VERSION ""

NS_ :

BS_:

BU_: IVI

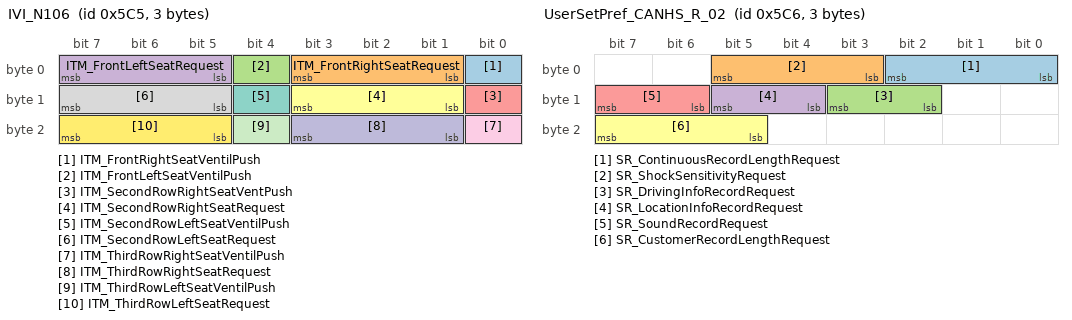
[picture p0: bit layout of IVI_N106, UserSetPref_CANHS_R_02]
BO_ 1477 IVI_N106: 3 IVI
  SG_ ITM_FrontRightSeatVentilPush : 0|1@0+ (1,0) [0|1] "-" Vector__XXX
  SG_ ITM_FrontRightSeatRequest : 3|3@0+ (1,0) [0|0] "" Vector__XXX
  SG_ ITM_FrontLeftSeatVentilPush : 4|1@0+ (1,0) [0|1] "-" Vector__XXX
  SG_ ITM_FrontLeftSeatRequest : 7|3@0+ (1,0) [0|0] "" Vector__XXX
  SG_ ITM_SecondRowRightSeatVentPush : 8|1@0+ (1,0) [0|1] "-" Vector__XXX
  SG_ ITM_SecondRowRightSeatRequest : 11|3@0+ (1,0) [0|0] "" Vector__XXX
  SG_ ITM_SecondRowLeftSeatVentilPush : 12|1@0+ (1,0) [0|1] "-" Vector__XXX
  SG_ ITM_SecondRowLeftSeatRequest : 15|3@0+ (1,0) [0|0] "" Vector__XXX
  SG_ ITM_ThirdRowRightSeatVentilPush : 16|1@0+ (1,0) [0|1] "-" Vector__XXX
  SG_ ITM_ThirdRowRightSeatRequest : 19|3@0+ (1,0) [0|0] "" Vector__XXX
  SG_ ITM_ThirdRowLeftSeatVentilPush : 20|1@0+ (1,0) [0|1] "-" Vector__XXX
  SG_ ITM_ThirdRowLeftSeatRequest : 23|3@0+ (1,0) [0|0] "" Vector__XXX

BO_ 1478 UserSetPref_CANHS_R_02: 3 IVI
  SG_ SR_ContinuousRecordLengthRequest : 2|3@0+ (1,0) [0|0] "" Vector__XXX
  SG_ SR_ShockSensitivityRequest : 5|3@0+ (1,0) [0|0] "" Vector__XXX
  SG_ SR_DrivingInfoRecordRequest : 11|2@0+ (1,0) [0|0] "" Vector__XXX
  SG_ SR_LocationInfoRecordRequest : 13|2@0+ (1,0) [0|0] "" Vector__XXX
  SG_ SR_SoundRecordRequest : 15|2@0+ (1,0) [0|0] "" Vector__XXX
  SG_ SR_CustomerRecordLengthRequest : 23|3@0+ (1,0) [0|0] "" Vector__XXX

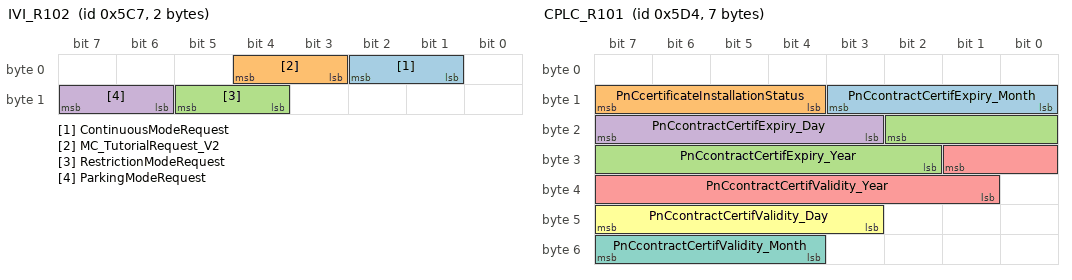
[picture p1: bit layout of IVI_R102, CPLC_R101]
BO_ 1479 IVI_R102: 2 IVI
  SG_ ContinuousModeRequest : 2|2@0+ (1,0) [0|0] "" Vector__XXX
  SG_ MC_TutorialRequest_V2 : 4|2@0+ (1,0) [0|0] "" Vector__XXX
  SG_ RestrictionModeRequest : 13|2@0+ (1,0) [0|0] "" Vector__XXX
  SG_ ParkingModeRequest : 15|2@0+ (1,0) [0|0] "" Vector__XXX

BO_ 1482 IVI_UserSetPref_A2: 8 IVI
  SG_ TSR_OSPActivationRequest2 : 1|2@0+ (1,0) [0|0] "" Vector__XXX
  SG_ TPMS_PressureFrontAxleRequest2 : 7|6@0+ (10,140) [150|760] "kPa" Vector__XXX
  SG_ TPMS_PressureRearAxleRequest2 : 15|6@0+ (10,140) [150|760] "kPa" Vector__XXX
  SG_ LDW_ActivationRequest2 : 17|2@0+ (1,0) [0|0] "" Vector__XXX
  SG_ LDW_VibrationIntensityReq2 : 20|3@0+ (1,0) [0|0] "" Vector__XXX
  SG_ SailingStopActivationRequest2 : 25|2@0+ (1,0) [0|0] "" Vector__XXX
  SG_ AEB_FCWactivationRequest2 : 28|3@0+ (1,0) [0|0] "" Vector__XXX
  SG_ LDW_SensibilityRequest2 : 31|3@0+ (1,0) [0|0] "" Vector__XXX
  SG_ FKP_ActivationRequest2 : 33|2@0+ (1,0) [0|0] "" Vector__XXX
  SG_ MOD_ActivationRequest2 : 35|2@0+ (1,0) [0|0] "" Vector__XXX
  SG_ SonarAutoDisplayRequest2 : 37|2@0+ (1,0) [0|0] "" Vector__XXX
  SG_ DW_ActivationRequest2 : 39|2@0+ (1,0) [0|0] "" Vector__XXX
  SG_ BSWrad_ActivationRequest2 : 41|2@0+ (1,0) [0|0] "" Vector__XXX
  SG_ HFP_DefaultManeuverTypeRequest2 : 44|3@0+ (1,0) [0|0] "" Vector__XXX
  SG_ HandDrivingActivationRequest2 : 47|2@0+ (1,0) [0|0] "" Vector__XXX
  SG_ LKA_ActivationRequest2 : 51|2@0+ (1,0) [0|0] "" Vector__XXX
  SG_ SailingIdleActivationReq2 : 53|2@0+ (1,0) [0|0] "" Vector__XXX
  SG_ CTA_ActivationRequest2 : 59|2@0+ (1,0) [0|0] "" Vector__XXX
  SG_ AFS_ActivationRequest2 : 61|2@0+ (1,0) [0|0] "" Vector__XXX
  SG_ LCA_ActivationRequest2 : 63|2@0+ (1,0) [0|0] "" Vector__XXX

BO_ 1488 ADAS_A110: 8 Vector__XXX
  SG_ OffsetActivation_State : 18|2@0+ (1,0) [0|0] "" IVI
  SG_ OffsetValue_State : 52|5@0+ (1,0) [0|0] "" IVI

BO_ 1490 HUD_A101: 2 Vector__XXX
  SG_ HUD_RotationPositionState : 7|5@0+ (1,0) [0|0] "" IVI
  SG_ HUD_FOTA_status : 15|5@0+ (1,0) [0|0] "" IVI

BO_ 1491 METER_UserSetPref_A1: 8 Vector__XXX
  SG_ ParkAssistVolumeRequest : 7|3@0+ (1,0) [0|0] "" IVI

BO_ 1492 CPLC_R101: 7 Vector__XXX
  SG_ PnCcontractCertifExpiry_Month : 11|4@0+ (1,0) [0|12] "month" IVI
  SG_ PnCcertificateInstallationStatus : 15|4@0+ (1,0) [0|0] "" IVI
  SG_ PnCcontractCertifExpiry_Year : 18|9@0+ (1,2000) [2000|2500] "year" IVI
  SG_ PnCcontractCertifExpiry_Day : 23|5@0+ (1,0) [0|31] "day" IVI
  SG_ PnCcontractCertifValidity_Year : 25|9@0+ (1,2000) [2000|2500] "year" IVI
  SG_ PnCcontractCertifValidity_Day : 47|5@0+ (1,0) [0|31] "day" IVI
  SG_ PnCcontractCertifValidity_Month : 55|4@0+ (1,0) [0|12] "month" IVI

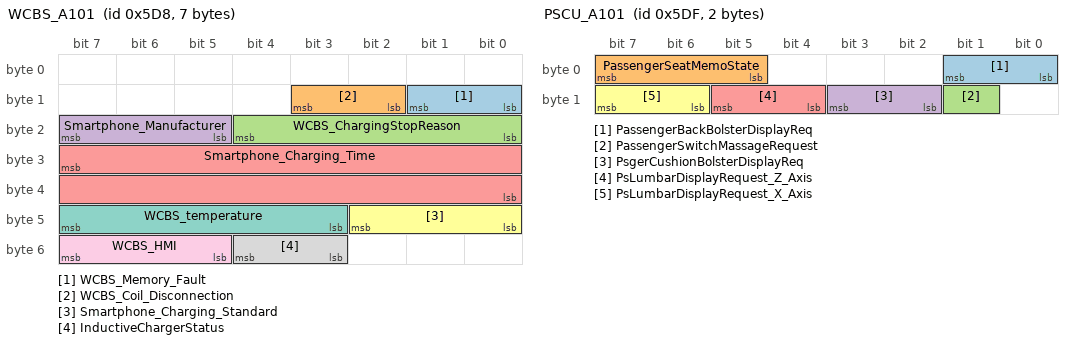
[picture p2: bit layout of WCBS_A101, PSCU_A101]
BO_ 1496 WCBS_A101: 7 Vector__XXX
  SG_ WCBS_Memory_Fault : 9|2@0+ (1,0) [0|0] "" IVI
  SG_ WCBS_Coil_Disconnection : 11|2@0+ (1,0) [0|0] "" IVI
  SG_ WCBS_ChargingStopReason : 20|5@0+ (1,0) [0|0] "" IVI
  SG_ Smartphone_Manufacturer : 23|3@0+ (1,0) [0|0] "" IVI
  SG_ Smartphone_Charging_Time : 31|16@0+ (1,1) [1|36000] "s" IVI
  SG_ Smartphone_Charging_Standard : 42|3@0+ (1,0) [0|0] "" IVI
  SG_ WCBS_temperature : 47|5@0+ (5,0) [0|100] "°C" IVI
  SG_ InductiveChargerStatus : 52|2@0+ (1,0) [0|0] "" IVI
  SG_ WCBS_HMI : 55|3@0+ (1,0) [0|0] "" IVI

BO_ 1498 ADAS_A155: 3 Vector__XXX
  SG_ AD_DistanceDuration : 7|14@0+ (0.1,-0.1) [0|1638] "km" IVI
  SG_ AD_TimeDuration : 9|10@0+ (1,1) [1|1022] "min" IVI

BO_ 1503 PSCU_A101: 2 Vector__XXX
  SG_ PassengerBackBolsterDisplayReq : 1|2@0+ (1,0) [0|0] "" IVI
  SG_ PassengerSeatMemoState : 7|3@0+ (1,0) [0|0] "" IVI
  SG_ PassengerSwitchMassageRequest : 9|1@0+ (1,0) [0|0] "" IVI
  SG_ PsgerCushionBolsterDisplayReq : 11|2@0+ (1,0) [0|0] "" IVI
  SG_ PsLumbarDisplayRequest_Z_Axis : 13|2@0+ (1,0) [0|0] "" IVI
  SG_ PsLumbarDisplayRequest_X_Axis : 15|2@0+ (1,0) [0|0] "" IVI

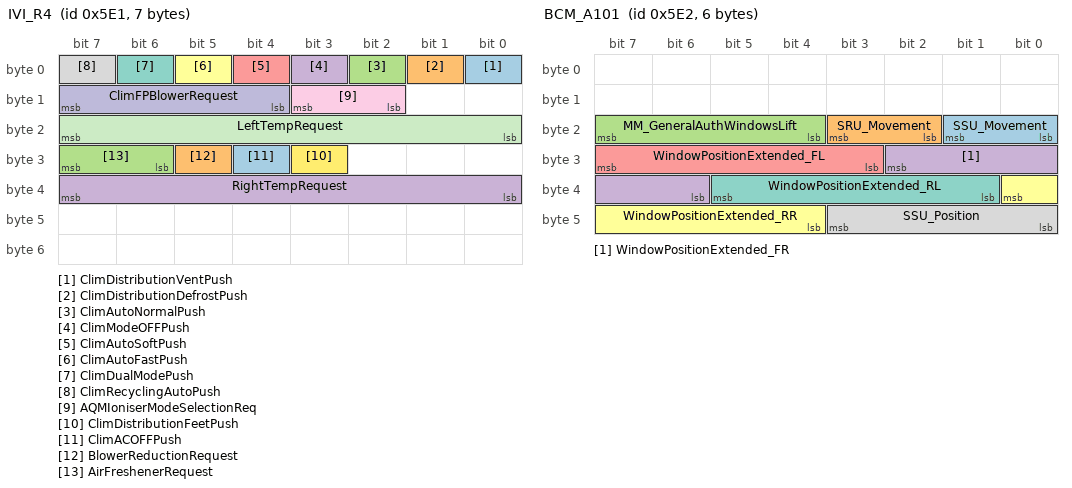
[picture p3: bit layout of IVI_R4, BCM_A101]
BO_ 1505 IVI_R4: 7 IVI
  SG_ ClimDistributionVentPush : 0|1@0+ (1,0) [0|1] "" Vector__XXX
  SG_ ClimDistributionDefrostPush : 1|1@0+ (1,0) [0|1] "" Vector__XXX
  SG_ ClimAutoNormalPush : 2|1@0+ (1,0) [0|1] "" Vector__XXX
  SG_ ClimModeOFFPush : 3|1@0+ (1,0) [0|1] "" Vector__XXX
  SG_ ClimAutoSoftPush : 4|1@0+ (1,0) [0|1] "" Vector__XXX
  SG_ ClimAutoFastPush : 5|1@0+ (1,0) [0|1] "" Vector__XXX
  SG_ ClimDualModePush : 6|1@0+ (1,0) [0|1] "" Vector__XXX
  SG_ ClimRecyclingAutoPush : 7|1@0+ (1,0) [0|1] "" Vector__XXX
  SG_ AQMIoniserModeSelectionReq : 11|2@0+ (1,0) [0|0] "" Vector__XXX
  SG_ ClimFPBlowerRequest : 15|4@0+ (1,0) [0|0] "" Vector__XXX
  SG_ LeftTempRequest : 23|8@0+ (0.5,10) [10|127.5] "°" Vector__XXX
  SG_ ClimDistributionFeetPush : 27|1@0+ (1,0) [0|1] "" Vector__XXX
  SG_ ClimACOFFPush : 28|1@0+ (1,0) [0|1] "" Vector__XXX
  SG_ BlowerReductionRequest : 29|1@0+ (1,0) [0|0] "" Vector__XXX
  SG_ AirFreshenerRequest : 31|2@0+ (1,0) [0|0] "" Vector__XXX
  SG_ RightTempRequest : 39|8@0+ (0.5,10) [10|127.5] "°" Vector__XXX

BO_ 1506 BCM_A101: 6 Vector__XXX
  SG_ SSU_Movement : 17|2@0+ (1,0) [0|0] "" IVI
  SG_ SRU_Movement : 19|2@0+ (1,0) [0|0] "" IVI
  SG_ MM_GeneralAuthWindowsLift : 23|4@0+ (1,0) [0|0] "" IVI
  SG_ WindowPositionExtended_FR : 26|5@0+ (1,0) [0|0] "" IVI
  SG_ WindowPositionExtended_FL : 31|5@0+ (1,0) [0|0] "" IVI
  SG_ WindowPositionExtended_RR : 32|5@0+ (1,0) [0|0] "" IVI
  SG_ WindowPositionExtended_RL : 37|5@0+ (1,0) [0|0] "" IVI
  SG_ SSU_Position : 43|4@0+ (1,0) [0|0] "" IVI

BO_ 1508 BCM_A115: 8 Vector__XXX
  SG_ RESPreSoak_ProgStatus : 9|2@0+ (1,0) [0|0] "" IVI
  SG_ RES_ProgrammationForbidden : 60|1@0+ (1,0) [0|0] "" IVI

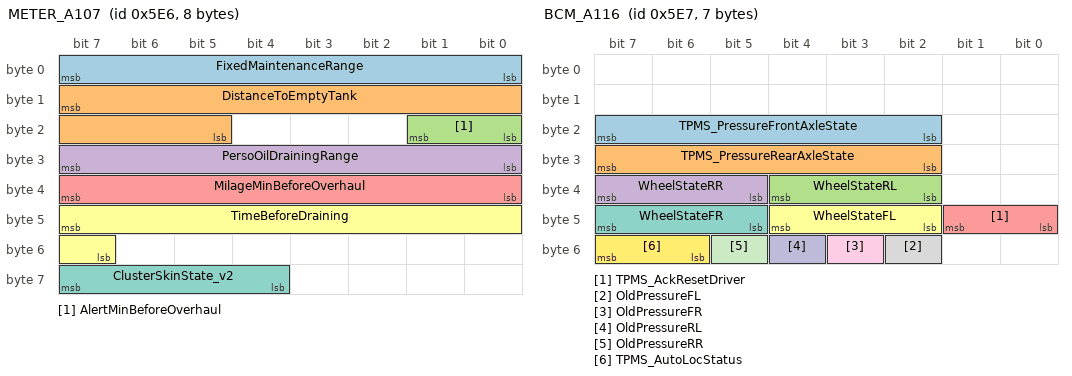
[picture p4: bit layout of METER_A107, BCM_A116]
BO_ 1510 METER_A107: 8 Vector__XXX
  SG_ FixedMaintenanceRange : 7|8@0+ (250,0) [0|63250] "km" IVI
  SG_ DistanceToEmptyTank : 15|11@0+ (1,0) [0|2046] "km" IVI
  SG_ AlertMinBeforeOverhaul : 17|2@0+ (1,0) [0|0] "" IVI
  SG_ PersoOilDrainingRange : 31|8@0+ (250,0) [0|63500] "km" IVI
  SG_ MilageMinBeforeOverhaul : 39|8@0+ (250,0) [0|63500] "km" IVI
  SG_ TimeBeforeDraining : 47|9@0+ (1,0) [0|511] "day" IVI
  SG_ ClusterSkinState_v2 : 63|4@0+ (1,0) [0|0] "" IVI

BO_ 1511 BCM_A116: 7 Vector__XXX
  SG_ TPMS_PressureFrontAxleState : 23|6@0+ (10,150) [150|760] "kPa" IVI
  SG_ TPMS_PressureRearAxleState : 31|6@0+ (10,150) [150|760] "kPa" IVI
  SG_ WheelStateRL : 36|3@0+ (1,0) [0|0] "" IVI
  SG_ WheelStateRR : 39|3@0+ (1,0) [0|0] "" IVI
  SG_ TPMS_AckResetDriver : 41|2@0+ (1,0) [0|0] "" IVI
  SG_ WheelStateFL : 44|3@0+ (1,0) [0|0] "" IVI
  SG_ WheelStateFR : 47|3@0+ (1,0) [0|0] "" IVI
  SG_ OldPressureFL : 50|1@0+ (1,0) [0|0] "" IVI
  SG_ OldPressureFR : 51|1@0+ (1,0) [0|0] "" IVI
  SG_ OldPressureRL : 52|1@0+ (1,0) [0|0] "" IVI
  SG_ OldPressureRR : 53|1@0+ (1,0) [0|0] "" IVI
  SG_ TPMS_AutoLocStatus : 55|2@0+ (1,0) [0|0] "" IVI

BO_ 1516 METER_UserSetPref_A2: 8 Vector__XXX
  SG_ LDW_SoundLevelRequest_v2 : 23|3@0+ (1,0) [0|0] "" IVI

BO_ 1519 IVI_A101: 8 IVI
  SG_ UserSettingCopySource : 2|3@0+ (1,0) [0|0] "" Vector__XXX
  SG_ UserSettingCopyTarget : 5|3@0+ (1,0) [0|0] "" Vector__XXX
  SG_ User5_RegistrationState : 8|1@0+ (1,0) [0|0] "" Vector__XXX
  SG_ User4_RegistrationState : 9|1@0+ (1,0) [0|0] "" Vector__XXX
  SG_ KeyLinkInitializationState : 10|1@0+ (1,0) [0|0] "" Vector__XXX
  SG_ KeyLinkActivationState : 11|1@0+ (1,0) [0|0] "" Vector__XXX
  SG_ User3_RegistrationState : 12|1@0+ (1,0) [0|0] "" Vector__XXX
  SG_ User2_RegistrationState : 13|1@0+ (1,0) [0|0] "" Vector__XXX
  SG_ User1_RegistrationState : 14|1@0+ (1,0) [0|0] "" Vector__XXX
  SG_ UserSettingCopyRequest : 15|1@0+ (1,0) [0|0] "" Vector__XXX
  SG_ ClimLinkFreshRecyAndAutoPush : 16|1@0+ (1,0) [0|1] "" Vector__XXX
  SG_ ADA1ActivationRequest2 : 18|2@0+ (1,0) [0|0] "" Vector__XXX
  SG_ ASAactivationRequest2 : 20|2@0+ (1,0) [0|0] "" Vector__XXX
  SG_ CurrentUserState_v2 : 23|3@0+ (1,0) [0|0] "" Vector__XXX
  SG_ SuspensionSettingRequest2 : 27|3@0+ (1,0) [0|0] "" Vector__XXX
  SG_ SteeringSettingRequest2_v2 : 31|4@0+ (1,0) [0|0] "" Vector__XXX
  SG_ MC_PositionChangeRequest : 35|4@0+ (1,0) [0|0] "" Vector__XXX
  SG_ PowerTrainSettingRequest2 : 39|4@0+ (1,0) [0|0] "" Vector__XXX
  SG_ ClimAQSSensitivityRequest : 42|3@0+ (1,0) [0|0] "" Vector__XXX
  SG_ UserProfileResetRequest : 45|3@0+ (1,0) [0|0] "" Vector__XXX
  SG_ MC_ActivationRequest : 47|2@0+ (1,0) [0|0] "" Vector__XXX
  SG_ MC_PositionRecallRequest : 51|4@0+ (1,0) [0|0] "" Vector__XXX
  SG_ VMCSettingRequest : 55|4@0+ (1,0) [0|0] "" Vector__XXX
  SG_ MC_PositionCalculate : 59|4@0+ (1,0) [0|0] "" Vector__XXX
  SG_ MC_PositionSaveRequest : 63|4@0+ (1,0) [0|0] "" Vector__XXX

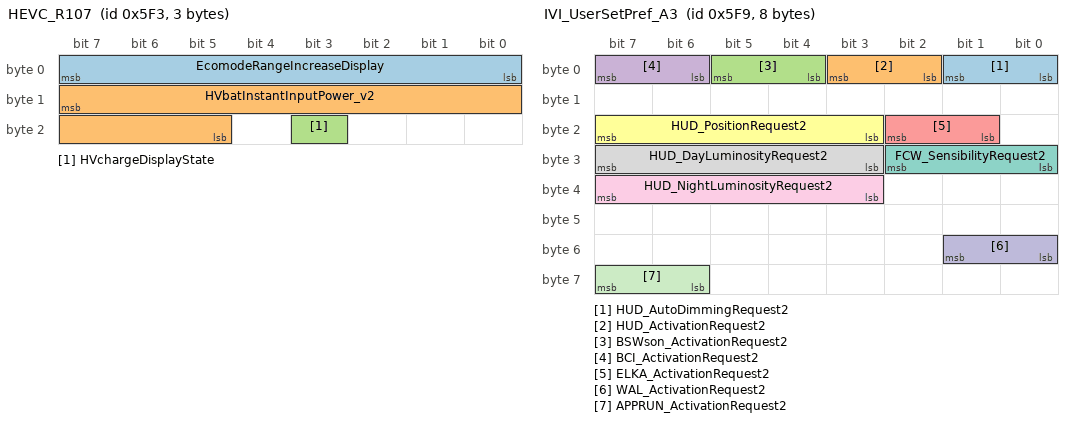
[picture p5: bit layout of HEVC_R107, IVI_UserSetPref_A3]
BO_ 1523 HEVC_R107: 3 Vector__XXX
  SG_ EcomodeRangeIncreaseDisplay : 7|8@0+ (1,0) [0|255] "" IVI
  SG_ HVbatInstantInputPower_v2 : 15|11@0+ (0.25,-255) [-255|255] "kW" IVI
  SG_ HVchargeDisplayState : 19|1@0+ (1,0) [0|0] "" IVI

BO_ 1529 IVI_UserSetPref_A3: 8 IVI
  SG_ HUD_AutoDimmingRequest2 : 1|2@0+ (1,0) [0|0] "" Vector__XXX
  SG_ HUD_ActivationRequest2 : 3|2@0+ (1,0) [0|0] "" Vector__XXX
  SG_ BSWson_ActivationRequest2 : 5|2@0+ (1,0) [0|0] "" Vector__XXX
  SG_ BCI_ActivationRequest2 : 7|2@0+ (1,0) [0|0] "" Vector__XXX
  SG_ ELKA_ActivationRequest2 : 18|2@0+ (1,0) [0|0] "" Vector__XXX
  SG_ HUD_PositionRequest2 : 23|5@0+ (1,0) [0|0] "" Vector__XXX
  SG_ FCW_SensibilityRequest2 : 26|3@0+ (1,0) [0|0] "" Vector__XXX
  SG_ HUD_DayLuminosityRequest2 : 31|5@0+ (1,0) [0|0] "" Vector__XXX
  SG_ HUD_NightLuminosityRequest2 : 39|5@0+ (1,0) [0|0] "" Vector__XXX
  SG_ WAL_ActivationRequest2 : 49|2@0+ (1,0) [0|0] "" Vector__XXX
  SG_ APPRUN_ActivationRequest2 : 63|2@0+ (1,0) [0|0] "" Vector__XXX

BO_ 1531 IVI_UserSetPref_A1: 8 IVI
  SG_ AutoFrontWiperActivationRequest2 : 1|2@0+ (1,0) [0|0] "" Vector__XXX
  SG_ AHL_ActivationRequest2 : 3|2@0+ (1,0) [0|0] "" Vector__XXX
  SG_ ParkAssistVolumeRequest2 : 7|3@0+ (1,0) [0|0] "" Vector__XXX
  SG_ IKeyAccessActivationRequest2 : 9|2@0+ (1,0) [0|0] "" Vector__XXX
  SG_ FrontRearWiperDropRequest2 : 11|2@0+ (1,0) [0|0] "" Vector__XXX
  SG_ FrontParkAssistActivationReq2 : 13|2@0+ (1,0) [0|0] "" Vector__XXX
  SG_ AutoRearWiperActivationRequest2 : 15|2@0+ (1,0) [0|0] "" Vector__XXX
  SG_ WGSactivationRequest2 : 16|2@0+ (1,0) [0|0] "" Vector__XXX
  SG_ SingleDoorOpeningActivationReq2 : 18|2@0+ (1,0) [0|0] "" Vector__XXX
  SG_ RearParkAssistActivationReq2 : 20|2@0+ (1,0) [0|0] "" Vector__XXX
  SG_ AutoLightSensitivityRequest2 : 23|3@0+ (1,0) [0|0] "" Vector__XXX
  SG_ AutoReLockActivationReq2 : 25|2@0+ (1,0) [0|0] "" Vector__XXX
  SG_ MotorwayFlashersNumberRequest2 : 28|3@0+ (1,0) [0|0] "" Vector__XXX
  SG_ AutoFMHactivationRequest2 : 30|2@0+ (1,0) [0|0] "" Vector__XXX
  SG_ SilentModeActivationRequest2 : 33|2@0+ (1,0) [0|0] "" Vector__XXX
  SG_ AutoLockActivationReq2 : 36|3@0+ (1,0) [0|0] "" Vector__XXX
  SG_ AutoUnLockActivationReq2 : 39|3@0+ (1,0) [0|0] "" Vector__XXX
  SG_ WAC_APRUN_ActivationRequest2 : 41|2@0+ (1,0) [0|0] "" Vector__XXX
  SG_ ParkAssistSensitivityRequest2 : 44|3@0+ (1,0) [0|0] "" Vector__XXX
  SG_ AutoFoldingActivationRequest2 : 47|3@0+ (1,0) [0|0] "" Vector__XXX
  SG_ PredictiveShiftActivationRequest2 : 49|2@0+ (1,0) [0|0] "" Vector__XXX
  SG_ AirCondEcoActivationRequest2 : 51|2@0+ (1,0) [0|0] "" Vector__XXX
  SG_ CruiseEcoActivationRequest2 : 55|2@0+ (1,0) [0|0] "" Vector__XXX
  SG_ AutoFMHdurationRequest2 : 59|4@0+ (1,0) [0|0] "" Vector__XXX
  SG_ AmbientLightingPatternRequest2 : 61|2@0+ (1,0) [0|0] "" Vector__XXX
  SG_ ISS_EcoActivationRequest2 : 63|2@0+ (1,0) [0|0] "" Vector__XXX

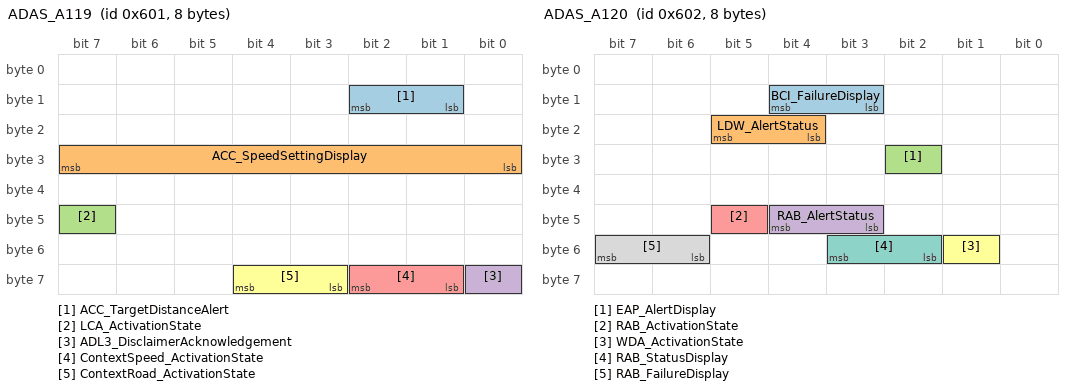
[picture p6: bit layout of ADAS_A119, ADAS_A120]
BO_ 1537 ADAS_A119: 8 Vector__XXX
  SG_ ACC_TargetDistanceAlert : 10|2@0+ (1,0) [0|0] "" IVI
  SG_ ACC_SpeedSettingDisplay : 31|8@0+ (1,0) [0|255] "wu" IVI
  SG_ LCA_ActivationState : 47|1@0+ (1,0) [0|0] "" IVI
  SG_ ADL3_DisclaimerAcknowledgement : 56|1@0+ (1,0) [0|0] "" IVI
  SG_ ContextSpeed_ActivationState : 58|2@0+ (1,0) [0|0] "" IVI
  SG_ ContextRoad_ActivationState : 60|2@0+ (1,0) [0|0] "" IVI

BO_ 1538 ADAS_A120: 8 Vector__XXX
  SG_ BCI_FailureDisplay : 12|2@0+ (1,0) [0|0] "" IVI
  SG_ LDW_AlertStatus : 21|2@0+ (1,0) [0|0] "" IVI
  SG_ EAP_AlertDisplay : 26|1@0+ (1,0) [0|0] "" IVI
  SG_ RAB_AlertStatus : 44|2@0+ (1,0) [0|0] "" IVI
  SG_ RAB_ActivationState : 45|1@0+ (1,0) [0|0] "" IVI
  SG_ WDA_ActivationState : 49|1@0+ (1,0) [0|0] "" IVI
  SG_ RAB_StatusDisplay : 51|2@0+ (1,0) [0|0] "" IVI
  SG_ RAB_FailureDisplay : 55|2@0+ (1,0) [0|0] "" IVI

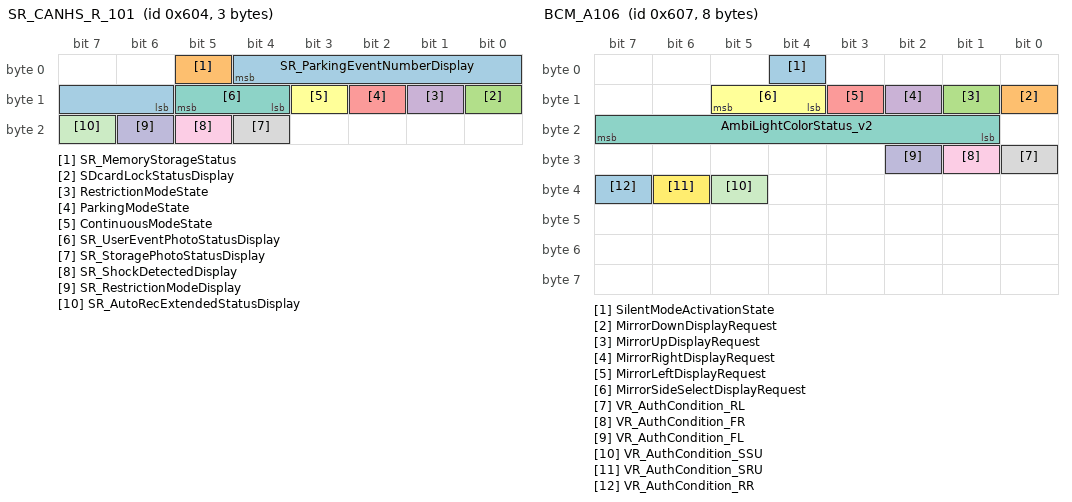
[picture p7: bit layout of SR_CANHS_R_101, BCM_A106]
BO_ 1540 SR_CANHS_R_101: 3 Vector__XXX
  SG_ SR_ParkingEventNumberDisplay : 4|7@0+ (1,0) [0|100] "-" IVI
  SG_ SR_MemoryStorageStatus : 5|1@0+ (1,0) [0|0] "" IVI
  SG_ SDcardLockStatusDisplay : 8|1@0+ (1,0) [0|0] "" IVI
  SG_ RestrictionModeState : 9|1@0+ (1,0) [0|0] "" IVI
  SG_ ParkingModeState : 10|1@0+ (1,0) [0|0] "" IVI
  SG_ ContinuousModeState : 11|1@0+ (1,0) [0|0] "" IVI
  SG_ SR_UserEventPhotoStatusDisplay : 13|2@0+ (1,0) [0|0] "" IVI
  SG_ SR_StoragePhotoStatusDisplay : 20|1@0+ (1,0) [0|0] "" IVI
  SG_ SR_ShockDetectedDisplay : 21|1@0+ (1,0) [0|0] "" IVI
  SG_ SR_RestrictionModeDisplay : 22|1@0+ (1,0) [0|0] "" IVI
  SG_ SR_AutoRecExtendedStatusDisplay : 23|1@0+ (1,0) [0|0] "" IVI

BO_ 1543 BCM_A106: 8 Vector__XXX
  SG_ SilentModeActivationState : 4|1@0+ (1,0) [0|0] "" IVI
  SG_ MirrorDownDisplayRequest : 8|1@0+ (1,0) [0|0] "" IVI
  SG_ MirrorUpDisplayRequest : 9|1@0+ (1,0) [0|0] "" IVI
  SG_ MirrorRightDisplayRequest : 10|1@0+ (1,0) [0|0] "" IVI
  SG_ MirrorLeftDisplayRequest : 11|1@0+ (1,0) [0|0] "" IVI
  SG_ MirrorSideSelectDisplayRequest : 13|2@0+ (1,0) [0|0] "" IVI
  SG_ AmbiLightColorStatus_v2 : 23|7@0+ (1,0) [0|0] "" IVI
  SG_ VR_AuthCondition_RL : 24|1@0+ (1,0) [0|0] "" IVI
  SG_ VR_AuthCondition_FR : 25|1@0+ (1,0) [0|0] "" IVI
  SG_ VR_AuthCondition_FL : 26|1@0+ (1,0) [0|0] "" IVI
  SG_ VR_AuthCondition_SSU : 37|1@0+ (1,0) [0|0] "" IVI
  SG_ VR_AuthCondition_SRU : 38|1@0+ (1,0) [0|0] "" IVI
  SG_ VR_AuthCondition_RR : 39|1@0+ (1,0) [0|0] "" IVI

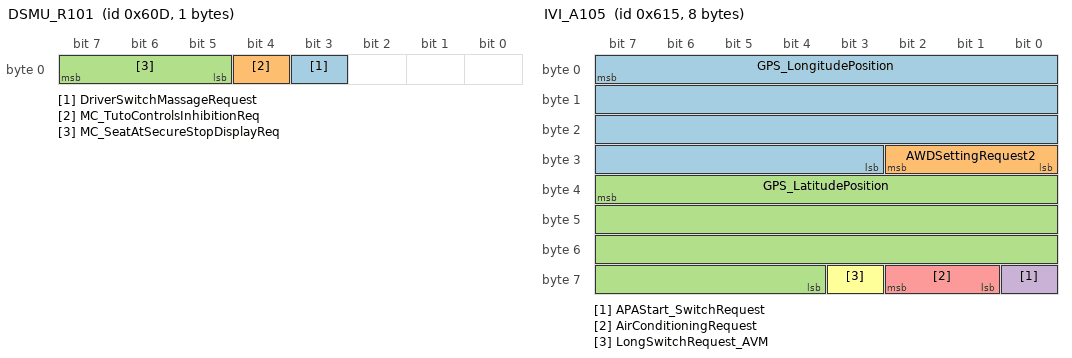
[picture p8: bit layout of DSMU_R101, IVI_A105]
BO_ 1549 DSMU_R101: 1 Vector__XXX
  SG_ DriverSwitchMassageRequest : 3|1@0+ (1,0) [0|0] "" IVI
  SG_ MC_TutoControlsInhibitionReq : 4|1@0+ (1,0) [0|0] "" IVI
  SG_ MC_SeatAtSecureStopDisplayReq : 7|3@0+ (1,0) [0|0] "" IVI

BO_ 1553 HVAC_A106: 8 Vector__XXX
  SG_ SecondRowCentralSeatStatus : 2|3@0+ (1,0) [0|0] "" IVI
  SG_ ClimForcedFreshDisplayStatus : 6|1@0+ (1,0) [0|0] "" IVI
  SG_ ClimForcedRecyDisplayStatus : 7|1@0+ (1,0) [0|0] "" IVI
  SG_ ClimForcedFreshDisplay : 9|2@0+ (1,0) [0|0] "" IVI
  SG_ ClimAQSSensitivityDisplay : 12|3@0+ (1,0) [0|0] "" IVI
  SG_ ClimExternalAirPollutionDisplay : 15|3@0+ (1,0) [0|0] "" IVI
  SG_ ClimRearDefrostDisplayStatus : 16|1@0+ (1,0) [0|0] "" IVI
  SG_ ClimExternAirPollutioDispStatus : 17|1@0+ (1,0) [0|0] "" IVI
  SG_ ClimLinkPriorityFLSeatAutoDisp : 20|3@0+ (1,0) [0|0] "" IVI
  SG_ ClimLinkPriorityFRSeatAutoDisp : 23|3@0+ (1,0) [0|0] "" IVI
  SG_ FrontRightSeatDisplayStatus : 24|1@0+ (1,0) [0|0] "" IVI
  SG_ FrontRightSeatStatus : 27|3@0+ (1,0) [0|0] "" IVI
  SG_ FrontLeftSeatStatus : 30|3@0+ (1,0) [0|0] "" IVI
  SG_ FrontLeftSeatDisplayStatus : 31|1@0+ (1,0) [0|0] "" IVI
  SG_ SecondRowLeftSeatAutoDisplay : 33|2@0+ (1,0) [0|0] "" IVI
  SG_ SecondRowRightSeatAutoDisplay : 35|2@0+ (1,0) [0|0] "" IVI
  SG_ FrontLeftSeatAutoDisplay : 37|2@0+ (1,0) [0|0] "" IVI
  SG_ FrontRightSeatAutoDisplay : 39|2@0+ (1,0) [0|0] "" IVI
  SG_ ThirdRowLeftSeatAutoDisplay : 41|2@0+ (1,0) [0|0] "" IVI
  SG_ ThirdRowRightSeatDisplayStatus : 42|1@0+ (1,0) [0|0] "" IVI
  SG_ ThirdRowLeftSeatDisplayStatus : 43|1@0+ (1,0) [0|0] "" IVI
  SG_ ThirdRowRightSeatAutoDisplay : 45|2@0+ (1,0) [0|0] "" IVI
  SG_ SecondRowRightSeatDisplayStatus : 46|1@0+ (1,0) [0|0] "" IVI
  SG_ SecondRowLeftSeatDisplayStatus : 47|1@0+ (1,0) [0|0] "" IVI
  SG_ ClimCabinTempDisplayUnit : 48|1@0+ (1,0) [0|0] "" IVI
  SG_ ClimLastFuncModifiedByCustomer_v2 : 55|4@0+ (1,0) [0|0] "" IVI
  SG_ ClimACmaxDisplay : 63|2@0+ (1,0) [0|0] "" IVI

BO_ 1557 IVI_A105: 8 IVI
  SG_ GPS_LongitudePosition : 7|29@0+ (0.00010,-18000) [-18000|17959.999] "min" Vector__XXX
  SG_ AWDSettingRequest2 : 26|3@0+ (1,0) [0|0] "" Vector__XXX
  SG_ GPS_LatitudePosition : 39|28@0+ (0.00010,-9000) [-9000|8959.999] "min" Vector__XXX
  SG_ APAStart_SwitchRequest : 56|1@0+ (1,0) [0|0] "" Vector__XXX
  SG_ AirConditioningRequest : 58|2@0+ (1,0) [0|0] "" Vector__XXX
  SG_ LongSwitchRequest_AVM : 59|1@0+ (1,0) [0|0] "" Vector__XXX

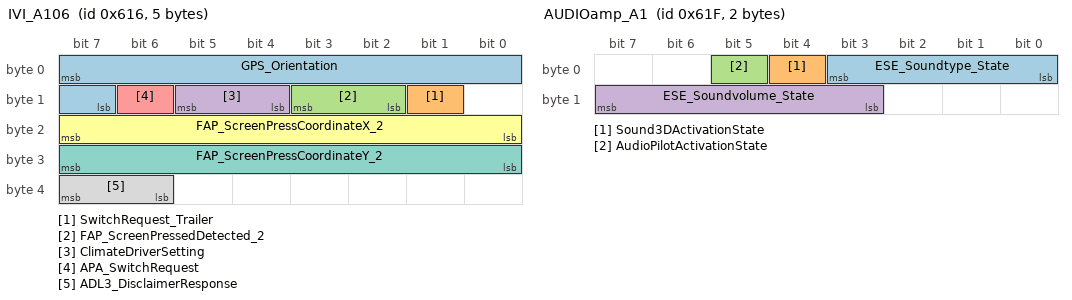
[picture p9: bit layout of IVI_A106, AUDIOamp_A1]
BO_ 1558 IVI_A106: 5 IVI
  SG_ GPS_Orientation : 7|9@0+ (1,-180) [-180|179] "deg" Vector__XXX
  SG_ SwitchRequest_Trailer : 9|1@0+ (1,0) [0|0] "" Vector__XXX
  SG_ FAP_ScreenPressedDetected_2 : 11|2@0+ (1,0) [0|0] "" Vector__XXX
  SG_ ClimateDriverSetting : 13|2@0+ (1,0) [0|0] "" Vector__XXX
  SG_ APA_SwitchRequest : 14|1@0+ (1,0) [0|0] "" Vector__XXX
  SG_ FAP_ScreenPressCoordinateX_2 : 23|8@0+ (1,0) [0|255] "" Vector__XXX
  SG_ FAP_ScreenPressCoordinateY_2 : 31|8@0+ (1,0) [0|255] "" Vector__XXX
  SG_ ADL3_DisclaimerResponse : 39|2@0+ (1,0) [0|0] "" Vector__XXX

BO_ 1561 HEVC_A131: 8 Vector__XXX
  SG_ HVB_MaxCapacity_HEVC_v2 : 9|16@0+ (0.1,0) [0|6553.5] "kWh" IVI

BO_ 1564 HEVC_A135: 7 Vector__XXX
  SG_ ReacheableUSOCatDepartureTime : 7|7@0+ (1,0) [0|100] "%" IVI

BO_ 1567 AUDIOamp_A1: 2 Vector__XXX
  SG_ ESE_Soundtype_State : 3|4@0+ (1,0) [0|0] "" IVI
  SG_ Sound3DActivationState : 4|1@0+ (1,0) [0|0] "" IVI
  SG_ AudioPilotActivationState : 5|1@0+ (1,0) [0|0] "" IVI
  SG_ ESE_Soundvolume_State : 15|5@0+ (1,0) [0|0] "" IVI

BO_ 1568 HEVC_A35: 5 Vector__XXX
  SG_ EcoNavDistanceSaving : 7|17@0+ (0.1,0) [0|10000] "wu" IVI

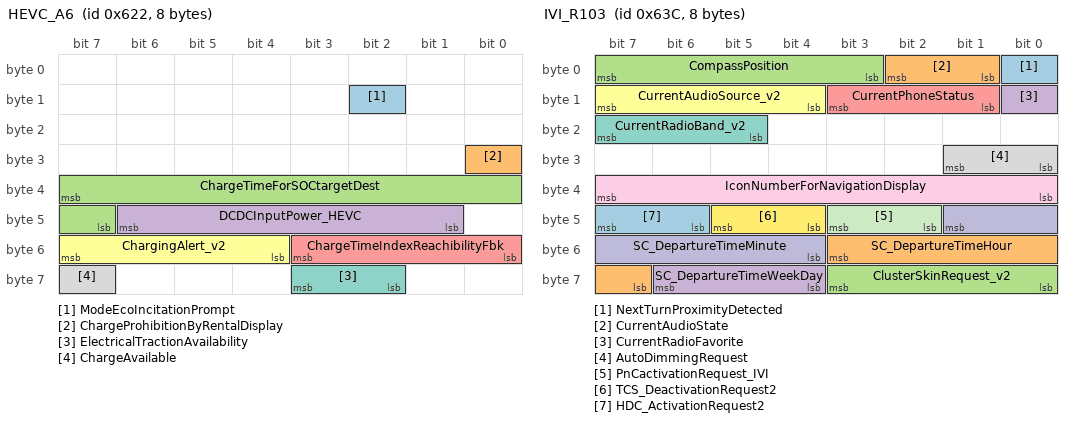
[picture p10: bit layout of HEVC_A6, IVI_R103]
BO_ 1570 HEVC_A6: 8 Vector__XXX
  SG_ ModeEcoIncitationPrompt : 10|1@0+ (1,0) [0|0] "" IVI
  SG_ ChargeProhibitionByRentalDisplay : 24|1@0+ (1,0) [0|0] "" IVI
  SG_ ChargeTimeForSOCtargetDest : 39|9@0+ (5,0) [0|2555] "min" IVI
  SG_ DCDCInputPower_HEVC : 46|6@0+ (0.1,0) [0|6] "kW" IVI
  SG_ ChargeTimeIndexReachibilityFbk : 51|4@0+ (1,0) [0|0] "" IVI
  SG_ ChargingAlert_v2 : 55|4@0+ (1,0) [0|0] "" IVI
  SG_ ElectricalTractionAvailability : 59|2@0+ (1,0) [0|0] "" IVI
  SG_ ChargeAvailable : 63|1@0+ (1,0) [0|0] "" IVI

BO_ 1572 HEVC_R105: 4 Vector__XXX
  SG_ TotalConsumption_LastTrip : 7|12@0+ (0.1,0) [0|409.4] "kWh" IVI
  SG_ TotalRecovery_LastTrip : 11|12@0+ (0.1,0) [0|409.4] "kWh" IVI

BO_ 1578 DMC_A101: 4 Vector__XXX
  SG_ DMC_ActivationState : 9|2@0+ (1,0) [0|0] "" IVI
  SG_ Drowsy_AlertActivationState : 15|2@0+ (1,0) [0|0] "" IVI

BO_ 1593 HVAC_N101: 8 Vector__XXX
  SG_ ITM_FrontRearDefrostTypeConfig : 2|3@0+ (1,0) [0|0] "" IVI
  SG_ ITM_ControlPanelTypeConfig : 3|1@0+ (1,0) [0|0] "" IVI
  SG_ ITM_TempControlTypeConfig : 5|2@0+ (1,0) [0|0] "" IVI
  SG_ ITM_TempRangeMinMaxConfig : 6|1@0+ (1,0) [0|0] "" IVI
  SG_ ITM_VariableAirFlowConfig : 7|1@0+ (1,0) [0|0] "" IVI
  SG_ ITM_TemperatureRangeConfig : 14|7@0+ (1,0) [0|127] "°" IVI
  SG_ ITM_DriverZoneConfig : 15|1@0+ (1,0) [0|0] "" IVI
  SG_ ITM_SyncModeTypeConfig : 18|3@0+ (1,0) [0|0] "" IVI
  SG_ ITM_FlowDistrTypeConfig : 20|2@0+ (1,0) [0|0] "" IVI
  SG_ ITM_BlowingZoneTypeConfig : 22|2@0+ (1,0) [0|0] "" IVI
  SG_ ITM_HumiditySensorConfig : 23|1@0+ (1,0) [0|0] "" IVI
  SG_ ITM_LeftBlowingMaxSpeedConfig : 27|4@0+ (1,0) [0|14] "" IVI
  SG_ ITM_RightBlowingMaxSpeedConfig : 31|4@0+ (1,0) [0|14] "" IVI
  SG_ ITM_ACControlTypeConfig : 33|2@0+ (1,0) [0|0] "" IVI
  SG_ ITM_AutoControlTypeConfig : 36|3@0+ (1,0) [0|0] "" IVI
  SG_ ITM_IdleStopHVACPriorityConfig : 37|1@0+ (1,0) [0|0] "" IVI
  SG_ ITM_ForestConfig : 38|1@0+ (1,0) [0|0] "" IVI
  SG_ ITM_AromaConfig : 39|1@0+ (1,0) [0|0] "" IVI
  SG_ ITM_RearLeftBlowMaxSpeedConfig : 43|4@0+ (1,0) [0|14] "" IVI
  SG_ ITM_RearRightBlowMaxSpeedConfig : 47|4@0+ (1,0) [0|14] "" IVI
  SG_ ITM_AQSMaxLevelConfig : 50|3@0+ (1,0) [0|0] "" IVI
  SG_ ITM_RecyclingTypeConfig : 53|3@0+ (1,0) [0|0] "" IVI
  SG_ ITM_TrimHeaterConfig : 54|1@0+ (1,0) [0|0] "" IVI
  SG_ ITM_AirScarfConfig : 55|1@0+ (1,0) [0|0] "" IVI
  SG_ ITM_FrontSeatHeatVentilConfig : 57|2@0+ (1,0) [0|0] "" IVI
  SG_ ITM_SecondRowSeatHeatVentConfig : 59|2@0+ (1,0) [0|0] "" IVI
  SG_ ITM_ThirdRowSeatHeatVentConfig : 61|2@0+ (1,0) [0|0] "" IVI
  SG_ ITM_IRsensorConfig : 62|1@0+ (1,0) [0|0] "" IVI
  SG_ ITM_AirQualitySensorConfig : 63|1@0+ (1,0) [0|0] "" IVI

BO_ 1594 HVAC_N102: 1 Vector__XXX
  SG_ ITM_EVHeaterControlConfig : 0|1@0+ (1,0) [0|0] "" IVI
  SG_ ITM_HeatedSteeringWheelConfig : 2|2@0+ (1,0) [0|0] "" IVI

BO_ 1595 IVI_A114: 8 IVI
  SG_ FOTA_ProgValueRequest : 5|11@0+ (1,0) [0|1440] "min" Vector__XXX
  SG_ TrailerGuidelineActivationRequest : 7|2@0+ (1,0) [0|0] "" Vector__XXX
  SG_ AmbientLightingColor_v2 : 10|7@0+ (1,0) [0|0] "" Vector__XXX
  SG_ HUD_RotationPositionRequest2 : 19|5@0+ (1,0) [0|0] "" Vector__XXX
  SG_ AVM_GuidelinesActivationRequest2 : 25|3@0+ (1,0) [0|0] "" Vector__XXX
  SG_ OffsetValue_Request2 : 30|5@0+ (1,0) [0|0] "" Vector__XXX
  SG_ AmbientLightingAreaADReq : 32|2@0+ (1,0) [0|0] "" Vector__XXX
  SG_ VolumAlarmActivationRequest2 : 35|3@0+ (1,0) [0|0] "" Vector__XXX
  SG_ ContextSpeed_ActivationRequest2 : 38|3@0+ (1,0) [0|0] "" Vector__XXX
  SG_ PreferedLaneAssist_Request2 : 40|2@0+ (1,0) [0|0] "" Vector__XXX
  SG_ OffsetActivation_Request2 : 42|2@0+ (1,0) [0|0] "" Vector__XXX
  SG_ FOTA_ProgRequest : 44|2@0+ (1,0) [0|0] "" Vector__XXX
  SG_ ContextRoad_ActivationRequest2 : 46|2@0+ (1,0) [0|0] "" Vector__XXX
  SG_ Drowsy_AlertActivationRequest2 : 49|2@0+ (1,0) [0|0] "" Vector__XXX
  SG_ RearViewRVC_CancelReason_RER : 50|1@0+ (1,0) [0|0] "" Vector__XXX
  SG_ ZoomAutoActivationRequest2 : 52|2@0+ (1,0) [0|0] "" Vector__XXX
  SG_ RearViewRVC_CancelReason : 54|2@0+ (1,0) [0|0] "" Vector__XXX
  SG_ HVbatteryWarmingRequest : 57|2@0+ (1,0) [0|0] "" Vector__XXX
  SG_ OSE_ActivationRequest2 : 59|2@0+ (1,0) [0|0] "" Vector__XXX
  SG_ DMC_ActivationRequest2 : 61|2@0+ (1,0) [0|0] "" Vector__XXX
  SG_ VirtualKeyActivationRequest : 63|2@0+ (1,0) [0|0] "" Vector__XXX

BO_ 1596 IVI_R103: 8 IVI
  SG_ NextTurnProximityDetected : 0|1@0+ (1,0) [0|0] "" Vector__XXX
  SG_ CurrentAudioState : 2|2@0+ (1,0) [0|0] "" Vector__XXX
  SG_ CompassPosition : 7|5@0+ (1,0) [0|31] "wu" Vector__XXX
  SG_ CurrentRadioFavorite : 8|1@0+ (1,0) [0|0] "" Vector__XXX
  SG_ CurrentPhoneStatus : 11|3@0+ (1,0) [0|0] "" Vector__XXX
  SG_ CurrentAudioSource_v2 : 15|4@0+ (1,0) [0|0] "" Vector__XXX
  SG_ CurrentRadioBand_v2 : 23|3@0+ (1,0) [0|0] "" Vector__XXX
  SG_ AutoDimmingRequest : 25|2@0+ (1,0) [0|0] "" Vector__XXX
  SG_ IconNumberForNavigationDisplay : 39|8@0+ (1,0) [0|255] "wu" Vector__XXX
  SG_ SC_DepartureTimeMinute : 41|6@0+ (1,0) [0|59] "min" Vector__XXX
  SG_ PnCactivationRequest_IVI : 43|2@0+ (1,0) [0|0] "" Vector__XXX
  SG_ TCS_DeactivationRequest2 : 45|2@0+ (1,0) [0|0] "" Vector__XXX
  SG_ HDC_ActivationRequest2 : 47|2@0+ (1,0) [0|0] "" Vector__XXX
  SG_ SC_DepartureTimeHour : 51|5@0+ (1,0) [0|23] "h" Vector__XXX
  SG_ ClusterSkinRequest_v2 : 59|4@0+ (1,0) [0|0] "" Vector__XXX
  SG_ SC_DepartureTimeWeekDay : 62|3@0+ (1,0) [0|0] "" Vector__XXX

BO_ 1599 SRRR_A107: 1 Vector__XXX
  SG_ CTA_ActivationState : 7|1@0+ (1,0) [0|0] "" IVI

BO_ 1616 SONAR_A122: 2 Vector__XXX
  SG_ APA_WarningDisplayRequest2 : 7|6@0+ (1,0) [0|0] "" IVI
  SG_ APA_ScanInfo2 : 12|3@0+ (1,0) [0|0] "" IVI

BO_ 1620 HEVC_A37: 8 Vector__XXX
  SG_ FreeDistanceZEVSinceECOreset : 15|13@0+ (0.1,0) [0|800] "wu" IVI
  SG_ AverageConsumptionZEVLastECOtrip : 18|10@0+ (0.1,0) [0|102.2] "wu" IVI

BA_DEF_ BO_  "CANFD_BRS" ENUM "0","1";
BA_DEF_ BO_  "GenMsgSendType" STRING;
BA_DEF_ SG_  "Unavailable_Value" STRING;
BA_DEF_ BO_  "VFrameFormat" ENUM "StandardCAN","ExtendedCAN","reserved","reserved","reserved","reserved","reserved","reserved","reserved","reserved","reserved","reserved","reserved","reserved","StandardCAN_FD","ExtendedCAN_FD";
BA_DEF_ BO_  "GenMsgCycleTime" INT 0 50000;
BA_DEF_ BO_  "Exclusion_time" INT 0 50000;
BA_DEF_ SG_  "Event" STRING;
BA_DEF_ BO_  "Optional_Frame" STRING;

BA_DEF_DEF_  "CANFD_BRS" "0";
BA_DEF_DEF_  "Event" "false";
BA_DEF_DEF_  "GenMsgCycleTime" 0;
BA_DEF_DEF_  "Optional_Frame" "false";
BA_DEF_DEF_  "VFrameFormat" "StandardCAN";
BA_ "Exclusion_time" BO_ 1477 50;
BA_ "GenMsgCycleTime" BO_ 1477 1000;
BA_ "GenMsgSendType" BO_ 1477 "Periodic and Event";
BA_ "Exclusion_time" BO_ 1478 100;
BA_ "GenMsgCycleTime" BO_ 1478 3000;
BA_ "GenMsgSendType" BO_ 1478 "Periodic and Event";
BA_ "Exclusion_time" BO_ 1479 20;
BA_ "GenMsgCycleTime" BO_ 1479 1000;
BA_ "GenMsgSendType" BO_ 1479 "Periodic and Event";
BA_ "Exclusion_time" BO_ 1482 100;
BA_ "GenMsgCycleTime" BO_ 1482 3000;
BA_ "GenMsgSendType" BO_ 1482 "Periodic and Event";
BA_ "Exclusion_time" BO_ 1488 10;
BA_ "GenMsgCycleTime" BO_ 1488 500;
BA_ "GenMsgSendType" BO_ 1488 "Periodic and Event";
BA_ "Exclusion_time" BO_ 1490 100;
BA_ "GenMsgCycleTime" BO_ 1490 500;
BA_ "GenMsgSendType" BO_ 1490 "Periodic and Event";
BA_ "Exclusion_time" BO_ 1491 100;
BA_ "GenMsgCycleTime" BO_ 1491 3000;
BA_ "GenMsgSendType" BO_ 1491 "Periodic and Event";
BA_ "Exclusion_time" BO_ 1492 100;
BA_ "GenMsgCycleTime" BO_ 1492 3000;
BA_ "GenMsgSendType" BO_ 1492 "Periodic and Event";
BA_ "Exclusion_time" BO_ 1496 100;
BA_ "GenMsgCycleTime" BO_ 1496 1000;
BA_ "GenMsgSendType" BO_ 1496 "Periodic and Event";
BA_ "Exclusion_time" BO_ 1498 20;
BA_ "GenMsgCycleTime" BO_ 1498 3000;
BA_ "GenMsgSendType" BO_ 1498 "Periodic and Event";
BA_ "Exclusion_time" BO_ 1503 100;
BA_ "GenMsgCycleTime" BO_ 1503 1000;
BA_ "GenMsgSendType" BO_ 1503 "Periodic and Event";
BA_ "Exclusion_time" BO_ 1505 50;
BA_ "GenMsgCycleTime" BO_ 1505 1000;
BA_ "GenMsgSendType" BO_ 1505 "Periodic and Event";
BA_ "Exclusion_time" BO_ 1506 20;
BA_ "GenMsgCycleTime" BO_ 1506 1000;
BA_ "GenMsgSendType" BO_ 1506 "Periodic and Event";
BA_ "Exclusion_time" BO_ 1508 10;
BA_ "GenMsgCycleTime" BO_ 1508 1000;
BA_ "GenMsgSendType" BO_ 1508 "Periodic and Event";
BA_ "Exclusion_time" BO_ 1510 100;
BA_ "GenMsgCycleTime" BO_ 1510 1000;
BA_ "GenMsgSendType" BO_ 1510 "Periodic and Event";
BA_ "Exclusion_time" BO_ 1511 100;
BA_ "GenMsgCycleTime" BO_ 1511 500;
BA_ "GenMsgSendType" BO_ 1511 "Periodic and Event";
BA_ "Exclusion_time" BO_ 1516 100;
BA_ "GenMsgCycleTime" BO_ 1516 3000;
BA_ "GenMsgSendType" BO_ 1516 "Periodic and Event";
BA_ "Exclusion_time" BO_ 1519 20;
BA_ "GenMsgCycleTime" BO_ 1519 1000;
BA_ "GenMsgSendType" BO_ 1519 "Periodic and Event";
BA_ "Exclusion_time" BO_ 1523 100;
BA_ "GenMsgCycleTime" BO_ 1523 500;
BA_ "GenMsgSendType" BO_ 1523 "Periodic and Event";
BA_ "Exclusion_time" BO_ 1529 20;
BA_ "GenMsgCycleTime" BO_ 1529 3000;
BA_ "GenMsgSendType" BO_ 1529 "Periodic and Event";
BA_ "Exclusion_time" BO_ 1531 100;
BA_ "GenMsgCycleTime" BO_ 1531 3000;
BA_ "GenMsgSendType" BO_ 1531 "Periodic and Event";
BA_ "Exclusion_time" BO_ 1537 10;
BA_ "GenMsgCycleTime" BO_ 1537 500;
BA_ "GenMsgSendType" BO_ 1537 "Periodic and Event";
BA_ "Exclusion_time" BO_ 1538 10;
BA_ "GenMsgCycleTime" BO_ 1538 500;
BA_ "GenMsgSendType" BO_ 1538 "Periodic and Event";
BA_ "Exclusion_time" BO_ 1540 100;
BA_ "GenMsgCycleTime" BO_ 1540 1000;
BA_ "GenMsgSendType" BO_ 1540 "Periodic and Event";
BA_ "Exclusion_time" BO_ 1543 10;
BA_ "GenMsgCycleTime" BO_ 1543 500;
BA_ "GenMsgSendType" BO_ 1543 "Periodic and Event";
BA_ "Exclusion_time" BO_ 1549 20;
BA_ "GenMsgCycleTime" BO_ 1549 1000;
BA_ "GenMsgSendType" BO_ 1549 "Periodic and Event";
BA_ "Exclusion_time" BO_ 1553 50;
BA_ "GenMsgCycleTime" BO_ 1553 1000;
BA_ "GenMsgSendType" BO_ 1553 "Periodic and Event";
BA_ "Exclusion_time" BO_ 1557 20;
BA_ "GenMsgCycleTime" BO_ 1557 500;
BA_ "GenMsgSendType" BO_ 1557 "Periodic and Event";
BA_ "Exclusion_time" BO_ 1558 20;
BA_ "GenMsgCycleTime" BO_ 1558 500;
BA_ "GenMsgSendType" BO_ 1558 "Periodic and Event";
BA_ "Exclusion_time" BO_ 1561 20;
BA_ "GenMsgCycleTime" BO_ 1561 3000;
BA_ "GenMsgSendType" BO_ 1561 "Periodic and Event";
BA_ "Exclusion_time" BO_ 1564 100;
BA_ "GenMsgCycleTime" BO_ 1564 3000;
BA_ "GenMsgSendType" BO_ 1564 "Periodic and Event";
BA_ "Exclusion_time" BO_ 1567 100;
BA_ "GenMsgCycleTime" BO_ 1567 500;
BA_ "GenMsgSendType" BO_ 1567 "Periodic and Event";
BA_ "GenMsgCycleTime" BO_ 1568 1000;
BA_ "GenMsgSendType" BO_ 1568 "Periodic";
BA_ "Exclusion_time" BO_ 1570 100;
BA_ "GenMsgCycleTime" BO_ 1570 500;
BA_ "GenMsgSendType" BO_ 1570 "Periodic and Event";
BA_ "GenMsgCycleTime" BO_ 1572 500;
BA_ "GenMsgSendType" BO_ 1572 "Periodic";
BA_ "Exclusion_time" BO_ 1578 100;
BA_ "GenMsgCycleTime" BO_ 1578 3000;
BA_ "GenMsgSendType" BO_ 1578 "Periodic and Event";
BA_ "Exclusion_time" BO_ 1593 50;
BA_ "GenMsgCycleTime" BO_ 1593 3000;
BA_ "GenMsgSendType" BO_ 1593 "Periodic and Event";
BA_ "Exclusion_time" BO_ 1594 50;
BA_ "GenMsgCycleTime" BO_ 1594 3000;
BA_ "GenMsgSendType" BO_ 1594 "Periodic and Event";
BA_ "Exclusion_time" BO_ 1595 100;
BA_ "GenMsgCycleTime" BO_ 1595 3000;
BA_ "GenMsgSendType" BO_ 1595 "Periodic and Event";
BA_ "Exclusion_time" BO_ 1596 100;
BA_ "GenMsgCycleTime" BO_ 1596 3000;
BA_ "GenMsgSendType" BO_ 1596 "Periodic and Event";
BA_ "Exclusion_time" BO_ 1599 100;
BA_ "GenMsgCycleTime" BO_ 1599 3000;
BA_ "GenMsgSendType" BO_ 1599 "Periodic and Event";
BA_ "Exclusion_time" BO_ 1616 20;
BA_ "GenMsgCycleTime" BO_ 1616 3000;
BA_ "GenMsgSendType" BO_ 1616 "Periodic and Event";
BA_ "Exclusion_time" BO_ 1620 1000;
BA_ "GenMsgCycleTime" BO_ 1620 3000;
BA_ "GenMsgSendType" BO_ 1620 "Periodic and Event";
BA_ "Event" SG_ 1477 ITM_FrontRightSeatVentilPush "true";
BA_ "Event" SG_ 1477 ITM_FrontRightSeatVentilPush "true";
BA_ "Event" SG_ 1477 ITM_FrontRightSeatVentilPush "true";
BA_ "Event" SG_ 1477 ITM_FrontRightSeatVentilPush "true";
BA_ "Unavailable_Value" SG_ 1477 ITM_FrontRightSeatVentilPush "0b0";
BA_ "Event" SG_ 1477 ITM_FrontRightSeatRequest "true";
BA_ "Event" SG_ 1477 ITM_FrontRightSeatRequest "true";
BA_ "Event" SG_ 1477 ITM_FrontRightSeatRequest "true";
BA_ "Event" SG_ 1477 ITM_FrontRightSeatRequest "true";
BA_ "Unavailable_Value" SG_ 1477 ITM_FrontRightSeatRequest "0b000";
BA_ "Event" SG_ 1477 ITM_FrontLeftSeatVentilPush "true";
BA_ "Event" SG_ 1477 ITM_FrontLeftSeatVentilPush "true";
BA_ "Event" SG_ 1477 ITM_FrontLeftSeatVentilPush "true";
BA_ "Event" SG_ 1477 ITM_FrontLeftSeatVentilPush "true";
BA_ "Unavailable_Value" SG_ 1477 ITM_FrontLeftSeatVentilPush "0b0";
BA_ "Event" SG_ 1477 ITM_FrontLeftSeatRequest "true";
BA_ "Event" SG_ 1477 ITM_FrontLeftSeatRequest "true";
BA_ "Event" SG_ 1477 ITM_FrontLeftSeatRequest "true";
BA_ "Event" SG_ 1477 ITM_FrontLeftSeatRequest "true";
BA_ "Unavailable_Value" SG_ 1477 ITM_FrontLeftSeatRequest "0b000";
BA_ "Event" SG_ 1477 ITM_SecondRowRightSeatVentPush "true";
BA_ "Event" SG_ 1477 ITM_SecondRowRightSeatVentPush "true";
BA_ "Event" SG_ 1477 ITM_SecondRowRightSeatVentPush "true";
BA_ "Event" SG_ 1477 ITM_SecondRowRightSeatVentPush "true";
BA_ "Unavailable_Value" SG_ 1477 ITM_SecondRowRightSeatVentPush "0b0";
BA_ "Event" SG_ 1477 ITM_SecondRowRightSeatRequest "true";
BA_ "Event" SG_ 1477 ITM_SecondRowRightSeatRequest "true";
BA_ "Event" SG_ 1477 ITM_SecondRowRightSeatRequest "true";
BA_ "Event" SG_ 1477 ITM_SecondRowRightSeatRequest "true";
BA_ "Unavailable_Value" SG_ 1477 ITM_SecondRowRightSeatRequest "0b0";
BA_ "Event" SG_ 1477 ITM_SecondRowLeftSeatVentilPush "true";
BA_ "Event" SG_ 1477 ITM_SecondRowLeftSeatVentilPush "true";
BA_ "Event" SG_ 1477 ITM_SecondRowLeftSeatVentilPush "true";
BA_ "Event" SG_ 1477 ITM_SecondRowLeftSeatVentilPush "true";
BA_ "Unavailable_Value" SG_ 1477 ITM_SecondRowLeftSeatVentilPush "0b0";
BA_ "Event" SG_ 1477 ITM_SecondRowLeftSeatRequest "true";
BA_ "Event" SG_ 1477 ITM_SecondRowLeftSeatRequest "true";
BA_ "Event" SG_ 1477 ITM_SecondRowLeftSeatRequest "true";
BA_ "Event" SG_ 1477 ITM_SecondRowLeftSeatRequest "true";
BA_ "Unavailable_Value" SG_ 1477 ITM_SecondRowLeftSeatRequest "0b0";
BA_ "Event" SG_ 1477 ITM_ThirdRowRightSeatVentilPush "true";
BA_ "Event" SG_ 1477 ITM_ThirdRowRightSeatVentilPush "true";
BA_ "Event" SG_ 1477 ITM_ThirdRowRightSeatVentilPush "true";
BA_ "Event" SG_ 1477 ITM_ThirdRowRightSeatVentilPush "true";
BA_ "Unavailable_Value" SG_ 1477 ITM_ThirdRowRightSeatVentilPush "0b0";
BA_ "Event" SG_ 1477 ITM_ThirdRowRightSeatRequest "true";
BA_ "Event" SG_ 1477 ITM_ThirdRowRightSeatRequest "true";
BA_ "Event" SG_ 1477 ITM_ThirdRowRightSeatRequest "true";
BA_ "Event" SG_ 1477 ITM_ThirdRowRightSeatRequest "true";
BA_ "Unavailable_Value" SG_ 1477 ITM_ThirdRowRightSeatRequest "0b0";
BA_ "Event" SG_ 1477 ITM_ThirdRowLeftSeatVentilPush "true";
BA_ "Event" SG_ 1477 ITM_ThirdRowLeftSeatVentilPush "true";
BA_ "Event" SG_ 1477 ITM_ThirdRowLeftSeatVentilPush "true";
BA_ "Event" SG_ 1477 ITM_ThirdRowLeftSeatVentilPush "true";
BA_ "Unavailable_Value" SG_ 1477 ITM_ThirdRowLeftSeatVentilPush "0b0";
BA_ "Event" SG_ 1477 ITM_ThirdRowLeftSeatRequest "true";
BA_ "Event" SG_ 1477 ITM_ThirdRowLeftSeatRequest "true";
BA_ "Event" SG_ 1477 ITM_ThirdRowLeftSeatRequest "true";
BA_ "Event" SG_ 1477 ITM_ThirdRowLeftSeatRequest "true";
BA_ "Unavailable_Value" SG_ 1477 ITM_ThirdRowLeftSeatRequest "0b0";
BA_ "Event" SG_ 1478 SR_ContinuousRecordLengthRequest "true";
BA_ "Event" SG_ 1478 SR_ContinuousRecordLengthRequest "true";
BA_ "Event" SG_ 1478 SR_ContinuousRecordLengthRequest "true";
BA_ "Unavailable_Value" SG_ 1478 SR_ContinuousRecordLengthRequest "0b001";
BA_ "Event" SG_ 1478 SR_ShockSensitivityRequest "true";
BA_ "Event" SG_ 1478 SR_ShockSensitivityRequest "true";
BA_ "Event" SG_ 1478 SR_ShockSensitivityRequest "true";
BA_ "Unavailable_Value" SG_ 1478 SR_ShockSensitivityRequest "0b010";
BA_ "Event" SG_ 1478 SR_DrivingInfoRecordRequest "true";
BA_ "Event" SG_ 1478 SR_DrivingInfoRecordRequest "true";
BA_ "Event" SG_ 1478 SR_DrivingInfoRecordRequest "true";
BA_ "Unavailable_Value" SG_ 1478 SR_DrivingInfoRecordRequest "0b10";
BA_ "Event" SG_ 1478 SR_LocationInfoRecordRequest "true";
BA_ "Event" SG_ 1478 SR_LocationInfoRecordRequest "true";
BA_ "Event" SG_ 1478 SR_LocationInfoRecordRequest "true";
BA_ "Unavailable_Value" SG_ 1478 SR_LocationInfoRecordRequest "0b10";
BA_ "Event" SG_ 1478 SR_SoundRecordRequest "true";
BA_ "Event" SG_ 1478 SR_SoundRecordRequest "true";
BA_ "Event" SG_ 1478 SR_SoundRecordRequest "true";
BA_ "Unavailable_Value" SG_ 1478 SR_SoundRecordRequest "0b00";
BA_ "Event" SG_ 1478 SR_CustomerRecordLengthRequest "true";
BA_ "Event" SG_ 1478 SR_CustomerRecordLengthRequest "true";
BA_ "Event" SG_ 1478 SR_CustomerRecordLengthRequest "true";
BA_ "Unavailable_Value" SG_ 1478 SR_CustomerRecordLengthRequest "0b001";
BA_ "Event" SG_ 1479 ContinuousModeRequest "true";
BA_ "Event" SG_ 1479 ContinuousModeRequest "true";
BA_ "Event" SG_ 1479 ContinuousModeRequest "true";
BA_ "Event" SG_ 1479 ContinuousModeRequest "true";
BA_ "Unavailable_Value" SG_ 1479 ContinuousModeRequest "0b00";
BA_ "Event" SG_ 1479 MC_TutorialRequest_V2 "true";
BA_ "Event" SG_ 1479 MC_TutorialRequest_V2 "true";
BA_ "Event" SG_ 1479 MC_TutorialRequest_V2 "true";
BA_ "Event" SG_ 1479 MC_TutorialRequest_V2 "true";
BA_ "Unavailable_Value" SG_ 1479 MC_TutorialRequest_V2 "0b00";
BA_ "Event" SG_ 1479 RestrictionModeRequest "true";
BA_ "Event" SG_ 1479 RestrictionModeRequest "true";
BA_ "Event" SG_ 1479 RestrictionModeRequest "true";
BA_ "Event" SG_ 1479 RestrictionModeRequest "true";
BA_ "Unavailable_Value" SG_ 1479 RestrictionModeRequest "0b00";
BA_ "Event" SG_ 1479 ParkingModeRequest "true";
BA_ "Event" SG_ 1479 ParkingModeRequest "true";
BA_ "Event" SG_ 1479 ParkingModeRequest "true";
BA_ "Event" SG_ 1479 ParkingModeRequest "true";
BA_ "Unavailable_Value" SG_ 1479 ParkingModeRequest "0b00";
BA_ "Event" SG_ 1482 TSR_OSPActivationRequest2 "true";
BA_ "Event" SG_ 1482 TSR_OSPActivationRequest2 "true";
BA_ "Event" SG_ 1482 TSR_OSPActivationRequest2 "true";
BA_ "Event" SG_ 1482 TSR_OSPActivationRequest2 "true";
BA_ "Unavailable_Value" SG_ 1482 TSR_OSPActivationRequest2 "0b00";
BA_ "Event" SG_ 1482 TPMS_PressureFrontAxleRequest2 "true";
BA_ "Event" SG_ 1482 TPMS_PressureFrontAxleRequest2 "true";
BA_ "Event" SG_ 1482 TPMS_PressureFrontAxleRequest2 "true";
BA_ "Event" SG_ 1482 TPMS_PressureFrontAxleRequest2 "true";
BA_ "Unavailable_Value" SG_ 1482 TPMS_PressureFrontAxleRequest2 "0x00";
BA_ "Event" SG_ 1482 TPMS_PressureRearAxleRequest2 "true";
BA_ "Event" SG_ 1482 TPMS_PressureRearAxleRequest2 "true";
BA_ "Event" SG_ 1482 TPMS_PressureRearAxleRequest2 "true";
BA_ "Event" SG_ 1482 TPMS_PressureRearAxleRequest2 "true";
BA_ "Unavailable_Value" SG_ 1482 TPMS_PressureRearAxleRequest2 "0x00";
BA_ "Event" SG_ 1482 LDW_ActivationRequest2 "true";
BA_ "Event" SG_ 1482 LDW_ActivationRequest2 "true";
BA_ "Event" SG_ 1482 LDW_ActivationRequest2 "true";
BA_ "Event" SG_ 1482 LDW_ActivationRequest2 "true";
BA_ "Unavailable_Value" SG_ 1482 LDW_ActivationRequest2 "0b00";
BA_ "Event" SG_ 1482 LDW_VibrationIntensityReq2 "true";
BA_ "Event" SG_ 1482 LDW_VibrationIntensityReq2 "true";
BA_ "Event" SG_ 1482 LDW_VibrationIntensityReq2 "true";
BA_ "Event" SG_ 1482 LDW_VibrationIntensityReq2 "true";
BA_ "Unavailable_Value" SG_ 1482 LDW_VibrationIntensityReq2 "0b000";
BA_ "Event" SG_ 1482 SailingStopActivationRequest2 "true";
BA_ "Event" SG_ 1482 SailingStopActivationRequest2 "true";
BA_ "Event" SG_ 1482 SailingStopActivationRequest2 "true";
BA_ "Event" SG_ 1482 SailingStopActivationRequest2 "true";
BA_ "Unavailable_Value" SG_ 1482 SailingStopActivationRequest2 "null";
BA_ "Event" SG_ 1482 AEB_FCWactivationRequest2 "true";
BA_ "Event" SG_ 1482 AEB_FCWactivationRequest2 "true";
BA_ "Event" SG_ 1482 AEB_FCWactivationRequest2 "true";
BA_ "Event" SG_ 1482 AEB_FCWactivationRequest2 "true";
BA_ "Unavailable_Value" SG_ 1482 AEB_FCWactivationRequest2 "0b000";
BA_ "Event" SG_ 1482 LDW_SensibilityRequest2 "true";
BA_ "Event" SG_ 1482 LDW_SensibilityRequest2 "true";
BA_ "Event" SG_ 1482 LDW_SensibilityRequest2 "true";
BA_ "Event" SG_ 1482 LDW_SensibilityRequest2 "true";
BA_ "Unavailable_Value" SG_ 1482 LDW_SensibilityRequest2 "0b000";
BA_ "Event" SG_ 1482 FKP_ActivationRequest2 "true";
BA_ "Event" SG_ 1482 FKP_ActivationRequest2 "true";
BA_ "Event" SG_ 1482 FKP_ActivationRequest2 "true";
BA_ "Event" SG_ 1482 FKP_ActivationRequest2 "true";
BA_ "Unavailable_Value" SG_ 1482 FKP_ActivationRequest2 "0b00";
BA_ "Event" SG_ 1482 MOD_ActivationRequest2 "true";
BA_ "Event" SG_ 1482 MOD_ActivationRequest2 "true";
BA_ "Event" SG_ 1482 MOD_ActivationRequest2 "true";
BA_ "Event" SG_ 1482 MOD_ActivationRequest2 "true";
BA_ "Unavailable_Value" SG_ 1482 MOD_ActivationRequest2 "0b00";
BA_ "Event" SG_ 1482 SonarAutoDisplayRequest2 "true";
BA_ "Event" SG_ 1482 SonarAutoDisplayRequest2 "true";
BA_ "Event" SG_ 1482 SonarAutoDisplayRequest2 "true";
BA_ "Event" SG_ 1482 SonarAutoDisplayRequest2 "true";
BA_ "Unavailable_Value" SG_ 1482 SonarAutoDisplayRequest2 "0b00";
BA_ "Event" SG_ 1482 DW_ActivationRequest2 "true";
BA_ "Event" SG_ 1482 DW_ActivationRequest2 "true";
BA_ "Event" SG_ 1482 DW_ActivationRequest2 "true";
BA_ "Event" SG_ 1482 DW_ActivationRequest2 "true";
BA_ "Unavailable_Value" SG_ 1482 DW_ActivationRequest2 "0b00";
BA_ "Event" SG_ 1482 BSWrad_ActivationRequest2 "true";
BA_ "Event" SG_ 1482 BSWrad_ActivationRequest2 "true";
BA_ "Event" SG_ 1482 BSWrad_ActivationRequest2 "true";
BA_ "Event" SG_ 1482 BSWrad_ActivationRequest2 "true";
BA_ "Unavailable_Value" SG_ 1482 BSWrad_ActivationRequest2 "0b00";
BA_ "Event" SG_ 1482 HFP_DefaultManeuverTypeRequest2 "true";
BA_ "Event" SG_ 1482 HFP_DefaultManeuverTypeRequest2 "true";
BA_ "Event" SG_ 1482 HFP_DefaultManeuverTypeRequest2 "true";
BA_ "Event" SG_ 1482 HFP_DefaultManeuverTypeRequest2 "true";
BA_ "Unavailable_Value" SG_ 1482 HFP_DefaultManeuverTypeRequest2 "0b000";
BA_ "Event" SG_ 1482 HandDrivingActivationRequest2 "true";
BA_ "Event" SG_ 1482 HandDrivingActivationRequest2 "true";
BA_ "Event" SG_ 1482 HandDrivingActivationRequest2 "true";
BA_ "Event" SG_ 1482 HandDrivingActivationRequest2 "true";
BA_ "Unavailable_Value" SG_ 1482 HandDrivingActivationRequest2 "0b00";
BA_ "Event" SG_ 1482 LKA_ActivationRequest2 "true";
BA_ "Event" SG_ 1482 LKA_ActivationRequest2 "true";
BA_ "Event" SG_ 1482 LKA_ActivationRequest2 "true";
BA_ "Event" SG_ 1482 LKA_ActivationRequest2 "true";
BA_ "Unavailable_Value" SG_ 1482 LKA_ActivationRequest2 "null";
BA_ "Event" SG_ 1482 SailingIdleActivationReq2 "true";
BA_ "Event" SG_ 1482 SailingIdleActivationReq2 "true";
BA_ "Event" SG_ 1482 SailingIdleActivationReq2 "true";
BA_ "Event" SG_ 1482 SailingIdleActivationReq2 "true";
BA_ "Unavailable_Value" SG_ 1482 SailingIdleActivationReq2 "0b00";
BA_ "Event" SG_ 1482 CTA_ActivationRequest2 "true";
BA_ "Event" SG_ 1482 CTA_ActivationRequest2 "true";
BA_ "Event" SG_ 1482 CTA_ActivationRequest2 "true";
BA_ "Event" SG_ 1482 CTA_ActivationRequest2 "true";
BA_ "Unavailable_Value" SG_ 1482 CTA_ActivationRequest2 "0b00";
BA_ "Event" SG_ 1482 AFS_ActivationRequest2 "true";
BA_ "Event" SG_ 1482 AFS_ActivationRequest2 "true";
BA_ "Event" SG_ 1482 AFS_ActivationRequest2 "true";
BA_ "Event" SG_ 1482 AFS_ActivationRequest2 "true";
BA_ "Unavailable_Value" SG_ 1482 AFS_ActivationRequest2 "0b00";
BA_ "Event" SG_ 1482 LCA_ActivationRequest2 "true";
BA_ "Event" SG_ 1482 LCA_ActivationRequest2 "true";
BA_ "Event" SG_ 1482 LCA_ActivationRequest2 "true";
BA_ "Event" SG_ 1482 LCA_ActivationRequest2 "true";
BA_ "Unavailable_Value" SG_ 1482 LCA_ActivationRequest2 "0b00";
BA_ "Event" SG_ 1488 OffsetActivation_State "true";
BA_ "Event" SG_ 1488 OffsetActivation_State "true";
BA_ "Event" SG_ 1488 OffsetActivation_State "true";
BA_ "Event" SG_ 1488 OffsetActivation_State "true";
BA_ "Unavailable_Value" SG_ 1488 OffsetActivation_State "0b11";
BA_ "Event" SG_ 1488 OffsetValue_State "true";
BA_ "Event" SG_ 1488 OffsetValue_State "true";
BA_ "Event" SG_ 1488 OffsetValue_State "true";
BA_ "Event" SG_ 1488 OffsetValue_State "true";
BA_ "Unavailable_Value" SG_ 1488 OffsetValue_State "0x00";
BA_ "Event" SG_ 1490 HUD_RotationPositionState "true";
BA_ "Event" SG_ 1490 HUD_RotationPositionState "true";
BA_ "Event" SG_ 1490 HUD_RotationPositionState "true";
BA_ "Event" SG_ 1490 HUD_RotationPositionState "true";
BA_ "Unavailable_Value" SG_ 1490 HUD_RotationPositionState "0x00";
BA_ "Event" SG_ 1490 HUD_FOTA_status "true";
BA_ "Event" SG_ 1490 HUD_FOTA_status "true";
BA_ "Event" SG_ 1490 HUD_FOTA_status "true";
BA_ "Event" SG_ 1490 HUD_FOTA_status "true";
BA_ "Unavailable_Value" SG_ 1490 HUD_FOTA_status "0x1F";
BA_ "Event" SG_ 1491 ParkAssistVolumeRequest "true";
BA_ "Event" SG_ 1491 ParkAssistVolumeRequest "true";
BA_ "Event" SG_ 1491 ParkAssistVolumeRequest "true";
BA_ "Event" SG_ 1491 ParkAssistVolumeRequest "true";
BA_ "Unavailable_Value" SG_ 1491 ParkAssistVolumeRequest "0b000";
BA_ "Event" SG_ 1492 PnCcontractCertifExpiry_Month "true";
BA_ "Event" SG_ 1492 PnCcontractCertifExpiry_Month "true";
BA_ "Event" SG_ 1492 PnCcontractCertifExpiry_Month "true";
BA_ "Event" SG_ 1492 PnCcontractCertifExpiry_Month "true";
BA_ "Event" SG_ 1492 PnCcertificateInstallationStatus "true";
BA_ "Event" SG_ 1492 PnCcertificateInstallationStatus "true";
BA_ "Event" SG_ 1492 PnCcertificateInstallationStatus "true";
BA_ "Event" SG_ 1492 PnCcertificateInstallationStatus "true";
BA_ "Unavailable_Value" SG_ 1492 PnCcertificateInstallationStatus "0xF";
BA_ "Event" SG_ 1492 PnCcontractCertifExpiry_Year "true";
BA_ "Event" SG_ 1492 PnCcontractCertifExpiry_Year "true";
BA_ "Event" SG_ 1492 PnCcontractCertifExpiry_Year "true";
BA_ "Event" SG_ 1492 PnCcontractCertifExpiry_Year "true";
BA_ "Event" SG_ 1492 PnCcontractCertifExpiry_Day "true";
BA_ "Event" SG_ 1492 PnCcontractCertifExpiry_Day "true";
BA_ "Event" SG_ 1492 PnCcontractCertifExpiry_Day "true";
BA_ "Event" SG_ 1492 PnCcontractCertifExpiry_Day "true";
BA_ "Event" SG_ 1492 PnCcontractCertifValidity_Year "true";
BA_ "Event" SG_ 1492 PnCcontractCertifValidity_Year "true";
BA_ "Event" SG_ 1492 PnCcontractCertifValidity_Year "true";
BA_ "Event" SG_ 1492 PnCcontractCertifValidity_Year "true";
BA_ "Event" SG_ 1492 PnCcontractCertifValidity_Day "true";
BA_ "Event" SG_ 1492 PnCcontractCertifValidity_Day "true";
BA_ "Event" SG_ 1492 PnCcontractCertifValidity_Day "true";
BA_ "Event" SG_ 1492 PnCcontractCertifValidity_Day "true";
BA_ "Event" SG_ 1492 PnCcontractCertifValidity_Month "true";
BA_ "Event" SG_ 1492 PnCcontractCertifValidity_Month "true";
BA_ "Event" SG_ 1492 PnCcontractCertifValidity_Month "true";
BA_ "Event" SG_ 1492 PnCcontractCertifValidity_Month "true";
BA_ "Event" SG_ 1496 WCBS_Memory_Fault "true";
BA_ "Event" SG_ 1496 WCBS_Memory_Fault "true";
BA_ "Event" SG_ 1496 WCBS_Memory_Fault "true";
BA_ "Unavailable_Value" SG_ 1496 WCBS_Memory_Fault "0b00";
BA_ "Event" SG_ 1496 WCBS_Coil_Disconnection "true";
BA_ "Event" SG_ 1496 WCBS_Coil_Disconnection "true";
BA_ "Event" SG_ 1496 WCBS_Coil_Disconnection "true";
BA_ "Unavailable_Value" SG_ 1496 WCBS_Coil_Disconnection "0b00";
BA_ "Event" SG_ 1496 WCBS_ChargingStopReason "true";
BA_ "Event" SG_ 1496 WCBS_ChargingStopReason "true";
BA_ "Event" SG_ 1496 WCBS_ChargingStopReason "true";
BA_ "Unavailable_Value" SG_ 1496 WCBS_ChargingStopReason "0x0";
BA_ "Event" SG_ 1496 Smartphone_Manufacturer "true";
BA_ "Event" SG_ 1496 Smartphone_Manufacturer "true";
BA_ "Event" SG_ 1496 Smartphone_Manufacturer "true";
BA_ "Unavailable_Value" SG_ 1496 Smartphone_Manufacturer "0b000";
BA_ "Event" SG_ 1496 Smartphone_Charging_Time "true";
BA_ "Event" SG_ 1496 Smartphone_Charging_Time "true";
BA_ "Event" SG_ 1496 Smartphone_Charging_Time "true";
BA_ "Unavailable_Value" SG_ 1496 Smartphone_Charging_Time "0xFFFF";
BA_ "Event" SG_ 1496 Smartphone_Charging_Standard "true";
BA_ "Event" SG_ 1496 Smartphone_Charging_Standard "true";
BA_ "Event" SG_ 1496 Smartphone_Charging_Standard "true";
BA_ "Unavailable_Value" SG_ 1496 Smartphone_Charging_Standard "0b000";
BA_ "Unavailable_Value" SG_ 1496 WCBS_temperature "0x1F";
BA_ "Event" SG_ 1496 InductiveChargerStatus "true";
BA_ "Event" SG_ 1496 InductiveChargerStatus "true";
BA_ "Event" SG_ 1496 InductiveChargerStatus "true";
BA_ "Unavailable_Value" SG_ 1496 InductiveChargerStatus "0b00";
BA_ "Event" SG_ 1496 WCBS_HMI "true";
BA_ "Event" SG_ 1496 WCBS_HMI "true";
BA_ "Event" SG_ 1496 WCBS_HMI "true";
BA_ "Unavailable_Value" SG_ 1496 WCBS_HMI "0b000";
BA_ "Event" SG_ 1498 AD_DistanceDuration "true";
BA_ "Event" SG_ 1498 AD_DistanceDuration "true";
BA_ "Event" SG_ 1498 AD_DistanceDuration "true";
BA_ "Event" SG_ 1498 AD_DistanceDuration "true";
BA_ "Unavailable_Value" SG_ 1498 AD_DistanceDuration "0x3FFF";
BA_ "Event" SG_ 1498 AD_TimeDuration "true";
BA_ "Event" SG_ 1498 AD_TimeDuration "true";
BA_ "Event" SG_ 1498 AD_TimeDuration "true";
BA_ "Event" SG_ 1498 AD_TimeDuration "true";
BA_ "Unavailable_Value" SG_ 1498 AD_TimeDuration "0x3FF";
BA_ "Event" SG_ 1503 PassengerBackBolsterDisplayReq "true";
BA_ "Event" SG_ 1503 PassengerBackBolsterDisplayReq "true";
BA_ "Event" SG_ 1503 PassengerBackBolsterDisplayReq "true";
BA_ "Event" SG_ 1503 PassengerBackBolsterDisplayReq "true";
BA_ "Unavailable_Value" SG_ 1503 PassengerBackBolsterDisplayReq "0b0";
BA_ "Event" SG_ 1503 PassengerSeatMemoState "true";
BA_ "Event" SG_ 1503 PassengerSeatMemoState "true";
BA_ "Event" SG_ 1503 PassengerSeatMemoState "true";
BA_ "Event" SG_ 1503 PassengerSeatMemoState "true";
BA_ "Unavailable_Value" SG_ 1503 PassengerSeatMemoState "0b000";
BA_ "Event" SG_ 1503 PassengerSwitchMassageRequest "true";
BA_ "Event" SG_ 1503 PassengerSwitchMassageRequest "true";
BA_ "Event" SG_ 1503 PassengerSwitchMassageRequest "true";
BA_ "Event" SG_ 1503 PassengerSwitchMassageRequest "true";
BA_ "Unavailable_Value" SG_ 1503 PassengerSwitchMassageRequest "0b0";
BA_ "Event" SG_ 1503 PsgerCushionBolsterDisplayReq "true";
BA_ "Event" SG_ 1503 PsgerCushionBolsterDisplayReq "true";
BA_ "Event" SG_ 1503 PsgerCushionBolsterDisplayReq "true";
BA_ "Event" SG_ 1503 PsgerCushionBolsterDisplayReq "true";
BA_ "Unavailable_Value" SG_ 1503 PsgerCushionBolsterDisplayReq "0b00";
BA_ "Unavailable_Value" SG_ 1503 PsLumbarDisplayRequest_Z_Axis "0b00";
BA_ "Unavailable_Value" SG_ 1503 PsLumbarDisplayRequest_X_Axis "0b00";
BA_ "Event" SG_ 1505 ClimDistributionVentPush "true";
BA_ "Event" SG_ 1505 ClimDistributionVentPush "true";
BA_ "Event" SG_ 1505 ClimDistributionVentPush "true";
BA_ "Event" SG_ 1505 ClimDistributionVentPush "true";
BA_ "Unavailable_Value" SG_ 1505 ClimDistributionVentPush "0b0";
BA_ "Event" SG_ 1505 ClimDistributionDefrostPush "true";
BA_ "Event" SG_ 1505 ClimDistributionDefrostPush "true";
BA_ "Event" SG_ 1505 ClimDistributionDefrostPush "true";
BA_ "Event" SG_ 1505 ClimDistributionDefrostPush "true";
BA_ "Unavailable_Value" SG_ 1505 ClimDistributionDefrostPush "0b0";
BA_ "Event" SG_ 1505 ClimAutoNormalPush "true";
BA_ "Event" SG_ 1505 ClimAutoNormalPush "true";
BA_ "Event" SG_ 1505 ClimAutoNormalPush "true";
BA_ "Event" SG_ 1505 ClimAutoNormalPush "true";
BA_ "Unavailable_Value" SG_ 1505 ClimAutoNormalPush "0b0";
BA_ "Event" SG_ 1505 ClimModeOFFPush "true";
BA_ "Event" SG_ 1505 ClimModeOFFPush "true";
BA_ "Event" SG_ 1505 ClimModeOFFPush "true";
BA_ "Event" SG_ 1505 ClimModeOFFPush "true";
BA_ "Unavailable_Value" SG_ 1505 ClimModeOFFPush "0b0";
BA_ "Event" SG_ 1505 ClimAutoSoftPush "true";
BA_ "Event" SG_ 1505 ClimAutoSoftPush "true";
BA_ "Event" SG_ 1505 ClimAutoSoftPush "true";
BA_ "Event" SG_ 1505 ClimAutoSoftPush "true";
BA_ "Unavailable_Value" SG_ 1505 ClimAutoSoftPush "0b0";
BA_ "Event" SG_ 1505 ClimAutoFastPush "true";
BA_ "Event" SG_ 1505 ClimAutoFastPush "true";
BA_ "Event" SG_ 1505 ClimAutoFastPush "true";
BA_ "Event" SG_ 1505 ClimAutoFastPush "true";
BA_ "Unavailable_Value" SG_ 1505 ClimAutoFastPush "0b0";
BA_ "Unavailable_Value" SG_ 1505 ClimDualModePush "0b0";
BA_ "Event" SG_ 1505 ClimRecyclingAutoPush "true";
BA_ "Event" SG_ 1505 ClimRecyclingAutoPush "true";
BA_ "Event" SG_ 1505 ClimRecyclingAutoPush "true";
BA_ "Event" SG_ 1505 ClimRecyclingAutoPush "true";
BA_ "Unavailable_Value" SG_ 1505 ClimRecyclingAutoPush "0b0";
BA_ "Event" SG_ 1505 AQMIoniserModeSelectionReq "true";
BA_ "Event" SG_ 1505 AQMIoniserModeSelectionReq "true";
BA_ "Event" SG_ 1505 AQMIoniserModeSelectionReq "true";
BA_ "Event" SG_ 1505 AQMIoniserModeSelectionReq "true";
BA_ "Unavailable_Value" SG_ 1505 AQMIoniserModeSelectionReq "0b00";
BA_ "Event" SG_ 1505 ClimFPBlowerRequest "true";
BA_ "Event" SG_ 1505 ClimFPBlowerRequest "true";
BA_ "Event" SG_ 1505 ClimFPBlowerRequest "true";
BA_ "Event" SG_ 1505 ClimFPBlowerRequest "true";
BA_ "Unavailable_Value" SG_ 1505 ClimFPBlowerRequest "0x0";
BA_ "Event" SG_ 1505 LeftTempRequest "true";
BA_ "Event" SG_ 1505 LeftTempRequest "true";
BA_ "Event" SG_ 1505 LeftTempRequest "true";
BA_ "Event" SG_ 1505 LeftTempRequest "true";
BA_ "Unavailable_Value" SG_ 1505 LeftTempRequest "0xFF";
BA_ "Event" SG_ 1505 ClimDistributionFeetPush "true";
BA_ "Event" SG_ 1505 ClimDistributionFeetPush "true";
BA_ "Event" SG_ 1505 ClimDistributionFeetPush "true";
BA_ "Event" SG_ 1505 ClimDistributionFeetPush "true";
BA_ "Unavailable_Value" SG_ 1505 ClimDistributionFeetPush "0b0";
BA_ "Unavailable_Value" SG_ 1505 ClimACOFFPush "0b0";
BA_ "Event" SG_ 1505 BlowerReductionRequest "true";
BA_ "Event" SG_ 1505 BlowerReductionRequest "true";
BA_ "Event" SG_ 1505 BlowerReductionRequest "true";
BA_ "Event" SG_ 1505 BlowerReductionRequest "true";
BA_ "Unavailable_Value" SG_ 1505 BlowerReductionRequest "0b0";
BA_ "Event" SG_ 1505 AirFreshenerRequest "true";
BA_ "Event" SG_ 1505 AirFreshenerRequest "true";
BA_ "Event" SG_ 1505 AirFreshenerRequest "true";
BA_ "Event" SG_ 1505 AirFreshenerRequest "true";
BA_ "Unavailable_Value" SG_ 1505 AirFreshenerRequest "0b00";
BA_ "Event" SG_ 1505 RightTempRequest "true";
BA_ "Event" SG_ 1505 RightTempRequest "true";
BA_ "Event" SG_ 1505 RightTempRequest "true";
BA_ "Event" SG_ 1505 RightTempRequest "true";
BA_ "Unavailable_Value" SG_ 1505 RightTempRequest "0xFF";
BA_ "Unavailable_Value" SG_ 1506 SSU_Movement "0b00";
BA_ "Unavailable_Value" SG_ 1506 SRU_Movement "0b00";
BA_ "Event" SG_ 1506 MM_GeneralAuthWindowsLift "true";
BA_ "Event" SG_ 1506 MM_GeneralAuthWindowsLift "true";
BA_ "Event" SG_ 1506 MM_GeneralAuthWindowsLift "true";
BA_ "Event" SG_ 1506 MM_GeneralAuthWindowsLift "true";
BA_ "Unavailable_Value" SG_ 1506 WindowPositionExtended_FR "0b00000";
BA_ "Unavailable_Value" SG_ 1506 WindowPositionExtended_FL "0b00000";
BA_ "Unavailable_Value" SG_ 1506 WindowPositionExtended_RR "0b00000";
BA_ "Unavailable_Value" SG_ 1506 WindowPositionExtended_RL "0b00000";
BA_ "Unavailable_Value" SG_ 1506 SSU_Position "0b0000";
BA_ "Event" SG_ 1508 RESPreSoak_ProgStatus "true";
BA_ "Event" SG_ 1508 RESPreSoak_ProgStatus "true";
BA_ "Event" SG_ 1508 RESPreSoak_ProgStatus "true";
BA_ "Event" SG_ 1508 RESPreSoak_ProgStatus "true";
BA_ "Unavailable_Value" SG_ 1508 RESPreSoak_ProgStatus "0b00";
BA_ "Unavailable_Value" SG_ 1508 RES_ProgrammationForbidden "0b0";
BA_ "Unavailable_Value" SG_ 1510 FixedMaintenanceRange "0x00";
BA_ "Unavailable_Value" SG_ 1510 DistanceToEmptyTank "0x7FF";
BA_ "Unavailable_Value" SG_ 1510 AlertMinBeforeOverhaul "0b00";
BA_ "Unavailable_Value" SG_ 1510 PersoOilDrainingRange "0xFF";
BA_ "Unavailable_Value" SG_ 1510 MilageMinBeforeOverhaul "0xFF";
BA_ "Unavailable_Value" SG_ 1510 TimeBeforeDraining "0x1FF";
BA_ "Event" SG_ 1510 ClusterSkinState_v2 "true";
BA_ "Event" SG_ 1510 ClusterSkinState_v2 "true";
BA_ "Event" SG_ 1510 ClusterSkinState_v2 "true";
BA_ "Event" SG_ 1510 ClusterSkinState_v2 "true";
BA_ "Event" SG_ 1511 TPMS_PressureFrontAxleState "true";
BA_ "Event" SG_ 1511 TPMS_PressureFrontAxleState "true";
BA_ "Event" SG_ 1511 TPMS_PressureFrontAxleState "true";
BA_ "Event" SG_ 1511 TPMS_PressureFrontAxleState "true";
BA_ "Unavailable_Value" SG_ 1511 TPMS_PressureFrontAxleState "0x3F";
BA_ "Event" SG_ 1511 TPMS_PressureRearAxleState "true";
BA_ "Event" SG_ 1511 TPMS_PressureRearAxleState "true";
BA_ "Event" SG_ 1511 TPMS_PressureRearAxleState "true";
BA_ "Event" SG_ 1511 TPMS_PressureRearAxleState "true";
BA_ "Unavailable_Value" SG_ 1511 TPMS_PressureRearAxleState "0x3F";
BA_ "Event" SG_ 1511 WheelStateRL "true";
BA_ "Event" SG_ 1511 WheelStateRL "true";
BA_ "Event" SG_ 1511 WheelStateRL "true";
BA_ "Event" SG_ 1511 WheelStateRL "true";
BA_ "Unavailable_Value" SG_ 1511 WheelStateRL "0b000";
BA_ "Event" SG_ 1511 WheelStateRR "true";
BA_ "Event" SG_ 1511 WheelStateRR "true";
BA_ "Event" SG_ 1511 WheelStateRR "true";
BA_ "Event" SG_ 1511 WheelStateRR "true";
BA_ "Unavailable_Value" SG_ 1511 WheelStateRR "0b000";
BA_ "Event" SG_ 1511 TPMS_AckResetDriver "true";
BA_ "Event" SG_ 1511 TPMS_AckResetDriver "true";
BA_ "Event" SG_ 1511 TPMS_AckResetDriver "true";
BA_ "Event" SG_ 1511 TPMS_AckResetDriver "true";
BA_ "Unavailable_Value" SG_ 1511 TPMS_AckResetDriver "0b00";
BA_ "Event" SG_ 1511 WheelStateFL "true";
BA_ "Event" SG_ 1511 WheelStateFL "true";
BA_ "Event" SG_ 1511 WheelStateFL "true";
BA_ "Event" SG_ 1511 WheelStateFL "true";
BA_ "Unavailable_Value" SG_ 1511 WheelStateFL "0b000";
BA_ "Event" SG_ 1511 WheelStateFR "true";
BA_ "Event" SG_ 1511 WheelStateFR "true";
BA_ "Event" SG_ 1511 WheelStateFR "true";
BA_ "Event" SG_ 1511 WheelStateFR "true";
BA_ "Unavailable_Value" SG_ 1511 WheelStateFR "0b000";
BA_ "Event" SG_ 1511 OldPressureFL "true";
BA_ "Event" SG_ 1511 OldPressureFL "true";
BA_ "Event" SG_ 1511 OldPressureFL "true";
BA_ "Event" SG_ 1511 OldPressureFL "true";
BA_ "Unavailable_Value" SG_ 1511 OldPressureFL "0b1";
BA_ "Event" SG_ 1511 OldPressureFR "true";
BA_ "Event" SG_ 1511 OldPressureFR "true";
BA_ "Event" SG_ 1511 OldPressureFR "true";
BA_ "Event" SG_ 1511 OldPressureFR "true";
BA_ "Unavailable_Value" SG_ 1511 OldPressureFR "0b1";
BA_ "Event" SG_ 1511 OldPressureRL "true";
BA_ "Event" SG_ 1511 OldPressureRL "true";
BA_ "Event" SG_ 1511 OldPressureRL "true";
BA_ "Event" SG_ 1511 OldPressureRL "true";
BA_ "Unavailable_Value" SG_ 1511 OldPressureRL "0b1";
BA_ "Event" SG_ 1511 OldPressureRR "true";
BA_ "Event" SG_ 1511 OldPressureRR "true";
BA_ "Event" SG_ 1511 OldPressureRR "true";
BA_ "Event" SG_ 1511 OldPressureRR "true";
BA_ "Unavailable_Value" SG_ 1511 OldPressureRR "0b1";
BA_ "Event" SG_ 1511 TPMS_AutoLocStatus "true";
BA_ "Event" SG_ 1511 TPMS_AutoLocStatus "true";
BA_ "Event" SG_ 1511 TPMS_AutoLocStatus "true";
BA_ "Event" SG_ 1511 TPMS_AutoLocStatus "true";
BA_ "Unavailable_Value" SG_ 1511 TPMS_AutoLocStatus "0b00";
BA_ "Event" SG_ 1516 LDW_SoundLevelRequest_v2 "true";
BA_ "Event" SG_ 1516 LDW_SoundLevelRequest_v2 "true";
BA_ "Event" SG_ 1516 LDW_SoundLevelRequest_v2 "true";
BA_ "Event" SG_ 1516 LDW_SoundLevelRequest_v2 "true";
BA_ "Unavailable_Value" SG_ 1516 LDW_SoundLevelRequest_v2 "0b000";
BA_ "Event" SG_ 1519 UserSettingCopySource "true";
BA_ "Event" SG_ 1519 UserSettingCopySource "true";
BA_ "Event" SG_ 1519 UserSettingCopySource "true";
BA_ "Event" SG_ 1519 UserSettingCopySource "true";
BA_ "Unavailable_Value" SG_ 1519 UserSettingCopySource "0b000";
BA_ "Event" SG_ 1519 UserSettingCopyTarget "true";
BA_ "Event" SG_ 1519 UserSettingCopyTarget "true";
BA_ "Event" SG_ 1519 UserSettingCopyTarget "true";
BA_ "Event" SG_ 1519 UserSettingCopyTarget "true";
BA_ "Unavailable_Value" SG_ 1519 UserSettingCopyTarget "0b000";
BA_ "Event" SG_ 1519 User5_RegistrationState "true";
BA_ "Event" SG_ 1519 User5_RegistrationState "true";
BA_ "Event" SG_ 1519 User5_RegistrationState "true";
BA_ "Event" SG_ 1519 User5_RegistrationState "true";
BA_ "Unavailable_Value" SG_ 1519 User5_RegistrationState "0b0";
BA_ "Event" SG_ 1519 User4_RegistrationState "true";
BA_ "Event" SG_ 1519 User4_RegistrationState "true";
BA_ "Event" SG_ 1519 User4_RegistrationState "true";
BA_ "Event" SG_ 1519 User4_RegistrationState "true";
BA_ "Unavailable_Value" SG_ 1519 User4_RegistrationState "0b0";
BA_ "Event" SG_ 1519 KeyLinkInitializationState "true";
BA_ "Event" SG_ 1519 KeyLinkInitializationState "true";
BA_ "Event" SG_ 1519 KeyLinkInitializationState "true";
BA_ "Event" SG_ 1519 KeyLinkInitializationState "true";
BA_ "Unavailable_Value" SG_ 1519 KeyLinkInitializationState "0b0";
BA_ "Event" SG_ 1519 KeyLinkActivationState "true";
BA_ "Event" SG_ 1519 KeyLinkActivationState "true";
BA_ "Event" SG_ 1519 KeyLinkActivationState "true";
BA_ "Event" SG_ 1519 KeyLinkActivationState "true";
BA_ "Unavailable_Value" SG_ 1519 KeyLinkActivationState "0b0";
BA_ "Event" SG_ 1519 User3_RegistrationState "true";
BA_ "Event" SG_ 1519 User3_RegistrationState "true";
BA_ "Event" SG_ 1519 User3_RegistrationState "true";
BA_ "Event" SG_ 1519 User3_RegistrationState "true";
BA_ "Unavailable_Value" SG_ 1519 User3_RegistrationState "0b0";
BA_ "Event" SG_ 1519 User2_RegistrationState "true";
BA_ "Event" SG_ 1519 User2_RegistrationState "true";
BA_ "Event" SG_ 1519 User2_RegistrationState "true";
BA_ "Event" SG_ 1519 User2_RegistrationState "true";
BA_ "Unavailable_Value" SG_ 1519 User2_RegistrationState "0b0";
BA_ "Event" SG_ 1519 User1_RegistrationState "true";
BA_ "Event" SG_ 1519 User1_RegistrationState "true";
BA_ "Event" SG_ 1519 User1_RegistrationState "true";
BA_ "Event" SG_ 1519 User1_RegistrationState "true";
BA_ "Unavailable_Value" SG_ 1519 User1_RegistrationState "0b0";
BA_ "Event" SG_ 1519 UserSettingCopyRequest "true";
BA_ "Event" SG_ 1519 UserSettingCopyRequest "true";
BA_ "Event" SG_ 1519 UserSettingCopyRequest "true";
BA_ "Event" SG_ 1519 UserSettingCopyRequest "true";
BA_ "Unavailable_Value" SG_ 1519 UserSettingCopyRequest "0b0";
BA_ "Event" SG_ 1519 ClimLinkFreshRecyAndAutoPush "true";
BA_ "Event" SG_ 1519 ClimLinkFreshRecyAndAutoPush "true";
BA_ "Event" SG_ 1519 ClimLinkFreshRecyAndAutoPush "true";
BA_ "Event" SG_ 1519 ClimLinkFreshRecyAndAutoPush "true";
BA_ "Unavailable_Value" SG_ 1519 ClimLinkFreshRecyAndAutoPush "0b0";
BA_ "Event" SG_ 1519 ADA1ActivationRequest2 "true";
BA_ "Event" SG_ 1519 ADA1ActivationRequest2 "true";
BA_ "Event" SG_ 1519 ADA1ActivationRequest2 "true";
BA_ "Event" SG_ 1519 ADA1ActivationRequest2 "true";
BA_ "Unavailable_Value" SG_ 1519 ADA1ActivationRequest2 "0b00";
BA_ "Event" SG_ 1519 ASAactivationRequest2 "true";
BA_ "Event" SG_ 1519 ASAactivationRequest2 "true";
BA_ "Event" SG_ 1519 ASAactivationRequest2 "true";
BA_ "Event" SG_ 1519 ASAactivationRequest2 "true";
BA_ "Unavailable_Value" SG_ 1519 ASAactivationRequest2 "0b00";
BA_ "Event" SG_ 1519 CurrentUserState_v2 "true";
BA_ "Event" SG_ 1519 CurrentUserState_v2 "true";
BA_ "Event" SG_ 1519 CurrentUserState_v2 "true";
BA_ "Event" SG_ 1519 CurrentUserState_v2 "true";
BA_ "Unavailable_Value" SG_ 1519 CurrentUserState_v2 "0b111";
BA_ "Event" SG_ 1519 SuspensionSettingRequest2 "true";
BA_ "Event" SG_ 1519 SuspensionSettingRequest2 "true";
BA_ "Event" SG_ 1519 SuspensionSettingRequest2 "true";
BA_ "Event" SG_ 1519 SuspensionSettingRequest2 "true";
BA_ "Unavailable_Value" SG_ 1519 SuspensionSettingRequest2 "0b000";
BA_ "Event" SG_ 1519 SteeringSettingRequest2_v2 "true";
BA_ "Event" SG_ 1519 SteeringSettingRequest2_v2 "true";
BA_ "Event" SG_ 1519 SteeringSettingRequest2_v2 "true";
BA_ "Event" SG_ 1519 SteeringSettingRequest2_v2 "true";
BA_ "Unavailable_Value" SG_ 1519 SteeringSettingRequest2_v2 "0b0000";
BA_ "Event" SG_ 1519 MC_PositionChangeRequest "true";
BA_ "Event" SG_ 1519 MC_PositionChangeRequest "true";
BA_ "Event" SG_ 1519 MC_PositionChangeRequest "true";
BA_ "Event" SG_ 1519 MC_PositionChangeRequest "true";
BA_ "Unavailable_Value" SG_ 1519 MC_PositionChangeRequest "0x0";
BA_ "Event" SG_ 1519 PowerTrainSettingRequest2 "true";
BA_ "Event" SG_ 1519 PowerTrainSettingRequest2 "true";
BA_ "Event" SG_ 1519 PowerTrainSettingRequest2 "true";
BA_ "Event" SG_ 1519 PowerTrainSettingRequest2 "true";
BA_ "Unavailable_Value" SG_ 1519 PowerTrainSettingRequest2 "0x0";
BA_ "Event" SG_ 1519 ClimAQSSensitivityRequest "true";
BA_ "Event" SG_ 1519 ClimAQSSensitivityRequest "true";
BA_ "Event" SG_ 1519 ClimAQSSensitivityRequest "true";
BA_ "Event" SG_ 1519 ClimAQSSensitivityRequest "true";
BA_ "Unavailable_Value" SG_ 1519 ClimAQSSensitivityRequest "0b000";
BA_ "Event" SG_ 1519 UserProfileResetRequest "true";
BA_ "Event" SG_ 1519 UserProfileResetRequest "true";
BA_ "Event" SG_ 1519 UserProfileResetRequest "true";
BA_ "Event" SG_ 1519 UserProfileResetRequest "true";
BA_ "Unavailable_Value" SG_ 1519 UserProfileResetRequest "0b000";
BA_ "Event" SG_ 1519 MC_ActivationRequest "true";
BA_ "Event" SG_ 1519 MC_ActivationRequest "true";
BA_ "Event" SG_ 1519 MC_ActivationRequest "true";
BA_ "Event" SG_ 1519 MC_ActivationRequest "true";
BA_ "Unavailable_Value" SG_ 1519 MC_ActivationRequest "0b00";
BA_ "Event" SG_ 1519 MC_PositionRecallRequest "true";
BA_ "Event" SG_ 1519 MC_PositionRecallRequest "true";
BA_ "Event" SG_ 1519 MC_PositionRecallRequest "true";
BA_ "Event" SG_ 1519 MC_PositionRecallRequest "true";
BA_ "Unavailable_Value" SG_ 1519 MC_PositionRecallRequest "0x0";
BA_ "Event" SG_ 1519 VMCSettingRequest "true";
BA_ "Event" SG_ 1519 VMCSettingRequest "true";
BA_ "Event" SG_ 1519 VMCSettingRequest "true";
BA_ "Event" SG_ 1519 VMCSettingRequest "true";
BA_ "Unavailable_Value" SG_ 1519 VMCSettingRequest "0x0";
BA_ "Event" SG_ 1519 MC_PositionCalculate "true";
BA_ "Event" SG_ 1519 MC_PositionCalculate "true";
BA_ "Event" SG_ 1519 MC_PositionCalculate "true";
BA_ "Event" SG_ 1519 MC_PositionCalculate "true";
BA_ "Unavailable_Value" SG_ 1519 MC_PositionCalculate "0x0";
BA_ "Event" SG_ 1519 MC_PositionSaveRequest "true";
BA_ "Event" SG_ 1519 MC_PositionSaveRequest "true";
BA_ "Event" SG_ 1519 MC_PositionSaveRequest "true";
BA_ "Event" SG_ 1519 MC_PositionSaveRequest "true";
BA_ "Unavailable_Value" SG_ 1519 MC_PositionSaveRequest "0x0";
BA_ "Event" SG_ 1523 EcomodeRangeIncreaseDisplay "true";
BA_ "Event" SG_ 1523 EcomodeRangeIncreaseDisplay "true";
BA_ "Event" SG_ 1523 EcomodeRangeIncreaseDisplay "true";
BA_ "Event" SG_ 1523 EcomodeRangeIncreaseDisplay "true";
BA_ "Unavailable_Value" SG_ 1523 EcomodeRangeIncreaseDisplay "0x00";
BA_ "Unavailable_Value" SG_ 1523 HVbatInstantInputPower_v2 "0x7FF";
BA_ "Event" SG_ 1523 HVchargeDisplayState "true";
BA_ "Event" SG_ 1523 HVchargeDisplayState "true";
BA_ "Event" SG_ 1523 HVchargeDisplayState "true";
BA_ "Event" SG_ 1523 HVchargeDisplayState "true";
BA_ "Unavailable_Value" SG_ 1523 HVchargeDisplayState "0b0";
BA_ "Event" SG_ 1529 HUD_AutoDimmingRequest2 "true";
BA_ "Event" SG_ 1529 HUD_AutoDimmingRequest2 "true";
BA_ "Event" SG_ 1529 HUD_AutoDimmingRequest2 "true";
BA_ "Event" SG_ 1529 HUD_AutoDimmingRequest2 "true";
BA_ "Unavailable_Value" SG_ 1529 HUD_AutoDimmingRequest2 "0b00";
BA_ "Event" SG_ 1529 HUD_ActivationRequest2 "true";
BA_ "Event" SG_ 1529 HUD_ActivationRequest2 "true";
BA_ "Event" SG_ 1529 HUD_ActivationRequest2 "true";
BA_ "Event" SG_ 1529 HUD_ActivationRequest2 "true";
BA_ "Unavailable_Value" SG_ 1529 HUD_ActivationRequest2 "0b00";
BA_ "Event" SG_ 1529 BSWson_ActivationRequest2 "true";
BA_ "Event" SG_ 1529 BSWson_ActivationRequest2 "true";
BA_ "Event" SG_ 1529 BSWson_ActivationRequest2 "true";
BA_ "Event" SG_ 1529 BSWson_ActivationRequest2 "true";
BA_ "Unavailable_Value" SG_ 1529 BSWson_ActivationRequest2 "0b00";
BA_ "Event" SG_ 1529 BCI_ActivationRequest2 "true";
BA_ "Event" SG_ 1529 BCI_ActivationRequest2 "true";
BA_ "Event" SG_ 1529 BCI_ActivationRequest2 "true";
BA_ "Event" SG_ 1529 BCI_ActivationRequest2 "true";
BA_ "Unavailable_Value" SG_ 1529 BCI_ActivationRequest2 "0b00";
BA_ "Event" SG_ 1529 ELKA_ActivationRequest2 "true";
BA_ "Event" SG_ 1529 ELKA_ActivationRequest2 "true";
BA_ "Event" SG_ 1529 ELKA_ActivationRequest2 "true";
BA_ "Event" SG_ 1529 ELKA_ActivationRequest2 "true";
BA_ "Unavailable_Value" SG_ 1529 ELKA_ActivationRequest2 "0b00";
BA_ "Event" SG_ 1529 HUD_PositionRequest2 "true";
BA_ "Event" SG_ 1529 HUD_PositionRequest2 "true";
BA_ "Event" SG_ 1529 HUD_PositionRequest2 "true";
BA_ "Event" SG_ 1529 HUD_PositionRequest2 "true";
BA_ "Unavailable_Value" SG_ 1529 HUD_PositionRequest2 "0x0";
BA_ "Event" SG_ 1529 FCW_SensibilityRequest2 "true";
BA_ "Event" SG_ 1529 FCW_SensibilityRequest2 "true";
BA_ "Event" SG_ 1529 FCW_SensibilityRequest2 "true";
BA_ "Event" SG_ 1529 FCW_SensibilityRequest2 "true";
BA_ "Unavailable_Value" SG_ 1529 FCW_SensibilityRequest2 "0b000";
BA_ "Event" SG_ 1529 HUD_DayLuminosityRequest2 "true";
BA_ "Event" SG_ 1529 HUD_DayLuminosityRequest2 "true";
BA_ "Event" SG_ 1529 HUD_DayLuminosityRequest2 "true";
BA_ "Event" SG_ 1529 HUD_DayLuminosityRequest2 "true";
BA_ "Unavailable_Value" SG_ 1529 HUD_DayLuminosityRequest2 "0x00";
BA_ "Event" SG_ 1529 HUD_NightLuminosityRequest2 "true";
BA_ "Event" SG_ 1529 HUD_NightLuminosityRequest2 "true";
BA_ "Event" SG_ 1529 HUD_NightLuminosityRequest2 "true";
BA_ "Event" SG_ 1529 HUD_NightLuminosityRequest2 "true";
BA_ "Unavailable_Value" SG_ 1529 HUD_NightLuminosityRequest2 "0x00";
BA_ "Event" SG_ 1529 WAL_ActivationRequest2 "true";
BA_ "Event" SG_ 1529 WAL_ActivationRequest2 "true";
BA_ "Event" SG_ 1529 WAL_ActivationRequest2 "true";
BA_ "Event" SG_ 1529 WAL_ActivationRequest2 "true";
BA_ "Unavailable_Value" SG_ 1529 WAL_ActivationRequest2 "0b00";
BA_ "Event" SG_ 1529 APPRUN_ActivationRequest2 "true";
BA_ "Event" SG_ 1529 APPRUN_ActivationRequest2 "true";
BA_ "Event" SG_ 1529 APPRUN_ActivationRequest2 "true";
BA_ "Event" SG_ 1529 APPRUN_ActivationRequest2 "true";
BA_ "Unavailable_Value" SG_ 1529 APPRUN_ActivationRequest2 "0b00";
BA_ "Event" SG_ 1531 AutoFrontWiperActivationRequest2 "true";
BA_ "Event" SG_ 1531 AutoFrontWiperActivationRequest2 "true";
BA_ "Event" SG_ 1531 AutoFrontWiperActivationRequest2 "true";
BA_ "Event" SG_ 1531 AutoFrontWiperActivationRequest2 "true";
BA_ "Unavailable_Value" SG_ 1531 AutoFrontWiperActivationRequest2 "0b00";
BA_ "Event" SG_ 1531 AHL_ActivationRequest2 "true";
BA_ "Event" SG_ 1531 AHL_ActivationRequest2 "true";
BA_ "Event" SG_ 1531 AHL_ActivationRequest2 "true";
BA_ "Event" SG_ 1531 AHL_ActivationRequest2 "true";
BA_ "Unavailable_Value" SG_ 1531 AHL_ActivationRequest2 "0b00";
BA_ "Event" SG_ 1531 ParkAssistVolumeRequest2 "true";
BA_ "Event" SG_ 1531 ParkAssistVolumeRequest2 "true";
BA_ "Event" SG_ 1531 ParkAssistVolumeRequest2 "true";
BA_ "Event" SG_ 1531 ParkAssistVolumeRequest2 "true";
BA_ "Unavailable_Value" SG_ 1531 ParkAssistVolumeRequest2 "0b000";
BA_ "Event" SG_ 1531 IKeyAccessActivationRequest2 "true";
BA_ "Event" SG_ 1531 IKeyAccessActivationRequest2 "true";
BA_ "Event" SG_ 1531 IKeyAccessActivationRequest2 "true";
BA_ "Event" SG_ 1531 IKeyAccessActivationRequest2 "true";
BA_ "Unavailable_Value" SG_ 1531 IKeyAccessActivationRequest2 "0b00";
BA_ "Event" SG_ 1531 FrontRearWiperDropRequest2 "true";
BA_ "Event" SG_ 1531 FrontRearWiperDropRequest2 "true";
BA_ "Event" SG_ 1531 FrontRearWiperDropRequest2 "true";
BA_ "Event" SG_ 1531 FrontRearWiperDropRequest2 "true";
BA_ "Unavailable_Value" SG_ 1531 FrontRearWiperDropRequest2 "0b00";
BA_ "Event" SG_ 1531 FrontParkAssistActivationReq2 "true";
BA_ "Event" SG_ 1531 FrontParkAssistActivationReq2 "true";
BA_ "Event" SG_ 1531 FrontParkAssistActivationReq2 "true";
BA_ "Event" SG_ 1531 FrontParkAssistActivationReq2 "true";
BA_ "Unavailable_Value" SG_ 1531 FrontParkAssistActivationReq2 "0b00";
BA_ "Event" SG_ 1531 AutoRearWiperActivationRequest2 "true";
BA_ "Event" SG_ 1531 AutoRearWiperActivationRequest2 "true";
BA_ "Event" SG_ 1531 AutoRearWiperActivationRequest2 "true";
BA_ "Event" SG_ 1531 AutoRearWiperActivationRequest2 "true";
BA_ "Unavailable_Value" SG_ 1531 AutoRearWiperActivationRequest2 "0b00";
BA_ "Event" SG_ 1531 WGSactivationRequest2 "true";
BA_ "Event" SG_ 1531 WGSactivationRequest2 "true";
BA_ "Event" SG_ 1531 WGSactivationRequest2 "true";
BA_ "Event" SG_ 1531 WGSactivationRequest2 "true";
BA_ "Unavailable_Value" SG_ 1531 WGSactivationRequest2 "0b00";
BA_ "Event" SG_ 1531 SingleDoorOpeningActivationReq2 "true";
BA_ "Event" SG_ 1531 SingleDoorOpeningActivationReq2 "true";
BA_ "Event" SG_ 1531 SingleDoorOpeningActivationReq2 "true";
BA_ "Event" SG_ 1531 SingleDoorOpeningActivationReq2 "true";
BA_ "Unavailable_Value" SG_ 1531 SingleDoorOpeningActivationReq2 "0b00";
BA_ "Event" SG_ 1531 RearParkAssistActivationReq2 "true";
BA_ "Event" SG_ 1531 RearParkAssistActivationReq2 "true";
BA_ "Event" SG_ 1531 RearParkAssistActivationReq2 "true";
BA_ "Event" SG_ 1531 RearParkAssistActivationReq2 "true";
BA_ "Unavailable_Value" SG_ 1531 RearParkAssistActivationReq2 "0b00";
BA_ "Event" SG_ 1531 AutoLightSensitivityRequest2 "true";
BA_ "Event" SG_ 1531 AutoLightSensitivityRequest2 "true";
BA_ "Event" SG_ 1531 AutoLightSensitivityRequest2 "true";
BA_ "Event" SG_ 1531 AutoLightSensitivityRequest2 "true";
BA_ "Unavailable_Value" SG_ 1531 AutoLightSensitivityRequest2 "0b000";
BA_ "Event" SG_ 1531 AutoReLockActivationReq2 "true";
BA_ "Event" SG_ 1531 AutoReLockActivationReq2 "true";
BA_ "Event" SG_ 1531 AutoReLockActivationReq2 "true";
BA_ "Event" SG_ 1531 AutoReLockActivationReq2 "true";
BA_ "Unavailable_Value" SG_ 1531 AutoReLockActivationReq2 "0b00";
BA_ "Event" SG_ 1531 MotorwayFlashersNumberRequest2 "true";
BA_ "Event" SG_ 1531 MotorwayFlashersNumberRequest2 "true";
BA_ "Event" SG_ 1531 MotorwayFlashersNumberRequest2 "true";
BA_ "Event" SG_ 1531 MotorwayFlashersNumberRequest2 "true";
BA_ "Unavailable_Value" SG_ 1531 MotorwayFlashersNumberRequest2 "0b000";
BA_ "Event" SG_ 1531 AutoFMHactivationRequest2 "true";
BA_ "Event" SG_ 1531 AutoFMHactivationRequest2 "true";
BA_ "Event" SG_ 1531 AutoFMHactivationRequest2 "true";
BA_ "Event" SG_ 1531 AutoFMHactivationRequest2 "true";
BA_ "Unavailable_Value" SG_ 1531 AutoFMHactivationRequest2 "0b00";
BA_ "Event" SG_ 1531 SilentModeActivationRequest2 "true";
BA_ "Event" SG_ 1531 SilentModeActivationRequest2 "true";
BA_ "Event" SG_ 1531 SilentModeActivationRequest2 "true";
BA_ "Event" SG_ 1531 SilentModeActivationRequest2 "true";
BA_ "Unavailable_Value" SG_ 1531 SilentModeActivationRequest2 "0b00";
BA_ "Event" SG_ 1531 AutoLockActivationReq2 "true";
BA_ "Event" SG_ 1531 AutoLockActivationReq2 "true";
BA_ "Event" SG_ 1531 AutoLockActivationReq2 "true";
BA_ "Event" SG_ 1531 AutoLockActivationReq2 "true";
BA_ "Unavailable_Value" SG_ 1531 AutoLockActivationReq2 "0b000";
BA_ "Event" SG_ 1531 AutoUnLockActivationReq2 "true";
BA_ "Event" SG_ 1531 AutoUnLockActivationReq2 "true";
BA_ "Event" SG_ 1531 AutoUnLockActivationReq2 "true";
BA_ "Event" SG_ 1531 AutoUnLockActivationReq2 "true";
BA_ "Unavailable_Value" SG_ 1531 AutoUnLockActivationReq2 "0b000";
BA_ "Event" SG_ 1531 WAC_APRUN_ActivationRequest2 "true";
BA_ "Event" SG_ 1531 WAC_APRUN_ActivationRequest2 "true";
BA_ "Event" SG_ 1531 WAC_APRUN_ActivationRequest2 "true";
BA_ "Event" SG_ 1531 WAC_APRUN_ActivationRequest2 "true";
BA_ "Unavailable_Value" SG_ 1531 WAC_APRUN_ActivationRequest2 "0b00";
BA_ "Event" SG_ 1531 ParkAssistSensitivityRequest2 "true";
BA_ "Event" SG_ 1531 ParkAssistSensitivityRequest2 "true";
BA_ "Event" SG_ 1531 ParkAssistSensitivityRequest2 "true";
BA_ "Event" SG_ 1531 ParkAssistSensitivityRequest2 "true";
BA_ "Unavailable_Value" SG_ 1531 ParkAssistSensitivityRequest2 "0b000";
BA_ "Event" SG_ 1531 AutoFoldingActivationRequest2 "true";
BA_ "Event" SG_ 1531 AutoFoldingActivationRequest2 "true";
BA_ "Event" SG_ 1531 AutoFoldingActivationRequest2 "true";
BA_ "Event" SG_ 1531 AutoFoldingActivationRequest2 "true";
BA_ "Unavailable_Value" SG_ 1531 AutoFoldingActivationRequest2 "0b000";
BA_ "Event" SG_ 1531 PredictiveShiftActivationRequest2 "true";
BA_ "Event" SG_ 1531 PredictiveShiftActivationRequest2 "true";
BA_ "Event" SG_ 1531 PredictiveShiftActivationRequest2 "true";
BA_ "Event" SG_ 1531 PredictiveShiftActivationRequest2 "true";
BA_ "Unavailable_Value" SG_ 1531 PredictiveShiftActivationRequest2 "0b00";
BA_ "Event" SG_ 1531 AirCondEcoActivationRequest2 "true";
BA_ "Event" SG_ 1531 AirCondEcoActivationRequest2 "true";
BA_ "Event" SG_ 1531 AirCondEcoActivationRequest2 "true";
BA_ "Event" SG_ 1531 AirCondEcoActivationRequest2 "true";
BA_ "Unavailable_Value" SG_ 1531 AirCondEcoActivationRequest2 "0b00";
BA_ "Event" SG_ 1531 CruiseEcoActivationRequest2 "true";
BA_ "Event" SG_ 1531 CruiseEcoActivationRequest2 "true";
BA_ "Event" SG_ 1531 CruiseEcoActivationRequest2 "true";
BA_ "Event" SG_ 1531 CruiseEcoActivationRequest2 "true";
BA_ "Unavailable_Value" SG_ 1531 CruiseEcoActivationRequest2 "0b00";
BA_ "Event" SG_ 1531 AutoFMHdurationRequest2 "true";
BA_ "Event" SG_ 1531 AutoFMHdurationRequest2 "true";
BA_ "Event" SG_ 1531 AutoFMHdurationRequest2 "true";
BA_ "Event" SG_ 1531 AutoFMHdurationRequest2 "true";
BA_ "Unavailable_Value" SG_ 1531 AutoFMHdurationRequest2 "0x0";
BA_ "Event" SG_ 1531 AmbientLightingPatternRequest2 "true";
BA_ "Event" SG_ 1531 AmbientLightingPatternRequest2 "true";
BA_ "Event" SG_ 1531 AmbientLightingPatternRequest2 "true";
BA_ "Event" SG_ 1531 AmbientLightingPatternRequest2 "true";
BA_ "Unavailable_Value" SG_ 1531 AmbientLightingPatternRequest2 "0b00";
BA_ "Event" SG_ 1531 ISS_EcoActivationRequest2 "true";
BA_ "Event" SG_ 1531 ISS_EcoActivationRequest2 "true";
BA_ "Event" SG_ 1531 ISS_EcoActivationRequest2 "true";
BA_ "Event" SG_ 1531 ISS_EcoActivationRequest2 "true";
BA_ "Unavailable_Value" SG_ 1531 ISS_EcoActivationRequest2 "0b00";
BA_ "Event" SG_ 1537 ACC_TargetDistanceAlert "true";
BA_ "Event" SG_ 1537 ACC_TargetDistanceAlert "true";
BA_ "Event" SG_ 1537 ACC_TargetDistanceAlert "true";
BA_ "Event" SG_ 1537 ACC_TargetDistanceAlert "true";
BA_ "Unavailable_Value" SG_ 1537 ACC_TargetDistanceAlert "0b00";
BA_ "Event" SG_ 1537 ACC_SpeedSettingDisplay "true";
BA_ "Event" SG_ 1537 ACC_SpeedSettingDisplay "true";
BA_ "Event" SG_ 1537 ACC_SpeedSettingDisplay "true";
BA_ "Event" SG_ 1537 ACC_SpeedSettingDisplay "true";
BA_ "Unavailable_Value" SG_ 1537 ACC_SpeedSettingDisplay "0xFF";
BA_ "Event" SG_ 1537 LCA_ActivationState "true";
BA_ "Event" SG_ 1537 LCA_ActivationState "true";
BA_ "Event" SG_ 1537 LCA_ActivationState "true";
BA_ "Event" SG_ 1537 LCA_ActivationState "true";
BA_ "Unavailable_Value" SG_ 1537 LCA_ActivationState "0b0";
BA_ "Event" SG_ 1537 ADL3_DisclaimerAcknowledgement "true";
BA_ "Event" SG_ 1537 ADL3_DisclaimerAcknowledgement "true";
BA_ "Event" SG_ 1537 ADL3_DisclaimerAcknowledgement "true";
BA_ "Event" SG_ 1537 ADL3_DisclaimerAcknowledgement "true";
BA_ "Unavailable_Value" SG_ 1537 ADL3_DisclaimerAcknowledgement "0b0";
BA_ "Event" SG_ 1537 ContextSpeed_ActivationState "true";
BA_ "Event" SG_ 1537 ContextSpeed_ActivationState "true";
BA_ "Event" SG_ 1537 ContextSpeed_ActivationState "true";
BA_ "Event" SG_ 1537 ContextSpeed_ActivationState "true";
BA_ "Unavailable_Value" SG_ 1537 ContextSpeed_ActivationState "0b00";
BA_ "Event" SG_ 1537 ContextRoad_ActivationState "true";
BA_ "Event" SG_ 1537 ContextRoad_ActivationState "true";
BA_ "Event" SG_ 1537 ContextRoad_ActivationState "true";
BA_ "Event" SG_ 1537 ContextRoad_ActivationState "true";
BA_ "Unavailable_Value" SG_ 1537 ContextRoad_ActivationState "0b11";
BA_ "Event" SG_ 1538 BCI_FailureDisplay "true";
BA_ "Event" SG_ 1538 BCI_FailureDisplay "true";
BA_ "Event" SG_ 1538 BCI_FailureDisplay "true";
BA_ "Event" SG_ 1538 BCI_FailureDisplay "true";
BA_ "Unavailable_Value" SG_ 1538 BCI_FailureDisplay "0b00";
BA_ "Event" SG_ 1538 LDW_AlertStatus "true";
BA_ "Event" SG_ 1538 LDW_AlertStatus "true";
BA_ "Event" SG_ 1538 LDW_AlertStatus "true";
BA_ "Event" SG_ 1538 LDW_AlertStatus "true";
BA_ "Unavailable_Value" SG_ 1538 LDW_AlertStatus "0b00";
BA_ "Event" SG_ 1538 EAP_AlertDisplay "true";
BA_ "Event" SG_ 1538 EAP_AlertDisplay "true";
BA_ "Event" SG_ 1538 EAP_AlertDisplay "true";
BA_ "Event" SG_ 1538 EAP_AlertDisplay "true";
BA_ "Unavailable_Value" SG_ 1538 EAP_AlertDisplay "0b0";
BA_ "Event" SG_ 1538 RAB_AlertStatus "true";
BA_ "Event" SG_ 1538 RAB_AlertStatus "true";
BA_ "Event" SG_ 1538 RAB_AlertStatus "true";
BA_ "Event" SG_ 1538 RAB_AlertStatus "true";
BA_ "Unavailable_Value" SG_ 1538 RAB_AlertStatus "0b00";
BA_ "Event" SG_ 1538 RAB_ActivationState "true";
BA_ "Event" SG_ 1538 RAB_ActivationState "true";
BA_ "Event" SG_ 1538 RAB_ActivationState "true";
BA_ "Event" SG_ 1538 RAB_ActivationState "true";
BA_ "Unavailable_Value" SG_ 1538 RAB_ActivationState "0b0";
BA_ "Event" SG_ 1538 WDA_ActivationState "true";
BA_ "Event" SG_ 1538 WDA_ActivationState "true";
BA_ "Event" SG_ 1538 WDA_ActivationState "true";
BA_ "Event" SG_ 1538 WDA_ActivationState "true";
BA_ "Unavailable_Value" SG_ 1538 WDA_ActivationState "0b0";
BA_ "Event" SG_ 1538 RAB_StatusDisplay "true";
BA_ "Event" SG_ 1538 RAB_StatusDisplay "true";
BA_ "Event" SG_ 1538 RAB_StatusDisplay "true";
BA_ "Event" SG_ 1538 RAB_StatusDisplay "true";
BA_ "Unavailable_Value" SG_ 1538 RAB_StatusDisplay "0b00";
BA_ "Event" SG_ 1538 RAB_FailureDisplay "true";
BA_ "Event" SG_ 1538 RAB_FailureDisplay "true";
BA_ "Event" SG_ 1538 RAB_FailureDisplay "true";
BA_ "Event" SG_ 1538 RAB_FailureDisplay "true";
BA_ "Unavailable_Value" SG_ 1538 RAB_FailureDisplay "0b00";
BA_ "Event" SG_ 1540 SR_ParkingEventNumberDisplay "true";
BA_ "Event" SG_ 1540 SR_ParkingEventNumberDisplay "true";
BA_ "Event" SG_ 1540 SR_ParkingEventNumberDisplay "true";
BA_ "Event" SG_ 1540 SR_MemoryStorageStatus "true";
BA_ "Event" SG_ 1540 SR_MemoryStorageStatus "true";
BA_ "Event" SG_ 1540 SR_MemoryStorageStatus "true";
BA_ "Unavailable_Value" SG_ 1540 SR_MemoryStorageStatus "0b0";
BA_ "Event" SG_ 1540 SDcardLockStatusDisplay "true";
BA_ "Event" SG_ 1540 SDcardLockStatusDisplay "true";
BA_ "Event" SG_ 1540 SDcardLockStatusDisplay "true";
BA_ "Unavailable_Value" SG_ 1540 SDcardLockStatusDisplay "0b0";
BA_ "Event" SG_ 1540 RestrictionModeState "true";
BA_ "Event" SG_ 1540 RestrictionModeState "true";
BA_ "Event" SG_ 1540 RestrictionModeState "true";
BA_ "Unavailable_Value" SG_ 1540 RestrictionModeState "0b0";
BA_ "Event" SG_ 1540 ParkingModeState "true";
BA_ "Event" SG_ 1540 ParkingModeState "true";
BA_ "Event" SG_ 1540 ParkingModeState "true";
BA_ "Unavailable_Value" SG_ 1540 ParkingModeState "0b0";
BA_ "Event" SG_ 1540 ContinuousModeState "true";
BA_ "Event" SG_ 1540 ContinuousModeState "true";
BA_ "Event" SG_ 1540 ContinuousModeState "true";
BA_ "Unavailable_Value" SG_ 1540 ContinuousModeState "0b0";
BA_ "Event" SG_ 1540 SR_UserEventPhotoStatusDisplay "true";
BA_ "Event" SG_ 1540 SR_UserEventPhotoStatusDisplay "true";
BA_ "Event" SG_ 1540 SR_UserEventPhotoStatusDisplay "true";
BA_ "Unavailable_Value" SG_ 1540 SR_UserEventPhotoStatusDisplay "0b00";
BA_ "Event" SG_ 1540 SR_StoragePhotoStatusDisplay "true";
BA_ "Event" SG_ 1540 SR_StoragePhotoStatusDisplay "true";
BA_ "Event" SG_ 1540 SR_StoragePhotoStatusDisplay "true";
BA_ "Unavailable_Value" SG_ 1540 SR_StoragePhotoStatusDisplay "0b0";
BA_ "Event" SG_ 1540 SR_ShockDetectedDisplay "true";
BA_ "Event" SG_ 1540 SR_ShockDetectedDisplay "true";
BA_ "Event" SG_ 1540 SR_ShockDetectedDisplay "true";
BA_ "Unavailable_Value" SG_ 1540 SR_ShockDetectedDisplay "0b0";
BA_ "Event" SG_ 1540 SR_RestrictionModeDisplay "true";
BA_ "Event" SG_ 1540 SR_RestrictionModeDisplay "true";
BA_ "Event" SG_ 1540 SR_RestrictionModeDisplay "true";
BA_ "Unavailable_Value" SG_ 1540 SR_RestrictionModeDisplay "0b0";
BA_ "Event" SG_ 1540 SR_AutoRecExtendedStatusDisplay "true";
BA_ "Event" SG_ 1540 SR_AutoRecExtendedStatusDisplay "true";
BA_ "Event" SG_ 1540 SR_AutoRecExtendedStatusDisplay "true";
BA_ "Unavailable_Value" SG_ 1540 SR_AutoRecExtendedStatusDisplay "0b0";
BA_ "Event" SG_ 1543 SilentModeActivationState "true";
BA_ "Event" SG_ 1543 SilentModeActivationState "true";
BA_ "Event" SG_ 1543 SilentModeActivationState "true";
BA_ "Event" SG_ 1543 SilentModeActivationState "true";
BA_ "Unavailable_Value" SG_ 1543 SilentModeActivationState "0b0";
BA_ "Event" SG_ 1543 MirrorDownDisplayRequest "true";
BA_ "Event" SG_ 1543 MirrorDownDisplayRequest "true";
BA_ "Event" SG_ 1543 MirrorDownDisplayRequest "true";
BA_ "Event" SG_ 1543 MirrorDownDisplayRequest "true";
BA_ "Unavailable_Value" SG_ 1543 MirrorDownDisplayRequest "0b0";
BA_ "Event" SG_ 1543 MirrorUpDisplayRequest "true";
BA_ "Event" SG_ 1543 MirrorUpDisplayRequest "true";
BA_ "Event" SG_ 1543 MirrorUpDisplayRequest "true";
BA_ "Event" SG_ 1543 MirrorUpDisplayRequest "true";
BA_ "Unavailable_Value" SG_ 1543 MirrorUpDisplayRequest "0b0";
BA_ "Event" SG_ 1543 MirrorRightDisplayRequest "true";
BA_ "Event" SG_ 1543 MirrorRightDisplayRequest "true";
BA_ "Event" SG_ 1543 MirrorRightDisplayRequest "true";
BA_ "Event" SG_ 1543 MirrorRightDisplayRequest "true";
BA_ "Unavailable_Value" SG_ 1543 MirrorRightDisplayRequest "0b0";
BA_ "Event" SG_ 1543 MirrorLeftDisplayRequest "true";
BA_ "Event" SG_ 1543 MirrorLeftDisplayRequest "true";
BA_ "Event" SG_ 1543 MirrorLeftDisplayRequest "true";
BA_ "Event" SG_ 1543 MirrorLeftDisplayRequest "true";
BA_ "Unavailable_Value" SG_ 1543 MirrorLeftDisplayRequest "0b0";
BA_ "Event" SG_ 1543 MirrorSideSelectDisplayRequest "true";
BA_ "Event" SG_ 1543 MirrorSideSelectDisplayRequest "true";
BA_ "Event" SG_ 1543 MirrorSideSelectDisplayRequest "true";
BA_ "Event" SG_ 1543 MirrorSideSelectDisplayRequest "true";
BA_ "Unavailable_Value" SG_ 1543 MirrorSideSelectDisplayRequest "0b00";
BA_ "Event" SG_ 1543 AmbiLightColorStatus_v2 "true";
BA_ "Event" SG_ 1543 AmbiLightColorStatus_v2 "true";
BA_ "Event" SG_ 1543 AmbiLightColorStatus_v2 "true";
BA_ "Event" SG_ 1543 AmbiLightColorStatus_v2 "true";
BA_ "Unavailable_Value" SG_ 1543 VR_AuthCondition_RL "0b0";
BA_ "Unavailable_Value" SG_ 1543 VR_AuthCondition_FR "0b0";
BA_ "Unavailable_Value" SG_ 1543 VR_AuthCondition_FL "0b0";
BA_ "Unavailable_Value" SG_ 1543 VR_AuthCondition_SSU "0b0";
BA_ "Unavailable_Value" SG_ 1543 VR_AuthCondition_SRU "0b0";
BA_ "Unavailable_Value" SG_ 1543 VR_AuthCondition_RR "0b0";
BA_ "Event" SG_ 1549 DriverSwitchMassageRequest "true";
BA_ "Event" SG_ 1549 DriverSwitchMassageRequest "true";
BA_ "Event" SG_ 1549 DriverSwitchMassageRequest "true";
BA_ "Event" SG_ 1549 DriverSwitchMassageRequest "true";
BA_ "Unavailable_Value" SG_ 1549 DriverSwitchMassageRequest "0b0";
BA_ "Event" SG_ 1549 MC_TutoControlsInhibitionReq "true";
BA_ "Event" SG_ 1549 MC_TutoControlsInhibitionReq "true";
BA_ "Event" SG_ 1549 MC_TutoControlsInhibitionReq "true";
BA_ "Event" SG_ 1549 MC_TutoControlsInhibitionReq "true";
BA_ "Unavailable_Value" SG_ 1549 MC_TutoControlsInhibitionReq "0b0";
BA_ "Event" SG_ 1549 MC_SeatAtSecureStopDisplayReq "true";
BA_ "Event" SG_ 1549 MC_SeatAtSecureStopDisplayReq "true";
BA_ "Event" SG_ 1549 MC_SeatAtSecureStopDisplayReq "true";
BA_ "Event" SG_ 1549 MC_SeatAtSecureStopDisplayReq "true";
BA_ "Unavailable_Value" SG_ 1549 MC_SeatAtSecureStopDisplayReq "0b000";
BA_ "Event" SG_ 1553 SecondRowCentralSeatStatus "true";
BA_ "Event" SG_ 1553 SecondRowCentralSeatStatus "true";
BA_ "Event" SG_ 1553 SecondRowCentralSeatStatus "true";
BA_ "Event" SG_ 1553 SecondRowCentralSeatStatus "true";
BA_ "Unavailable_Value" SG_ 1553 SecondRowCentralSeatStatus "0b000";
BA_ "Event" SG_ 1553 ClimForcedFreshDisplayStatus "true";
BA_ "Event" SG_ 1553 ClimForcedFreshDisplayStatus "true";
BA_ "Event" SG_ 1553 ClimForcedFreshDisplayStatus "true";
BA_ "Event" SG_ 1553 ClimForcedFreshDisplayStatus "true";
BA_ "Unavailable_Value" SG_ 1553 ClimForcedFreshDisplayStatus "0b0";
BA_ "Event" SG_ 1553 ClimForcedRecyDisplayStatus "true";
BA_ "Event" SG_ 1553 ClimForcedRecyDisplayStatus "true";
BA_ "Event" SG_ 1553 ClimForcedRecyDisplayStatus "true";
BA_ "Event" SG_ 1553 ClimForcedRecyDisplayStatus "true";
BA_ "Unavailable_Value" SG_ 1553 ClimForcedRecyDisplayStatus "0b0";
BA_ "Event" SG_ 1553 ClimForcedFreshDisplay "true";
BA_ "Event" SG_ 1553 ClimForcedFreshDisplay "true";
BA_ "Event" SG_ 1553 ClimForcedFreshDisplay "true";
BA_ "Event" SG_ 1553 ClimForcedFreshDisplay "true";
BA_ "Unavailable_Value" SG_ 1553 ClimForcedFreshDisplay "0b00";
BA_ "Event" SG_ 1553 ClimAQSSensitivityDisplay "true";
BA_ "Event" SG_ 1553 ClimAQSSensitivityDisplay "true";
BA_ "Event" SG_ 1553 ClimAQSSensitivityDisplay "true";
BA_ "Event" SG_ 1553 ClimAQSSensitivityDisplay "true";
BA_ "Unavailable_Value" SG_ 1553 ClimAQSSensitivityDisplay "0b000";
BA_ "Event" SG_ 1553 ClimExternalAirPollutionDisplay "true";
BA_ "Event" SG_ 1553 ClimExternalAirPollutionDisplay "true";
BA_ "Event" SG_ 1553 ClimExternalAirPollutionDisplay "true";
BA_ "Event" SG_ 1553 ClimExternalAirPollutionDisplay "true";
BA_ "Unavailable_Value" SG_ 1553 ClimExternalAirPollutionDisplay "0b000";
BA_ "Event" SG_ 1553 ClimRearDefrostDisplayStatus "true";
BA_ "Event" SG_ 1553 ClimRearDefrostDisplayStatus "true";
BA_ "Event" SG_ 1553 ClimRearDefrostDisplayStatus "true";
BA_ "Event" SG_ 1553 ClimRearDefrostDisplayStatus "true";
BA_ "Unavailable_Value" SG_ 1553 ClimRearDefrostDisplayStatus "0b0";
BA_ "Event" SG_ 1553 ClimExternAirPollutioDispStatus "true";
BA_ "Event" SG_ 1553 ClimExternAirPollutioDispStatus "true";
BA_ "Event" SG_ 1553 ClimExternAirPollutioDispStatus "true";
BA_ "Event" SG_ 1553 ClimExternAirPollutioDispStatus "true";
BA_ "Unavailable_Value" SG_ 1553 ClimExternAirPollutioDispStatus "0b0";
BA_ "Event" SG_ 1553 ClimLinkPriorityFLSeatAutoDisp "true";
BA_ "Event" SG_ 1553 ClimLinkPriorityFLSeatAutoDisp "true";
BA_ "Event" SG_ 1553 ClimLinkPriorityFLSeatAutoDisp "true";
BA_ "Event" SG_ 1553 ClimLinkPriorityFLSeatAutoDisp "true";
BA_ "Unavailable_Value" SG_ 1553 ClimLinkPriorityFLSeatAutoDisp "0b000";
BA_ "Event" SG_ 1553 ClimLinkPriorityFRSeatAutoDisp "true";
BA_ "Event" SG_ 1553 ClimLinkPriorityFRSeatAutoDisp "true";
BA_ "Event" SG_ 1553 ClimLinkPriorityFRSeatAutoDisp "true";
BA_ "Event" SG_ 1553 ClimLinkPriorityFRSeatAutoDisp "true";
BA_ "Unavailable_Value" SG_ 1553 ClimLinkPriorityFRSeatAutoDisp "0b000";
BA_ "Event" SG_ 1553 FrontRightSeatDisplayStatus "true";
BA_ "Event" SG_ 1553 FrontRightSeatDisplayStatus "true";
BA_ "Event" SG_ 1553 FrontRightSeatDisplayStatus "true";
BA_ "Event" SG_ 1553 FrontRightSeatDisplayStatus "true";
BA_ "Unavailable_Value" SG_ 1553 FrontRightSeatDisplayStatus "0b0";
BA_ "Event" SG_ 1553 FrontRightSeatStatus "true";
BA_ "Event" SG_ 1553 FrontRightSeatStatus "true";
BA_ "Event" SG_ 1553 FrontRightSeatStatus "true";
BA_ "Event" SG_ 1553 FrontRightSeatStatus "true";
BA_ "Unavailable_Value" SG_ 1553 FrontRightSeatStatus "0b000";
BA_ "Event" SG_ 1553 FrontLeftSeatStatus "true";
BA_ "Event" SG_ 1553 FrontLeftSeatStatus "true";
BA_ "Event" SG_ 1553 FrontLeftSeatStatus "true";
BA_ "Event" SG_ 1553 FrontLeftSeatStatus "true";
BA_ "Unavailable_Value" SG_ 1553 FrontLeftSeatStatus "0b000";
BA_ "Event" SG_ 1553 FrontLeftSeatDisplayStatus "true";
BA_ "Event" SG_ 1553 FrontLeftSeatDisplayStatus "true";
BA_ "Event" SG_ 1553 FrontLeftSeatDisplayStatus "true";
BA_ "Event" SG_ 1553 FrontLeftSeatDisplayStatus "true";
BA_ "Unavailable_Value" SG_ 1553 FrontLeftSeatDisplayStatus "0b0";
BA_ "Event" SG_ 1553 SecondRowLeftSeatAutoDisplay "true";
BA_ "Event" SG_ 1553 SecondRowLeftSeatAutoDisplay "true";
BA_ "Event" SG_ 1553 SecondRowLeftSeatAutoDisplay "true";
BA_ "Event" SG_ 1553 SecondRowLeftSeatAutoDisplay "true";
BA_ "Unavailable_Value" SG_ 1553 SecondRowLeftSeatAutoDisplay "0b00";
BA_ "Event" SG_ 1553 SecondRowRightSeatAutoDisplay "true";
BA_ "Event" SG_ 1553 SecondRowRightSeatAutoDisplay "true";
BA_ "Event" SG_ 1553 SecondRowRightSeatAutoDisplay "true";
BA_ "Event" SG_ 1553 SecondRowRightSeatAutoDisplay "true";
BA_ "Unavailable_Value" SG_ 1553 SecondRowRightSeatAutoDisplay "0b00";
BA_ "Event" SG_ 1553 FrontLeftSeatAutoDisplay "true";
BA_ "Event" SG_ 1553 FrontLeftSeatAutoDisplay "true";
BA_ "Event" SG_ 1553 FrontLeftSeatAutoDisplay "true";
BA_ "Event" SG_ 1553 FrontLeftSeatAutoDisplay "true";
BA_ "Unavailable_Value" SG_ 1553 FrontLeftSeatAutoDisplay "0b00";
BA_ "Event" SG_ 1553 FrontRightSeatAutoDisplay "true";
BA_ "Event" SG_ 1553 FrontRightSeatAutoDisplay "true";
BA_ "Event" SG_ 1553 FrontRightSeatAutoDisplay "true";
BA_ "Event" SG_ 1553 FrontRightSeatAutoDisplay "true";
BA_ "Unavailable_Value" SG_ 1553 FrontRightSeatAutoDisplay "0b00";
BA_ "Event" SG_ 1553 ThirdRowLeftSeatAutoDisplay "true";
BA_ "Event" SG_ 1553 ThirdRowLeftSeatAutoDisplay "true";
BA_ "Event" SG_ 1553 ThirdRowLeftSeatAutoDisplay "true";
BA_ "Event" SG_ 1553 ThirdRowLeftSeatAutoDisplay "true";
BA_ "Unavailable_Value" SG_ 1553 ThirdRowLeftSeatAutoDisplay "0b00";
BA_ "Event" SG_ 1553 ThirdRowRightSeatDisplayStatus "true";
BA_ "Event" SG_ 1553 ThirdRowRightSeatDisplayStatus "true";
BA_ "Event" SG_ 1553 ThirdRowRightSeatDisplayStatus "true";
BA_ "Event" SG_ 1553 ThirdRowRightSeatDisplayStatus "true";
BA_ "Unavailable_Value" SG_ 1553 ThirdRowRightSeatDisplayStatus "0b0";
BA_ "Event" SG_ 1553 ThirdRowLeftSeatDisplayStatus "true";
BA_ "Event" SG_ 1553 ThirdRowLeftSeatDisplayStatus "true";
BA_ "Event" SG_ 1553 ThirdRowLeftSeatDisplayStatus "true";
BA_ "Event" SG_ 1553 ThirdRowLeftSeatDisplayStatus "true";
BA_ "Unavailable_Value" SG_ 1553 ThirdRowLeftSeatDisplayStatus "0b0";
BA_ "Event" SG_ 1553 ThirdRowRightSeatAutoDisplay "true";
BA_ "Event" SG_ 1553 ThirdRowRightSeatAutoDisplay "true";
BA_ "Event" SG_ 1553 ThirdRowRightSeatAutoDisplay "true";
BA_ "Event" SG_ 1553 ThirdRowRightSeatAutoDisplay "true";
BA_ "Unavailable_Value" SG_ 1553 ThirdRowRightSeatAutoDisplay "0b00";
BA_ "Event" SG_ 1553 SecondRowRightSeatDisplayStatus "true";
BA_ "Event" SG_ 1553 SecondRowRightSeatDisplayStatus "true";
BA_ "Event" SG_ 1553 SecondRowRightSeatDisplayStatus "true";
BA_ "Event" SG_ 1553 SecondRowRightSeatDisplayStatus "true";
BA_ "Unavailable_Value" SG_ 1553 SecondRowRightSeatDisplayStatus "0b0";
BA_ "Event" SG_ 1553 SecondRowLeftSeatDisplayStatus "true";
BA_ "Event" SG_ 1553 SecondRowLeftSeatDisplayStatus "true";
BA_ "Event" SG_ 1553 SecondRowLeftSeatDisplayStatus "true";
BA_ "Event" SG_ 1553 SecondRowLeftSeatDisplayStatus "true";
BA_ "Unavailable_Value" SG_ 1553 SecondRowLeftSeatDisplayStatus "0b0";
BA_ "Event" SG_ 1553 ClimCabinTempDisplayUnit "true";
BA_ "Event" SG_ 1553 ClimCabinTempDisplayUnit "true";
BA_ "Event" SG_ 1553 ClimCabinTempDisplayUnit "true";
BA_ "Event" SG_ 1553 ClimCabinTempDisplayUnit "true";
BA_ "Unavailable_Value" SG_ 1553 ClimCabinTempDisplayUnit "0b0";
BA_ "Event" SG_ 1553 ClimLastFuncModifiedByCustomer_v2 "true";
BA_ "Event" SG_ 1553 ClimLastFuncModifiedByCustomer_v2 "true";
BA_ "Event" SG_ 1553 ClimLastFuncModifiedByCustomer_v2 "true";
BA_ "Event" SG_ 1553 ClimLastFuncModifiedByCustomer_v2 "true";
BA_ "Unavailable_Value" SG_ 1553 ClimLastFuncModifiedByCustomer_v2 "0x0";
BA_ "Event" SG_ 1553 ClimACmaxDisplay "true";
BA_ "Event" SG_ 1553 ClimACmaxDisplay "true";
BA_ "Event" SG_ 1553 ClimACmaxDisplay "true";
BA_ "Event" SG_ 1553 ClimACmaxDisplay "true";
BA_ "Event" SG_ 1557 GPS_LongitudePosition "true";
BA_ "Event" SG_ 1557 GPS_LongitudePosition "true";
BA_ "Event" SG_ 1557 GPS_LongitudePosition "true";
BA_ "Event" SG_ 1557 GPS_LongitudePosition "true";
BA_ "Unavailable_Value" SG_ 1557 GPS_LongitudePosition "null";
BA_ "Event" SG_ 1557 AWDSettingRequest2 "true";
BA_ "Event" SG_ 1557 AWDSettingRequest2 "true";
BA_ "Event" SG_ 1557 AWDSettingRequest2 "true";
BA_ "Event" SG_ 1557 AWDSettingRequest2 "true";
BA_ "Unavailable_Value" SG_ 1557 AWDSettingRequest2 "0b000";
BA_ "Event" SG_ 1557 GPS_LatitudePosition "true";
BA_ "Event" SG_ 1557 GPS_LatitudePosition "true";
BA_ "Event" SG_ 1557 GPS_LatitudePosition "true";
BA_ "Event" SG_ 1557 GPS_LatitudePosition "true";
BA_ "Unavailable_Value" SG_ 1557 GPS_LatitudePosition "null";
BA_ "Event" SG_ 1557 APAStart_SwitchRequest "true";
BA_ "Event" SG_ 1557 APAStart_SwitchRequest "true";
BA_ "Event" SG_ 1557 APAStart_SwitchRequest "true";
BA_ "Event" SG_ 1557 APAStart_SwitchRequest "true";
BA_ "Unavailable_Value" SG_ 1557 APAStart_SwitchRequest "0b0";
BA_ "Event" SG_ 1557 AirConditioningRequest "true";
BA_ "Event" SG_ 1557 AirConditioningRequest "true";
BA_ "Event" SG_ 1557 AirConditioningRequest "true";
BA_ "Event" SG_ 1557 AirConditioningRequest "true";
BA_ "Unavailable_Value" SG_ 1557 AirConditioningRequest "0b11";
BA_ "Event" SG_ 1557 LongSwitchRequest_AVM "true";
BA_ "Event" SG_ 1557 LongSwitchRequest_AVM "true";
BA_ "Event" SG_ 1557 LongSwitchRequest_AVM "true";
BA_ "Event" SG_ 1557 LongSwitchRequest_AVM "true";
BA_ "Unavailable_Value" SG_ 1557 LongSwitchRequest_AVM "0b0";
BA_ "Event" SG_ 1558 GPS_Orientation "true";
BA_ "Event" SG_ 1558 GPS_Orientation "true";
BA_ "Event" SG_ 1558 GPS_Orientation "true";
BA_ "Event" SG_ 1558 GPS_Orientation "true";
BA_ "Unavailable_Value" SG_ 1558 GPS_Orientation "null";
BA_ "Event" SG_ 1558 SwitchRequest_Trailer "true";
BA_ "Event" SG_ 1558 SwitchRequest_Trailer "true";
BA_ "Event" SG_ 1558 SwitchRequest_Trailer "true";
BA_ "Event" SG_ 1558 SwitchRequest_Trailer "true";
BA_ "Unavailable_Value" SG_ 1558 SwitchRequest_Trailer "0b0";
BA_ "Event" SG_ 1558 FAP_ScreenPressedDetected_2 "true";
BA_ "Event" SG_ 1558 FAP_ScreenPressedDetected_2 "true";
BA_ "Event" SG_ 1558 FAP_ScreenPressedDetected_2 "true";
BA_ "Event" SG_ 1558 FAP_ScreenPressedDetected_2 "true";
BA_ "Unavailable_Value" SG_ 1558 FAP_ScreenPressedDetected_2 "0b00";
BA_ "Event" SG_ 1558 ClimateDriverSetting "true";
BA_ "Event" SG_ 1558 ClimateDriverSetting "true";
BA_ "Event" SG_ 1558 ClimateDriverSetting "true";
BA_ "Event" SG_ 1558 ClimateDriverSetting "true";
BA_ "Unavailable_Value" SG_ 1558 ClimateDriverSetting "null";
BA_ "Event" SG_ 1558 APA_SwitchRequest "true";
BA_ "Event" SG_ 1558 APA_SwitchRequest "true";
BA_ "Event" SG_ 1558 APA_SwitchRequest "true";
BA_ "Event" SG_ 1558 APA_SwitchRequest "true";
BA_ "Unavailable_Value" SG_ 1558 APA_SwitchRequest "0b0";
BA_ "Event" SG_ 1558 FAP_ScreenPressCoordinateX_2 "true";
BA_ "Event" SG_ 1558 FAP_ScreenPressCoordinateX_2 "true";
BA_ "Event" SG_ 1558 FAP_ScreenPressCoordinateX_2 "true";
BA_ "Event" SG_ 1558 FAP_ScreenPressCoordinateX_2 "true";
BA_ "Event" SG_ 1558 FAP_ScreenPressCoordinateY_2 "true";
BA_ "Event" SG_ 1558 FAP_ScreenPressCoordinateY_2 "true";
BA_ "Event" SG_ 1558 FAP_ScreenPressCoordinateY_2 "true";
BA_ "Event" SG_ 1558 FAP_ScreenPressCoordinateY_2 "true";
BA_ "Unavailable_Value" SG_ 1558 FAP_ScreenPressCoordinateY_2 "null";
BA_ "Event" SG_ 1558 ADL3_DisclaimerResponse "true";
BA_ "Event" SG_ 1558 ADL3_DisclaimerResponse "true";
BA_ "Event" SG_ 1558 ADL3_DisclaimerResponse "true";
BA_ "Event" SG_ 1558 ADL3_DisclaimerResponse "true";
BA_ "Unavailable_Value" SG_ 1558 ADL3_DisclaimerResponse "0b00";
BA_ "Event" SG_ 1561 HVB_MaxCapacity_HEVC_v2 "true";
BA_ "Event" SG_ 1561 HVB_MaxCapacity_HEVC_v2 "true";
BA_ "Event" SG_ 1561 HVB_MaxCapacity_HEVC_v2 "true";
BA_ "Event" SG_ 1561 HVB_MaxCapacity_HEVC_v2 "true";
BA_ "Unavailable_Value" SG_ 1561 HVB_MaxCapacity_HEVC_v2 "0xFFFF";
BA_ "Event" SG_ 1564 ReacheableUSOCatDepartureTime "true";
BA_ "Event" SG_ 1564 ReacheableUSOCatDepartureTime "true";
BA_ "Event" SG_ 1564 ReacheableUSOCatDepartureTime "true";
BA_ "Event" SG_ 1564 ReacheableUSOCatDepartureTime "true";
BA_ "Unavailable_Value" SG_ 1564 ReacheableUSOCatDepartureTime "0x7F";
BA_ "Event" SG_ 1567 ESE_Soundtype_State "true";
BA_ "Event" SG_ 1567 ESE_Soundtype_State "true";
BA_ "Event" SG_ 1567 ESE_Soundtype_State "true";
BA_ "Event" SG_ 1567 ESE_Soundtype_State "true";
BA_ "Unavailable_Value" SG_ 1567 ESE_Soundtype_State "0x0";
BA_ "Unavailable_Value" SG_ 1567 Sound3DActivationState "0b0";
BA_ "Unavailable_Value" SG_ 1567 AudioPilotActivationState "0b0";
BA_ "Event" SG_ 1567 ESE_Soundvolume_State "true";
BA_ "Event" SG_ 1567 ESE_Soundvolume_State "true";
BA_ "Event" SG_ 1567 ESE_Soundvolume_State "true";
BA_ "Event" SG_ 1567 ESE_Soundvolume_State "true";
BA_ "Unavailable_Value" SG_ 1567 ESE_Soundvolume_State "0x1F";
BA_ "Unavailable_Value" SG_ 1568 EcoNavDistanceSaving "0x1FFFF";
BA_ "Event" SG_ 1570 ModeEcoIncitationPrompt "true";
BA_ "Event" SG_ 1570 ModeEcoIncitationPrompt "true";
BA_ "Event" SG_ 1570 ModeEcoIncitationPrompt "true";
BA_ "Event" SG_ 1570 ModeEcoIncitationPrompt "true";
BA_ "Unavailable_Value" SG_ 1570 ModeEcoIncitationPrompt "0b0";
BA_ "Unavailable_Value" SG_ 1570 ChargeProhibitionByRentalDisplay "0b0";
BA_ "Event" SG_ 1570 ChargeTimeForSOCtargetDest "true";
BA_ "Event" SG_ 1570 ChargeTimeForSOCtargetDest "true";
BA_ "Event" SG_ 1570 ChargeTimeForSOCtargetDest "true";
BA_ "Event" SG_ 1570 ChargeTimeForSOCtargetDest "true";
BA_ "Unavailable_Value" SG_ 1570 ChargeTimeForSOCtargetDest "0x1FF";
BA_ "Event" SG_ 1570 DCDCInputPower_HEVC "true";
BA_ "Event" SG_ 1570 DCDCInputPower_HEVC "true";
BA_ "Event" SG_ 1570 DCDCInputPower_HEVC "true";
BA_ "Event" SG_ 1570 DCDCInputPower_HEVC "true";
BA_ "Unavailable_Value" SG_ 1570 DCDCInputPower_HEVC "0x3F";
BA_ "Event" SG_ 1570 ChargeTimeIndexReachibilityFbk "true";
BA_ "Event" SG_ 1570 ChargeTimeIndexReachibilityFbk "true";
BA_ "Event" SG_ 1570 ChargeTimeIndexReachibilityFbk "true";
BA_ "Event" SG_ 1570 ChargeTimeIndexReachibilityFbk "true";
BA_ "Unavailable_Value" SG_ 1570 ChargeTimeIndexReachibilityFbk "0x0";
BA_ "Event" SG_ 1570 ChargingAlert_v2 "true";
BA_ "Event" SG_ 1570 ChargingAlert_v2 "true";
BA_ "Event" SG_ 1570 ChargingAlert_v2 "true";
BA_ "Event" SG_ 1570 ChargingAlert_v2 "true";
BA_ "Unavailable_Value" SG_ 1570 ChargingAlert_v2 "0x0";
BA_ "Event" SG_ 1570 ElectricalTractionAvailability "true";
BA_ "Event" SG_ 1570 ElectricalTractionAvailability "true";
BA_ "Event" SG_ 1570 ElectricalTractionAvailability "true";
BA_ "Event" SG_ 1570 ElectricalTractionAvailability "true";
BA_ "Unavailable_Value" SG_ 1570 ElectricalTractionAvailability "0b00";
BA_ "Unavailable_Value" SG_ 1570 ChargeAvailable "0b1";
BA_ "Unavailable_Value" SG_ 1572 TotalConsumption_LastTrip "0xFFF";
BA_ "Unavailable_Value" SG_ 1572 TotalRecovery_LastTrip "0xFFF";
BA_ "Event" SG_ 1578 DMC_ActivationState "true";
BA_ "Event" SG_ 1578 DMC_ActivationState "true";
BA_ "Event" SG_ 1578 DMC_ActivationState "true";
BA_ "Event" SG_ 1578 DMC_ActivationState "true";
BA_ "Unavailable_Value" SG_ 1578 DMC_ActivationState "0b11";
BA_ "Event" SG_ 1578 Drowsy_AlertActivationState "true";
BA_ "Event" SG_ 1578 Drowsy_AlertActivationState "true";
BA_ "Event" SG_ 1578 Drowsy_AlertActivationState "true";
BA_ "Event" SG_ 1578 Drowsy_AlertActivationState "true";
BA_ "Unavailable_Value" SG_ 1578 Drowsy_AlertActivationState "0b00";
BA_ "Event" SG_ 1593 ITM_FrontRearDefrostTypeConfig "true";
BA_ "Event" SG_ 1593 ITM_FrontRearDefrostTypeConfig "true";
BA_ "Event" SG_ 1593 ITM_FrontRearDefrostTypeConfig "true";
BA_ "Event" SG_ 1593 ITM_FrontRearDefrostTypeConfig "true";
BA_ "Event" SG_ 1593 ITM_ControlPanelTypeConfig "true";
BA_ "Event" SG_ 1593 ITM_ControlPanelTypeConfig "true";
BA_ "Event" SG_ 1593 ITM_ControlPanelTypeConfig "true";
BA_ "Event" SG_ 1593 ITM_ControlPanelTypeConfig "true";
BA_ "Unavailable_Value" SG_ 1593 ITM_ControlPanelTypeConfig "0b0";
BA_ "Event" SG_ 1593 ITM_TempControlTypeConfig "true";
BA_ "Event" SG_ 1593 ITM_TempControlTypeConfig "true";
BA_ "Event" SG_ 1593 ITM_TempControlTypeConfig "true";
BA_ "Event" SG_ 1593 ITM_TempControlTypeConfig "true";
BA_ "Event" SG_ 1593 ITM_TempRangeMinMaxConfig "true";
BA_ "Event" SG_ 1593 ITM_TempRangeMinMaxConfig "true";
BA_ "Event" SG_ 1593 ITM_TempRangeMinMaxConfig "true";
BA_ "Event" SG_ 1593 ITM_TempRangeMinMaxConfig "true";
BA_ "Event" SG_ 1593 ITM_VariableAirFlowConfig "true";
BA_ "Event" SG_ 1593 ITM_VariableAirFlowConfig "true";
BA_ "Event" SG_ 1593 ITM_VariableAirFlowConfig "true";
BA_ "Event" SG_ 1593 ITM_VariableAirFlowConfig "true";
BA_ "Unavailable_Value" SG_ 1593 ITM_VariableAirFlowConfig "0b0";
BA_ "Event" SG_ 1593 ITM_TemperatureRangeConfig "true";
BA_ "Event" SG_ 1593 ITM_TemperatureRangeConfig "true";
BA_ "Event" SG_ 1593 ITM_TemperatureRangeConfig "true";
BA_ "Event" SG_ 1593 ITM_TemperatureRangeConfig "true";
BA_ "Unavailable_Value" SG_ 1593 ITM_TemperatureRangeConfig "0x7F";
BA_ "Event" SG_ 1593 ITM_DriverZoneConfig "true";
BA_ "Event" SG_ 1593 ITM_DriverZoneConfig "true";
BA_ "Event" SG_ 1593 ITM_DriverZoneConfig "true";
BA_ "Event" SG_ 1593 ITM_DriverZoneConfig "true";
BA_ "Unavailable_Value" SG_ 1593 ITM_DriverZoneConfig "0b0";
BA_ "Event" SG_ 1593 ITM_SyncModeTypeConfig "true";
BA_ "Event" SG_ 1593 ITM_SyncModeTypeConfig "true";
BA_ "Event" SG_ 1593 ITM_SyncModeTypeConfig "true";
BA_ "Event" SG_ 1593 ITM_SyncModeTypeConfig "true";
BA_ "Unavailable_Value" SG_ 1593 ITM_SyncModeTypeConfig "0b000";
BA_ "Event" SG_ 1593 ITM_FlowDistrTypeConfig "true";
BA_ "Event" SG_ 1593 ITM_FlowDistrTypeConfig "true";
BA_ "Event" SG_ 1593 ITM_FlowDistrTypeConfig "true";
BA_ "Event" SG_ 1593 ITM_FlowDistrTypeConfig "true";
BA_ "Event" SG_ 1593 ITM_BlowingZoneTypeConfig "true";
BA_ "Event" SG_ 1593 ITM_BlowingZoneTypeConfig "true";
BA_ "Event" SG_ 1593 ITM_BlowingZoneTypeConfig "true";
BA_ "Event" SG_ 1593 ITM_BlowingZoneTypeConfig "true";
BA_ "Event" SG_ 1593 ITM_HumiditySensorConfig "true";
BA_ "Event" SG_ 1593 ITM_HumiditySensorConfig "true";
BA_ "Event" SG_ 1593 ITM_HumiditySensorConfig "true";
BA_ "Event" SG_ 1593 ITM_HumiditySensorConfig "true";
BA_ "Unavailable_Value" SG_ 1593 ITM_HumiditySensorConfig "0b0";
BA_ "Event" SG_ 1593 ITM_LeftBlowingMaxSpeedConfig "true";
BA_ "Event" SG_ 1593 ITM_LeftBlowingMaxSpeedConfig "true";
BA_ "Event" SG_ 1593 ITM_LeftBlowingMaxSpeedConfig "true";
BA_ "Event" SG_ 1593 ITM_LeftBlowingMaxSpeedConfig "true";
BA_ "Unavailable_Value" SG_ 1593 ITM_LeftBlowingMaxSpeedConfig "0xF";
BA_ "Event" SG_ 1593 ITM_RightBlowingMaxSpeedConfig "true";
BA_ "Event" SG_ 1593 ITM_RightBlowingMaxSpeedConfig "true";
BA_ "Event" SG_ 1593 ITM_RightBlowingMaxSpeedConfig "true";
BA_ "Event" SG_ 1593 ITM_RightBlowingMaxSpeedConfig "true";
BA_ "Unavailable_Value" SG_ 1593 ITM_RightBlowingMaxSpeedConfig "0xF";
BA_ "Event" SG_ 1593 ITM_ACControlTypeConfig "true";
BA_ "Event" SG_ 1593 ITM_ACControlTypeConfig "true";
BA_ "Event" SG_ 1593 ITM_ACControlTypeConfig "true";
BA_ "Event" SG_ 1593 ITM_ACControlTypeConfig "true";
BA_ "Unavailable_Value" SG_ 1593 ITM_ACControlTypeConfig "0b00";
BA_ "Event" SG_ 1593 ITM_AutoControlTypeConfig "true";
BA_ "Event" SG_ 1593 ITM_AutoControlTypeConfig "true";
BA_ "Event" SG_ 1593 ITM_AutoControlTypeConfig "true";
BA_ "Event" SG_ 1593 ITM_AutoControlTypeConfig "true";
BA_ "Unavailable_Value" SG_ 1593 ITM_AutoControlTypeConfig "0b000";
BA_ "Event" SG_ 1593 ITM_IdleStopHVACPriorityConfig "true";
BA_ "Event" SG_ 1593 ITM_IdleStopHVACPriorityConfig "true";
BA_ "Event" SG_ 1593 ITM_IdleStopHVACPriorityConfig "true";
BA_ "Event" SG_ 1593 ITM_IdleStopHVACPriorityConfig "true";
BA_ "Unavailable_Value" SG_ 1593 ITM_IdleStopHVACPriorityConfig "0b0";
BA_ "Event" SG_ 1593 ITM_ForestConfig "true";
BA_ "Event" SG_ 1593 ITM_ForestConfig "true";
BA_ "Event" SG_ 1593 ITM_ForestConfig "true";
BA_ "Event" SG_ 1593 ITM_ForestConfig "true";
BA_ "Unavailable_Value" SG_ 1593 ITM_ForestConfig "0b0";
BA_ "Event" SG_ 1593 ITM_AromaConfig "true";
BA_ "Event" SG_ 1593 ITM_AromaConfig "true";
BA_ "Event" SG_ 1593 ITM_AromaConfig "true";
BA_ "Event" SG_ 1593 ITM_AromaConfig "true";
BA_ "Unavailable_Value" SG_ 1593 ITM_AromaConfig "0b0";
BA_ "Event" SG_ 1593 ITM_RearLeftBlowMaxSpeedConfig "true";
BA_ "Event" SG_ 1593 ITM_RearLeftBlowMaxSpeedConfig "true";
BA_ "Event" SG_ 1593 ITM_RearLeftBlowMaxSpeedConfig "true";
BA_ "Event" SG_ 1593 ITM_RearLeftBlowMaxSpeedConfig "true";
BA_ "Unavailable_Value" SG_ 1593 ITM_RearLeftBlowMaxSpeedConfig "0xF";
BA_ "Event" SG_ 1593 ITM_RearRightBlowMaxSpeedConfig "true";
BA_ "Event" SG_ 1593 ITM_RearRightBlowMaxSpeedConfig "true";
BA_ "Event" SG_ 1593 ITM_RearRightBlowMaxSpeedConfig "true";
BA_ "Event" SG_ 1593 ITM_RearRightBlowMaxSpeedConfig "true";
BA_ "Unavailable_Value" SG_ 1593 ITM_RearRightBlowMaxSpeedConfig "0xF";
BA_ "Event" SG_ 1593 ITM_AQSMaxLevelConfig "true";
BA_ "Event" SG_ 1593 ITM_AQSMaxLevelConfig "true";
BA_ "Event" SG_ 1593 ITM_AQSMaxLevelConfig "true";
BA_ "Event" SG_ 1593 ITM_AQSMaxLevelConfig "true";
BA_ "Unavailable_Value" SG_ 1593 ITM_AQSMaxLevelConfig "0b000";
BA_ "Event" SG_ 1593 ITM_RecyclingTypeConfig "true";
BA_ "Event" SG_ 1593 ITM_RecyclingTypeConfig "true";
BA_ "Event" SG_ 1593 ITM_RecyclingTypeConfig "true";
BA_ "Event" SG_ 1593 ITM_RecyclingTypeConfig "true";
BA_ "Event" SG_ 1593 ITM_TrimHeaterConfig "true";
BA_ "Event" SG_ 1593 ITM_TrimHeaterConfig "true";
BA_ "Event" SG_ 1593 ITM_TrimHeaterConfig "true";
BA_ "Event" SG_ 1593 ITM_TrimHeaterConfig "true";
BA_ "Unavailable_Value" SG_ 1593 ITM_TrimHeaterConfig "0b0";
BA_ "Event" SG_ 1593 ITM_AirScarfConfig "true";
BA_ "Event" SG_ 1593 ITM_AirScarfConfig "true";
BA_ "Event" SG_ 1593 ITM_AirScarfConfig "true";
BA_ "Event" SG_ 1593 ITM_AirScarfConfig "true";
BA_ "Unavailable_Value" SG_ 1593 ITM_AirScarfConfig "0b0";
BA_ "Event" SG_ 1593 ITM_FrontSeatHeatVentilConfig "true";
BA_ "Event" SG_ 1593 ITM_FrontSeatHeatVentilConfig "true";
BA_ "Event" SG_ 1593 ITM_FrontSeatHeatVentilConfig "true";
BA_ "Event" SG_ 1593 ITM_FrontSeatHeatVentilConfig "true";
BA_ "Unavailable_Value" SG_ 1593 ITM_FrontSeatHeatVentilConfig "0b00";
BA_ "Event" SG_ 1593 ITM_SecondRowSeatHeatVentConfig "true";
BA_ "Event" SG_ 1593 ITM_SecondRowSeatHeatVentConfig "true";
BA_ "Event" SG_ 1593 ITM_SecondRowSeatHeatVentConfig "true";
BA_ "Event" SG_ 1593 ITM_SecondRowSeatHeatVentConfig "true";
BA_ "Unavailable_Value" SG_ 1593 ITM_SecondRowSeatHeatVentConfig "0b00";
BA_ "Event" SG_ 1593 ITM_ThirdRowSeatHeatVentConfig "true";
BA_ "Event" SG_ 1593 ITM_ThirdRowSeatHeatVentConfig "true";
BA_ "Event" SG_ 1593 ITM_ThirdRowSeatHeatVentConfig "true";
BA_ "Event" SG_ 1593 ITM_ThirdRowSeatHeatVentConfig "true";
BA_ "Unavailable_Value" SG_ 1593 ITM_ThirdRowSeatHeatVentConfig "0b00";
BA_ "Event" SG_ 1593 ITM_IRsensorConfig "true";
BA_ "Event" SG_ 1593 ITM_IRsensorConfig "true";
BA_ "Event" SG_ 1593 ITM_IRsensorConfig "true";
BA_ "Event" SG_ 1593 ITM_IRsensorConfig "true";
BA_ "Unavailable_Value" SG_ 1593 ITM_IRsensorConfig "0b0";
BA_ "Event" SG_ 1593 ITM_AirQualitySensorConfig "true";
BA_ "Event" SG_ 1593 ITM_AirQualitySensorConfig "true";
BA_ "Event" SG_ 1593 ITM_AirQualitySensorConfig "true";
BA_ "Event" SG_ 1593 ITM_AirQualitySensorConfig "true";
BA_ "Unavailable_Value" SG_ 1593 ITM_AirQualitySensorConfig "0b0";
BA_ "Event" SG_ 1594 ITM_EVHeaterControlConfig "true";
BA_ "Event" SG_ 1594 ITM_EVHeaterControlConfig "true";
BA_ "Event" SG_ 1594 ITM_EVHeaterControlConfig "true";
BA_ "Event" SG_ 1594 ITM_EVHeaterControlConfig "true";
BA_ "Unavailable_Value" SG_ 1594 ITM_EVHeaterControlConfig "0b0";
BA_ "Event" SG_ 1594 ITM_HeatedSteeringWheelConfig "true";
BA_ "Event" SG_ 1594 ITM_HeatedSteeringWheelConfig "true";
BA_ "Event" SG_ 1594 ITM_HeatedSteeringWheelConfig "true";
BA_ "Event" SG_ 1594 ITM_HeatedSteeringWheelConfig "true";
BA_ "Unavailable_Value" SG_ 1594 ITM_HeatedSteeringWheelConfig "0b00";
BA_ "Event" SG_ 1595 FOTA_ProgValueRequest "true";
BA_ "Event" SG_ 1595 FOTA_ProgValueRequest "true";
BA_ "Event" SG_ 1595 FOTA_ProgValueRequest "true";
BA_ "Event" SG_ 1595 FOTA_ProgValueRequest "true";
BA_ "Unavailable_Value" SG_ 1595 FOTA_ProgValueRequest "0x7FF";
BA_ "Event" SG_ 1595 TrailerGuidelineActivationRequest "true";
BA_ "Event" SG_ 1595 TrailerGuidelineActivationRequest "true";
BA_ "Event" SG_ 1595 TrailerGuidelineActivationRequest "true";
BA_ "Event" SG_ 1595 TrailerGuidelineActivationRequest "true";
BA_ "Unavailable_Value" SG_ 1595 TrailerGuidelineActivationRequest "0b00";
BA_ "Event" SG_ 1595 AmbientLightingColor_v2 "true";
BA_ "Event" SG_ 1595 AmbientLightingColor_v2 "true";
BA_ "Event" SG_ 1595 AmbientLightingColor_v2 "true";
BA_ "Event" SG_ 1595 AmbientLightingColor_v2 "true";
BA_ "Unavailable_Value" SG_ 1595 AmbientLightingColor_v2 "null";
BA_ "Event" SG_ 1595 HUD_RotationPositionRequest2 "true";
BA_ "Event" SG_ 1595 HUD_RotationPositionRequest2 "true";
BA_ "Event" SG_ 1595 HUD_RotationPositionRequest2 "true";
BA_ "Event" SG_ 1595 HUD_RotationPositionRequest2 "true";
BA_ "Unavailable_Value" SG_ 1595 HUD_RotationPositionRequest2 "0x0";
BA_ "Event" SG_ 1595 AVM_GuidelinesActivationRequest2 "true";
BA_ "Event" SG_ 1595 AVM_GuidelinesActivationRequest2 "true";
BA_ "Event" SG_ 1595 AVM_GuidelinesActivationRequest2 "true";
BA_ "Event" SG_ 1595 AVM_GuidelinesActivationRequest2 "true";
BA_ "Unavailable_Value" SG_ 1595 AVM_GuidelinesActivationRequest2 "0b000";
BA_ "Event" SG_ 1595 OffsetValue_Request2 "true";
BA_ "Event" SG_ 1595 OffsetValue_Request2 "true";
BA_ "Event" SG_ 1595 OffsetValue_Request2 "true";
BA_ "Event" SG_ 1595 OffsetValue_Request2 "true";
BA_ "Unavailable_Value" SG_ 1595 OffsetValue_Request2 "0x00";
BA_ "Event" SG_ 1595 AmbientLightingAreaADReq "true";
BA_ "Event" SG_ 1595 AmbientLightingAreaADReq "true";
BA_ "Event" SG_ 1595 AmbientLightingAreaADReq "true";
BA_ "Event" SG_ 1595 AmbientLightingAreaADReq "true";
BA_ "Unavailable_Value" SG_ 1595 AmbientLightingAreaADReq "0b00";
BA_ "Event" SG_ 1595 VolumAlarmActivationRequest2 "true";
BA_ "Event" SG_ 1595 VolumAlarmActivationRequest2 "true";
BA_ "Event" SG_ 1595 VolumAlarmActivationRequest2 "true";
BA_ "Event" SG_ 1595 VolumAlarmActivationRequest2 "true";
BA_ "Unavailable_Value" SG_ 1595 VolumAlarmActivationRequest2 "0b000";
BA_ "Event" SG_ 1595 ContextSpeed_ActivationRequest2 "true";
BA_ "Event" SG_ 1595 ContextSpeed_ActivationRequest2 "true";
BA_ "Event" SG_ 1595 ContextSpeed_ActivationRequest2 "true";
BA_ "Event" SG_ 1595 ContextSpeed_ActivationRequest2 "true";
BA_ "Unavailable_Value" SG_ 1595 ContextSpeed_ActivationRequest2 "0b000";
BA_ "Event" SG_ 1595 PreferedLaneAssist_Request2 "true";
BA_ "Event" SG_ 1595 PreferedLaneAssist_Request2 "true";
BA_ "Event" SG_ 1595 PreferedLaneAssist_Request2 "true";
BA_ "Event" SG_ 1595 PreferedLaneAssist_Request2 "true";
BA_ "Unavailable_Value" SG_ 1595 PreferedLaneAssist_Request2 "0b00";
BA_ "Event" SG_ 1595 OffsetActivation_Request2 "true";
BA_ "Event" SG_ 1595 OffsetActivation_Request2 "true";
BA_ "Event" SG_ 1595 OffsetActivation_Request2 "true";
BA_ "Event" SG_ 1595 OffsetActivation_Request2 "true";
BA_ "Unavailable_Value" SG_ 1595 OffsetActivation_Request2 "0b11";
BA_ "Event" SG_ 1595 FOTA_ProgRequest "true";
BA_ "Event" SG_ 1595 FOTA_ProgRequest "true";
BA_ "Event" SG_ 1595 FOTA_ProgRequest "true";
BA_ "Event" SG_ 1595 FOTA_ProgRequest "true";
BA_ "Unavailable_Value" SG_ 1595 FOTA_ProgRequest "0b00";
BA_ "Event" SG_ 1595 ContextRoad_ActivationRequest2 "true";
BA_ "Event" SG_ 1595 ContextRoad_ActivationRequest2 "true";
BA_ "Event" SG_ 1595 ContextRoad_ActivationRequest2 "true";
BA_ "Event" SG_ 1595 ContextRoad_ActivationRequest2 "true";
BA_ "Unavailable_Value" SG_ 1595 ContextRoad_ActivationRequest2 "0b00";
BA_ "Event" SG_ 1595 Drowsy_AlertActivationRequest2 "true";
BA_ "Event" SG_ 1595 Drowsy_AlertActivationRequest2 "true";
BA_ "Event" SG_ 1595 Drowsy_AlertActivationRequest2 "true";
BA_ "Event" SG_ 1595 Drowsy_AlertActivationRequest2 "true";
BA_ "Unavailable_Value" SG_ 1595 Drowsy_AlertActivationRequest2 "0b00";
BA_ "Event" SG_ 1595 RearViewRVC_CancelReason_RER "true";
BA_ "Event" SG_ 1595 RearViewRVC_CancelReason_RER "true";
BA_ "Event" SG_ 1595 RearViewRVC_CancelReason_RER "true";
BA_ "Event" SG_ 1595 RearViewRVC_CancelReason_RER "true";
BA_ "Unavailable_Value" SG_ 1595 RearViewRVC_CancelReason_RER "0b0";
BA_ "Event" SG_ 1595 ZoomAutoActivationRequest2 "true";
BA_ "Event" SG_ 1595 ZoomAutoActivationRequest2 "true";
BA_ "Event" SG_ 1595 ZoomAutoActivationRequest2 "true";
BA_ "Event" SG_ 1595 ZoomAutoActivationRequest2 "true";
BA_ "Unavailable_Value" SG_ 1595 ZoomAutoActivationRequest2 "0b00";
BA_ "Event" SG_ 1595 RearViewRVC_CancelReason "true";
BA_ "Event" SG_ 1595 RearViewRVC_CancelReason "true";
BA_ "Event" SG_ 1595 RearViewRVC_CancelReason "true";
BA_ "Event" SG_ 1595 RearViewRVC_CancelReason "true";
BA_ "Unavailable_Value" SG_ 1595 RearViewRVC_CancelReason "0b00";
BA_ "Event" SG_ 1595 HVbatteryWarmingRequest "true";
BA_ "Event" SG_ 1595 HVbatteryWarmingRequest "true";
BA_ "Event" SG_ 1595 HVbatteryWarmingRequest "true";
BA_ "Event" SG_ 1595 HVbatteryWarmingRequest "true";
BA_ "Unavailable_Value" SG_ 1595 HVbatteryWarmingRequest "0b00";
BA_ "Event" SG_ 1595 OSE_ActivationRequest2 "true";
BA_ "Event" SG_ 1595 OSE_ActivationRequest2 "true";
BA_ "Event" SG_ 1595 OSE_ActivationRequest2 "true";
BA_ "Event" SG_ 1595 OSE_ActivationRequest2 "true";
BA_ "Unavailable_Value" SG_ 1595 OSE_ActivationRequest2 "0b00";
BA_ "Event" SG_ 1595 DMC_ActivationRequest2 "true";
BA_ "Event" SG_ 1595 DMC_ActivationRequest2 "true";
BA_ "Event" SG_ 1595 DMC_ActivationRequest2 "true";
BA_ "Event" SG_ 1595 DMC_ActivationRequest2 "true";
BA_ "Unavailable_Value" SG_ 1595 DMC_ActivationRequest2 "0b00";
BA_ "Event" SG_ 1595 VirtualKeyActivationRequest "true";
BA_ "Event" SG_ 1595 VirtualKeyActivationRequest "true";
BA_ "Event" SG_ 1595 VirtualKeyActivationRequest "true";
BA_ "Event" SG_ 1595 VirtualKeyActivationRequest "true";
BA_ "Unavailable_Value" SG_ 1595 VirtualKeyActivationRequest "0b00";
BA_ "Event" SG_ 1596 NextTurnProximityDetected "true";
BA_ "Event" SG_ 1596 NextTurnProximityDetected "true";
BA_ "Event" SG_ 1596 NextTurnProximityDetected "true";
BA_ "Event" SG_ 1596 NextTurnProximityDetected "true";
BA_ "Unavailable_Value" SG_ 1596 NextTurnProximityDetected "0b0";
BA_ "Event" SG_ 1596 CurrentAudioState "true";
BA_ "Event" SG_ 1596 CurrentAudioState "true";
BA_ "Event" SG_ 1596 CurrentAudioState "true";
BA_ "Event" SG_ 1596 CurrentAudioState "true";
BA_ "Unavailable_Value" SG_ 1596 CurrentAudioState "0b00";
BA_ "Event" SG_ 1596 CompassPosition "true";
BA_ "Event" SG_ 1596 CompassPosition "true";
BA_ "Event" SG_ 1596 CompassPosition "true";
BA_ "Event" SG_ 1596 CompassPosition "true";
BA_ "Unavailable_Value" SG_ 1596 CompassPosition "0x1F";
BA_ "Event" SG_ 1596 CurrentRadioFavorite "true";
BA_ "Event" SG_ 1596 CurrentRadioFavorite "true";
BA_ "Event" SG_ 1596 CurrentRadioFavorite "true";
BA_ "Event" SG_ 1596 CurrentRadioFavorite "true";
BA_ "Unavailable_Value" SG_ 1596 CurrentRadioFavorite "0b0";
BA_ "Event" SG_ 1596 CurrentPhoneStatus "true";
BA_ "Event" SG_ 1596 CurrentPhoneStatus "true";
BA_ "Event" SG_ 1596 CurrentPhoneStatus "true";
BA_ "Event" SG_ 1596 CurrentPhoneStatus "true";
BA_ "Unavailable_Value" SG_ 1596 CurrentPhoneStatus "0b000";
BA_ "Event" SG_ 1596 CurrentAudioSource_v2 "true";
BA_ "Event" SG_ 1596 CurrentAudioSource_v2 "true";
BA_ "Event" SG_ 1596 CurrentAudioSource_v2 "true";
BA_ "Event" SG_ 1596 CurrentAudioSource_v2 "true";
BA_ "Unavailable_Value" SG_ 1596 CurrentAudioSource_v2 "0b0000";
BA_ "Event" SG_ 1596 CurrentRadioBand_v2 "true";
BA_ "Event" SG_ 1596 CurrentRadioBand_v2 "true";
BA_ "Event" SG_ 1596 CurrentRadioBand_v2 "true";
BA_ "Event" SG_ 1596 CurrentRadioBand_v2 "true";
BA_ "Event" SG_ 1596 AutoDimmingRequest "true";
BA_ "Event" SG_ 1596 AutoDimmingRequest "true";
BA_ "Event" SG_ 1596 AutoDimmingRequest "true";
BA_ "Event" SG_ 1596 AutoDimmingRequest "true";
BA_ "Unavailable_Value" SG_ 1596 AutoDimmingRequest "0b00";
BA_ "Event" SG_ 1596 IconNumberForNavigationDisplay "true";
BA_ "Event" SG_ 1596 IconNumberForNavigationDisplay "true";
BA_ "Event" SG_ 1596 IconNumberForNavigationDisplay "true";
BA_ "Event" SG_ 1596 IconNumberForNavigationDisplay "true";
BA_ "Unavailable_Value" SG_ 1596 IconNumberForNavigationDisplay "0xFF";
BA_ "Event" SG_ 1596 SC_DepartureTimeMinute "true";
BA_ "Event" SG_ 1596 SC_DepartureTimeMinute "true";
BA_ "Event" SG_ 1596 SC_DepartureTimeMinute "true";
BA_ "Event" SG_ 1596 SC_DepartureTimeMinute "true";
BA_ "Event" SG_ 1596 PnCactivationRequest_IVI "true";
BA_ "Event" SG_ 1596 PnCactivationRequest_IVI "true";
BA_ "Event" SG_ 1596 PnCactivationRequest_IVI "true";
BA_ "Event" SG_ 1596 PnCactivationRequest_IVI "true";
BA_ "Unavailable_Value" SG_ 1596 PnCactivationRequest_IVI "0b00";
BA_ "Event" SG_ 1596 TCS_DeactivationRequest2 "true";
BA_ "Event" SG_ 1596 TCS_DeactivationRequest2 "true";
BA_ "Event" SG_ 1596 TCS_DeactivationRequest2 "true";
BA_ "Event" SG_ 1596 TCS_DeactivationRequest2 "true";
BA_ "Event" SG_ 1596 HDC_ActivationRequest2 "true";
BA_ "Event" SG_ 1596 HDC_ActivationRequest2 "true";
BA_ "Event" SG_ 1596 HDC_ActivationRequest2 "true";
BA_ "Event" SG_ 1596 HDC_ActivationRequest2 "true";
BA_ "Unavailable_Value" SG_ 1596 HDC_ActivationRequest2 "0b11";
BA_ "Event" SG_ 1596 SC_DepartureTimeHour "true";
BA_ "Event" SG_ 1596 SC_DepartureTimeHour "true";
BA_ "Event" SG_ 1596 SC_DepartureTimeHour "true";
BA_ "Event" SG_ 1596 SC_DepartureTimeHour "true";
BA_ "Event" SG_ 1596 ClusterSkinRequest_v2 "true";
BA_ "Event" SG_ 1596 ClusterSkinRequest_v2 "true";
BA_ "Event" SG_ 1596 ClusterSkinRequest_v2 "true";
BA_ "Event" SG_ 1596 ClusterSkinRequest_v2 "true";
BA_ "Unavailable_Value" SG_ 1596 SC_DepartureTimeWeekDay "0b111";
BA_ "Event" SG_ 1599 CTA_ActivationState "true";
BA_ "Event" SG_ 1599 CTA_ActivationState "true";
BA_ "Event" SG_ 1599 CTA_ActivationState "true";
BA_ "Event" SG_ 1599 CTA_ActivationState "true";
BA_ "Unavailable_Value" SG_ 1599 CTA_ActivationState "0b0";
BA_ "Event" SG_ 1616 APA_WarningDisplayRequest2 "true";
BA_ "Event" SG_ 1616 APA_WarningDisplayRequest2 "true";
BA_ "Event" SG_ 1616 APA_WarningDisplayRequest2 "true";
BA_ "Event" SG_ 1616 APA_WarningDisplayRequest2 "true";
BA_ "Unavailable_Value" SG_ 1616 APA_WarningDisplayRequest2 "0x00";
BA_ "Event" SG_ 1616 APA_ScanInfo2 "true";
BA_ "Event" SG_ 1616 APA_ScanInfo2 "true";
BA_ "Event" SG_ 1616 APA_ScanInfo2 "true";
BA_ "Event" SG_ 1616 APA_ScanInfo2 "true";
BA_ "Unavailable_Value" SG_ 1616 APA_ScanInfo2 "0b000";
BA_ "Event" SG_ 1620 FreeDistanceZEVSinceECOreset "true";
BA_ "Event" SG_ 1620 FreeDistanceZEVSinceECOreset "true";
BA_ "Event" SG_ 1620 FreeDistanceZEVSinceECOreset "true";
BA_ "Event" SG_ 1620 FreeDistanceZEVSinceECOreset "true";
BA_ "Unavailable_Value" SG_ 1620 FreeDistanceZEVSinceECOreset "0x1FFF";
BA_ "Event" SG_ 1620 AverageConsumptionZEVLastECOtrip "true";
BA_ "Event" SG_ 1620 AverageConsumptionZEVLastECOtrip "true";
BA_ "Event" SG_ 1620 AverageConsumptionZEVLastECOtrip "true";
BA_ "Event" SG_ 1620 AverageConsumptionZEVLastECOtrip "true";
BA_ "Unavailable_Value" SG_ 1620 AverageConsumptionZEVLastECOtrip "0x3FF";
VAL_ 1477 ITM_FrontRightSeatRequest 7 "Ventilated High request" 6 "Ventilated Middle request" 5 "Ventilated Low request" 4 "Auto request" 3 "Heater High request" 2 "Heater Middle request" 1 "Heater Low request" 0 "OFF request";
VAL_ 1477 ITM_FrontLeftSeatRequest 7 "AUTO request" 6 "Ventilated High request" 5 "Ventilated Middle request" 4 "Ventilated Low request" 3 "Heater High request" 2 "Heater Middle request" 1 "Heater Low request" 0 "OFF request";
VAL_ 1477 ITM_SecondRowRightSeatRequest 7 "Ventilated High request" 6 "Ventilated Middle request" 5 "Ventilated Low request" 4 "Auto request" 3 "Heater High request" 2 "Heater Middle request" 1 "Heater Low request" 0 "OFF request";
VAL_ 1477 ITM_SecondRowLeftSeatRequest 7 "Ventilated High request" 6 "Ventilated Middle request" 5 "Ventilated Low request" 4 "Auto request" 3 "Heater High request" 2 "Heater Middle request" 1 "Heater Low request" 0 "OFF request";
VAL_ 1477 ITM_ThirdRowRightSeatRequest 7 "Ventilated High request" 6 "Ventilated Middle request" 5 "Ventilated Low request" 4 "Auto request" 3 "Heater High request" 2 "Heater Middle request" 1 "Heater Low request" 0 "OFF request";
VAL_ 1477 ITM_ThirdRowLeftSeatRequest 7 "Ventilated High request" 6 "Ventilated Middle request" 5 "Ventilated Low request" 4 "Auto request" 3 "Heater High request" 2 "Heater Middle request" 1 "Heater Low request" 0 "OFF request";
VAL_ 1478 SR_ContinuousRecordLengthRequest 7 "Reset request" 6 "Not used" 5 "Not used" 4 "Not used" 3 "5 minutes" 2 "3 minutes" 1 "1 minute" 0 "No request";
VAL_ 1478 SR_ShockSensitivityRequest 7 "Reset request" 6 "Not used" 5 "Not used" 4 "Not used" 3 "High" 2 "Mid" 1 "Low" 0 "No request";
VAL_ 1478 SR_DrivingInfoRecordRequest 3 "Reset request" 2 "Record request" 1 "No Record request" 0 "No request";
VAL_ 1478 SR_LocationInfoRecordRequest 3 "Reset request" 2 "Record request" 1 "No record request" 0 "No request";
VAL_ 1478 SR_SoundRecordRequest 3 "Reset request" 2 "Sound not recorded request" 1 "Sound recorded request" 0 "No request";
VAL_ 1478 SR_CustomerRecordLengthRequest 7 "Reset request" 6 "Not used" 5 "Not used" 4 "Not used" 3 "5 minutes" 2 "3 minutes" 1 "1 minute" 0 "No request";
VAL_ 1479 ContinuousModeRequest 3 "Not Used" 2 "Disable request" 1 "Enable request" 0 "No request";
VAL_ 1479 MC_TutorialRequest_V2 3 "Not Used" 2 "Tuto well done" 1 "On going" 0 "No Request";
VAL_ 1479 RestrictionModeRequest 3 "Not Used" 2 "Disable request" 1 "Enable request" 0 "No request";
VAL_ 1479 ParkingModeRequest 3 "Not Used" 2 "Disable request" 1 "Enable request" 0 "No request";
VAL_ 1482 TSR_OSPActivationRequest2 3 "Reset Requested" 2 "TSR/OSP OFF request" 1 "TSR/OSP ON request" 0 "No request";
VAL_ 1482 LDW_ActivationRequest2 3 "Reset request" 2 "LDW de-activation request" 1 "LDW activation request" 0 "No request";
VAL_ 1482 LDW_VibrationIntensityReq2 7 "Reset request" 6 "Not used" 5 "Not used" 4 "Not used" 3 "High intensity request" 2 "Middle intensity request" 1 "Low intensity request" 0 "No request";
VAL_ 1482 SailingStopActivationRequest2 3 "Reset request" 2 "Sailing stop not requested" 1 "Sailing stop requested" 0 "No Request";
VAL_ 1482 AEB_FCWactivationRequest2 7 "Reset request" 6 "Not used" 5 "Not used" 4 "AEB ON / FCW ON" 3 "AEB ON / FCW OFF" 2 "AEB OFF / FCW ON" 1 "AEB OFF / FCW OFF" 0 "No request";
VAL_ 1482 LDW_SensibilityRequest2 7 "Reset request" 6 "Not Used" 5 "Not Used" 4 "Not Used" 3 "High sensibility request" 2 "Middle sensibility request" 1 "Low sensibility request" 0 "No request";
VAL_ 1482 FKP_ActivationRequest2 3 "Reset Request" 2 "Flank Protection Requested" 1 "Flank Protection NOT requested" 0 "No Request";
VAL_ 1482 MOD_ActivationRequest2 3 "Reset request" 2 "Deactivation request" 1 "Activation request" 0 "No request";
VAL_ 1482 SonarAutoDisplayRequest2 3 "Reset request" 2 "Auto Display Deactivated" 1 "Auto Display Activated" 0 "No request";
VAL_ 1482 DW_ActivationRequest2 3 "Reset request" 2 "DW Deactivation request" 1 "DW Activation request" 0 "No request";
VAL_ 1482 BSWrad_ActivationRequest2 3 "Reset request" 2 "Deactivation" 1 "Activation" 0 "No request";
VAL_ 1482 HFP_DefaultManeuverTypeRequest2 7 "Reset Request" 6 "Not used" 5 "Not used" 4 "park out" 3 "park in / angled" 2 "park in / perpendicular" 1 "park in / parallel" 0 "no request";
VAL_ 1482 HandDrivingActivationRequest2 3 "Reset request" 2 "Left Hand Driving requested" 1 "Right Hand Driving requested" 0 "No request";
VAL_ 1482 LKA_ActivationRequest2 3 "Reset request" 2 "Deactivation" 1 "Activation" 0 "No request";
VAL_ 1482 SailingIdleActivationReq2 3 "Reset request" 2 "Sailing idle deactivation Requested" 1 "Sailing idle activation Requested" 0 "No request";
VAL_ 1482 CTA_ActivationRequest2 3 "Reset request" 2 "Deactivation" 1 "Activation" 0 "No request";
VAL_ 1482 AFS_ActivationRequest2 3 "Reset request" 2 "Deactivation" 1 "Activation" 0 "No request";
VAL_ 1482 LCA_ActivationRequest2 3 "Reset request" 2 "Deactivation" 1 "Activation" 0 "No request";
VAL_ 1488 OffsetActivation_State 3 "Unavailable" 2 "Not used" 1 "Activated" 0 "Deactivated";
VAL_ 1488 OffsetValue_State 31 "Not used" 30 "Not used" 29 "Not used" 28 "Not used" 27 "Not used" 26 "Not used" 25 "Not used" 24 "Not used" 23 "Not used" 22 "Not used" 21 "10" 20 "9" 19 "8" 18 "7" 17 "6" 16 "5" 15 "4" 14 "3" 13 "2" 12 "1" 11 "0" 10 "-1" 9 "-2" 8 "-3" 7 "-4" 6 "-5" 5 "-6" 4 "-7" 3 "-8" 2 "-9" 1 "-10" 0 "Unavailable";
VAL_ 1490 HUD_RotationPositionState 31 "Not used" 30 "Not used" 29 "Not used" 28 "Not used" 27 "Not used" 26 "Not used" 25 "Not used" 24 "Not used" 23 "Not used" 22 "Not used" 21 "Not used" 20 "Step 21" 19 "Step 20" 18 "Step 19" 17 "Step 18" 16 "Step 17" 15 "Step 16" 14 "Step 15" 13 "Step 14" 12 "Step 13" 11 "Step 12" 10 "Step 11" 9 "Step 10" 8 "Step 9" 7 "Step 8" 6 "Step 7" 5 "Step 6" 4 "Step 5" 3 "Step 4" 2 "Step 3" 1 "Step 2" 0 "Step 1";
VAL_ 1490 HUD_FOTA_status 31 "invalid" 30 "Not used" 29 "Not used" 28 "Not used" 27 "Not used" 26 "Not used" 25 "Not used" 24 "Not used" 23 "Not used" 22 "Not used" 21 "Slave Installation complete" 20 "Slave Copying in progress" 19 "Slave Installation in progress" 18 "Slave Distribution complete" 17 "Slave Integrity check in progress" 16 "Slave Distribution in progress" 15 "Ready for Slave Distribution" 14 "Rollback complete" 13 "Rollback in progress" 12 "Update Error detected" 11 "Error detected" 10 "Cancel in progress" 9 "Activation complete" 8 "Configuration install in progress" 7 "Component version check in progress" 6 "Reboot in progress" 5 "Switch in progress" 4 "Ready for activation" 3 "Vehicle Condition check in progress" 2 "Copying in progress" 1 "Installation in progress" 0 "Idle";
VAL_ 1491 ParkAssistVolumeRequest 7 "Reset request" 6 "Level 5" 5 "Level 4" 4 "Level 3" 3 "Level 2" 2 "Level 1" 1 "Level 0 (off)" 0 "No request ";
VAL_ 1492 PnCcertificateInstallationStatus 15 "Unavailable value" 14 "Not used" 13 "Not used" 12 "Not used" 11 "Not used" 10 "Not used" 9 "Not used" 8 "Contract errors" 7 "Contract expired" 6 "Contract will soon expire" 5 "Installation in progress" 4 "OEM provisioning Certif Error" 3 "Contract will be installed" 2 "Contract certificate installed" 1 "Contract certificate not installed" 0 "No display";
VAL_ 1496 WCBS_Memory_Fault 3 "Not Used" 2 "Memory Fault" 1 "No memory Fault" 0 "Unavailable";
VAL_ 1496 WCBS_Coil_Disconnection 3 "Not Used" 2 "Coil disconnection" 1 "No coil disconnection" 0 "Unavailable";
VAL_ 1496 WCBS_ChargingStopReason 31 "Not used" 30 "Not used" 29 "Not used" 28 "Not used" 27 "Not used" 26 "Not used" 25 "Not used" 24 "Not used" 23 "Not used" 22 "Not used" 21 "Not used" 20 "TX_OVER_COILCURR_LIMIT" 19 "TX_INPWREXCEED" 18 "TX_OVER_INCURR_LIMIT" 17 "TX_FOD_ERROR" 16 "TX_RCVPWR_TIMEOUT" 15 "TX_OVER_TEMP_FAULT" 14 "TX_QFOD_ERROR" 13 "TX_INCOMPATIBLE_PWR" 12 "TX_ANALOGPING_FAULT" 11 "TX_COILSELEQFAULTCOIL" 10 "RX_NEG_FAILURE" 9 "RX_RESTART_PWR_XFER" 8 "RX_NO_RESPONSE" 7 "RX_BATTERY_FAILURE" 6 "RX_OVER_CURRENT" 5 "RX_OVER_TEMP" 4 "RX_OVER_VOLT" 3 "RX_INTERNAL_FAULT" 2 "RX_CHARGE_COMPLETE" 1 "RX_UNKNOWN" 0 "Unavailable";
VAL_ 1496 Smartphone_Manufacturer 7 "Not Used" 6 "Others" 5 "Apple" 4 "Motorola" 3 "Nokia" 2 "LGE" 1 "Samsung" 0 "Unavailable";
VAL_ 1496 Smartphone_Charging_Standard 7 "Not Used" 6 "A4WP" 5 "PMA" 4 "WPC x.x" 3 "WPC 1.2" 2 "WPC 1.1" 1 "WPC 1.0" 0 "Unavailable";
VAL_ 1496 InductiveChargerStatus 3 "Uncharging" 2 "Charging" 1 "Object detecting" 0 "Unavailable";
VAL_ 1496 WCBS_HMI 7 "Full charged pictogram" 6 "not used" 5 "No HMI" 4 "Charging on pictogram" 3 "not used" 2 "Foreign Object Detected pop-up" 1 "High temperature pop-up" 0 "Unavailable";
VAL_ 1498 AD_DistanceDuration 1023 "Unavailable Value" 0 "No Display";
VAL_ 1498 AD_TimeDuration 0 "No Display";
VAL_ 1503 PassengerBackBolsterDisplayReq 3 "Not monitored" 2 "Backrest bolster decrease Display Request" 1 "Backrest bolster increase Display Request" 0 "No display request";
VAL_ 1503 PassengerSeatMemoState 7 "Not used" 6 "Seat in No Position memorized" 5 "Seat Position 6" 4 "Seat Position 5" 3 "Seat Position 4" 2 "Seat Position 3" 1 "Seat Position 2" 0 "Seat Position 1";
VAL_ 1503 PassengerSwitchMassageRequest 1 "Massage Request" 0 "No massage request";
VAL_ 1503 PsgerCushionBolsterDisplayReq 3 "Not monitored" 2 "Cushion bolster decrease Display Request" 1 "Cushion bolster increase Display Request" 0 "No display request";
VAL_ 1503 PsLumbarDisplayRequest_Z_Axis 3 "Not monitored" 2 "Z Axis Downward" 1 "Z Axis Upward" 0 "No display request";
VAL_ 1503 PsLumbarDisplayRequest_X_Axis 3 "Not monitored" 2 "X Axis Backward" 1 "X Axis Frontward" 0 "No display request";
VAL_ 1505 AQMIoniserModeSelectionReq 3 "Relax" 2 "Clean" 1 "Off" 0 "No request";
VAL_ 1505 ClimFPBlowerRequest 15 "Blower OFF" 14 "Level 14" 13 "Level 13" 12 "Level 12" 11 "Level 11" 10 "Level 10" 9 "Level 9" 8 "Level 8" 7 "Level 7" 6 "Level 6" 5 "Level 5" 4 "Level 4" 3 "Level 3" 2 "Level 2" 1 "Level 1" 0 "No Request";
VAL_ 1505 BlowerReductionRequest 1 "Blower Speed Reduction Requested" 0 "Blower Speed Reduction not Requested";
VAL_ 1505 AirFreshenerRequest 3 "Not Used" 2 "Air Freshener OFF requested" 1 "Air Freshener ON requested" 0 "No request";
VAL_ 1506 SSU_Movement 3 "Anti Pinch" 2 "Closing / Tilt Down" 1 "Opening / Tilt Up" 0 "Stopped";
VAL_ 1506 SRU_Movement 3 "Anti Pinch" 2 "Closing / Tilt Down" 1 "Opening / Tilt Up" 0 "Stopped";
VAL_ 1506 MM_GeneralAuthWindowsLift 15 "Reserved" 14 "Reserved" 13 "Reserved" 12 "Reserved" 11 "Reserved" 10 "Reserved" 9 "Reserved" 8 "Reserved" 7 "Reserved" 6 "Reserved" 5 "Reserved" 4 "Reserved" 3 "Reserved" 2 "Action permanantly not possible" 1 "Action temporary not possible" 0 "Action possible";
VAL_ 1506 WindowPositionExtended_FR 31 "Reserved" 30 "Reserved" 29 "Reserved" 28 "Reserved" 27 "Reserved" 26 "Reserved" 25 "Reserved" 24 "Reserved" 23 "Reserved" 22 "Reserved" 21 "Fully Open 100%" 20 "Position 95%" 19 "Position 90%" 18 "Position 85%" 17 "Position 80%" 16 "Position 75%" 15 "Position 70%" 14 "Position 65%" 13 "Position 60%" 12 "Position 55%" 11 "Position 50%" 10 "Position 45%" 9 "Position 40%" 8 "Position 35%" 7 "Position 30%" 6 "Position 25%" 5 "Position 20%" 4 "Position 15%" 3 "Position 10%" 2 "Position 5%" 1 "Fully Close 0%" 0 "Position invalid";
VAL_ 1506 WindowPositionExtended_FL 31 "Reserved" 30 "Reserved" 29 "Reserved" 28 "Reserved" 27 "Reserved" 26 "Reserved" 25 "Reserved" 24 "Reserved" 23 "Reserved" 22 "Reserved" 21 "Fully Open 100%" 20 "Position 95%" 19 "Position 90%" 18 "Position 85%" 17 "Position 80%" 16 "Position 75%" 15 "Position 70%" 14 "Position 65%" 13 "Position 60%" 12 "Position 55%" 11 "Position 50%" 10 "Position 45%" 9 "Position 40%" 8 "Position 35%" 7 "Position 30%" 6 "Position 25%" 5 "Position 20%" 4 "Position 15%" 3 "Position 10%" 2 "Position 5%" 1 "Fully Close 0%" 0 "Position invalid";
VAL_ 1506 WindowPositionExtended_RR 31 "Not used" 30 "Not used" 29 "Not used" 28 "Not used" 27 "Not used" 26 "Not used" 25 "Not used" 24 "Not used" 23 "Not used" 22 "Not used" 21 "Position 100%" 20 "Position 95%" 19 "Position 90%" 18 "Position 85%" 17 "Position 80%" 16 "Position 75%" 15 "Position 70%" 14 "Position 65%" 13 "Position 60%" 12 "Position 55%" 11 "Position 50%" 10 "Position 45%" 9 "Position 40%" 8 "Position 35%" 7 "Position 30%" 6 "Position 25%" 5 "Position 20%" 4 "Position 15%" 3 "Position 10%" 2 "Position 05%" 1 "Fully Close 0%" 0 "Position invalid";
VAL_ 1506 WindowPositionExtended_RL 31 "Reserved" 30 "Reserved" 29 "Reserved" 28 "Reserved" 27 "Reserved" 26 "Reserved" 25 "Reserved" 24 "Reserved" 23 "Reserved" 22 "Reserved" 21 "Fully Open 100%" 20 "Position 95%" 19 "Position 90%" 18 "Position 85%" 17 "Position 80%" 16 "Position 75%" 15 "Position 70%" 14 "Position 65%" 13 "Position 60%" 12 "Position 55%" 11 "Position 50%" 10 "Position 45%" 9 "Position 40%" 8 "Position 35%" 7 "Position 30%" 6 "Position 25%" 5 "Position 20%" 4 "Position 15%" 3 "Position 10%" 2 "Position 5%" 1 "Fully Close 0%" 0 "Position invalid";
VAL_ 1506 SSU_Position 15 "SunShade synchro 6(Shade mechanical open end)" 14 "SunShade synchro 5(Shade full Open software open end)" 13 "SunShade synchro 4(Shade 91.6%_100.0% Open)" 12 "SunShade synchro 3(Shade 83.4%_91.6% Open)" 11 "SunShade synchro 2(Shade 75.0%_83.4% Open)" 10 "SunShade synchro 1(Shade 66.7%_75.0% Open)" 9 "SunShade position 4(Shade 58.4%_66.7% Open)" 8 "SunShade sector 34(Shade 50%_58.4% Open)" 7 "SunShade position 3(Shade 41.6%_50% Open)" 6 "SunShade sector 23(Shade 33.4%_41.6% Open)" 5 "SunShade position 2(Shade 25.0%_33.4% Open)" 4 "SunShade sector 12(Shade 16.7%_25% Open)" 3 "SunShade position 1(Shade 8.4%_16.7% Open)" 2 "SunShade sector 01(Shade 0%_8.4% Open)" 1 "SunShade position 0 (closed)(Shade Full Close)" 0 "SunShade position invalid";
VAL_ 1508 RESPreSoak_ProgStatus 3 "Not used" 2 "Every two hours (5 times max)" 1 "1 time only (RES or Presoak)" 0 "No programmed";
VAL_ 1508 RES_ProgrammationForbidden 1 "Programmation forbidden" 0 "Programmation authorized";
VAL_ 1510 FixedMaintenanceRange 255 "Fixed maintenance requested (time over)" 254 "Fixed maintenance requested within one month";
VAL_ 1510 AlertMinBeforeOverhaul 3 "Overhaul Alert" 2 "Distance Prealert" 1 "Time Prealert" 0 "No Alert ";
VAL_ 1510 ClusterSkinState_v2 15 "Not used" 14 "Not used" 13 "Not used" 12 "Not used" 11 "Not used" 10 "Skin11" 9 "Skin10" 8 "Skin9" 7 "Skin8" 6 "Skin7" 5 "Skin6" 4 "Skin5" 3 "Skin4" 2 "Skin3" 1 "Skin2" 0 "Skin1";
VAL_ 1511 WheelStateRL 7 "Puncture and underinflation and failure" 6 "Puncture and underinflation" 5 "Puncture and failure" 4 "Puncture" 3 "Underinflation and failure" 2 "Underinflation" 1 "Failure" 0 "Pressure ok and no failure";
VAL_ 1511 WheelStateRR 7 "Puncture and underinflation and failure" 6 "Puncture and underinflation" 5 "Puncture and failure" 4 "Puncture" 3 "Underinflation and failure" 2 "Underinflation" 1 "Failure" 0 "Pressure ok and no failure";
VAL_ 1511 TPMS_AckResetDriver 3 "Not Used" 2 "Reset driver taken into account" 1 "Reset driver NOT  taken into account" 0 "Unvailable Value";
VAL_ 1511 WheelStateFL 7 "Puncture and underinflation and failure" 6 "Puncture and underinflation" 5 "Puncture and failure" 4 "Puncture" 3 "Underinflation and failure" 2 "Underinflation" 1 "Failure" 0 "Pressure ok and no failure";
VAL_ 1511 WheelStateFR 7 "Puncture and underinflation and failure" 6 "Puncture and underinflation" 5 "Puncture and failure" 4 "Puncture" 3 "Underinflation and failure" 2 "Underinflation" 1 "Failure" 0 "Pressure ok and no failure";
VAL_ 1511 OldPressureFL 1 "Pressure not up to date" 0 "Pressure up to date";
VAL_ 1511 OldPressureFR 1 "Pressure not up to date" 0 "Pressure up to date";
VAL_ 1511 OldPressureRL 1 "Pressure not up to date" 0 "Pressure up to date";
VAL_ 1511 OldPressureRR 1 "Pressure not up to date" 0 "Pressure up to date";
VAL_ 1511 TPMS_AutoLocStatus 3 "autolocation not OK" 2 "Autolocation finished OK" 1 "Autolocation is active" 0 "init phase - or autolocation not avaliable (not present)";
VAL_ 1516 LDW_SoundLevelRequest_v2 7 "Reset request" 6 "Level 5" 5 "Level 4" 4 "Level 3" 3 "Level 2" 2 "Level 1" 1 "Not used" 0 "No request";
VAL_ 1519 UserSettingCopySource 7 "Not used" 6 "User5" 5 "User4" 4 "User3" 3 "User2" 2 "User1" 1 "Guest" 0 "Not copy";
VAL_ 1519 UserSettingCopyTarget 7 "Not used" 6 "User5" 5 "User4" 4 "User3" 3 "User2" 2 "User1" 1 "Guest" 0 "Not copy";
VAL_ 1519 User5_RegistrationState 1 "Registered" 0 "Not Registered";
VAL_ 1519 User4_RegistrationState 1 "Registered" 0 "Not Registered";
VAL_ 1519 KeyLinkInitializationState 1 "Initialization completed" 0 "Initialization in progress";
VAL_ 1519 KeyLinkActivationState 1 "Deactivate" 0 "Activate";
VAL_ 1519 User3_RegistrationState 1 "Registered" 0 "Not Registered";
VAL_ 1519 User2_RegistrationState 1 "Registered" 0 "Not Registered";
VAL_ 1519 User1_RegistrationState 1 "Registered" 0 "Not Registered";
VAL_ 1519 UserSettingCopyRequest 1 "Request" 0 "No request";
VAL_ 1519 ADA1ActivationRequest2 3 "Reset request" 2 "Deactivation" 1 "Activation" 0 "No request";
VAL_ 1519 ASAactivationRequest2 3 "Reset request" 2 "Deactivation" 1 "Activation" 0 "No request";
VAL_ 1519 CurrentUserState_v2 7 "Unavailable" 6 "Not used" 5 "User5" 4 "User4" 3 "User3" 2 "User2" 1 "User1" 0 "Guest";
VAL_ 1519 SuspensionSettingRequest2 7 "Reset request" 6 "Mode VADA 6 (Race)" 5 "Mode VADA 5" 4 "Mode VADA 4" 3 "Mode VADA 3 (Sport)" 2 "Mode VADA 2 (Comfort)" 1 "Mode VADA 1 (Normal)" 0 "No request";
VAL_ 1519 SteeringSettingRequest2_v2 15 "Reset request" 14 "According to DriveMode" 13 "Mode EPS 13" 12 "Mode EPS 12" 11 "Mode EPS 11 Quick / Sport" 10 "Mode EPS 10 Quick / Confort" 9 "Mode EPS 9 Quick / Normal" 8 "Mode EPS 8" 7 "Mode EPS 7 Casual / Sport" 6 "Mode EPS 6 Casual / Confort" 5 "Mode EPS 5 Casual / Normal" 4 "Mode EPS 4" 3 "Mode EPS 3 Normal / Sport" 2 "Mode EPS 2 Normal / Confort" 1 "Mode EPS 1 Normal / Normal" 0 "No request";
VAL_ 1519 MC_PositionChangeRequest 15 "Reset Request" 14 "Recall MC position 14" 13 "Recall MC position 13" 12 "Recall MC position 12" 11 "Recall MC position 11" 10 "Recall MC position 10" 9 "Recall MC position 9" 8 "Recall MC position 8" 7 "Recall MC position 7" 6 "Recall MC position 6" 5 "Recall MC position 5" 4 "Recall MC position 4" 3 "Recall MC position 3" 2 "Recall MC position 2" 1 "Recall MC position 1" 0 "No request";
VAL_ 1519 PowerTrainSettingRequest2 15 "Reset request" 14 "Mode14" 13 "Mode13" 12 "Mode12" 11 "Mode11" 10 "Mode10" 9 "Mode9" 8 "Mode8" 7 "Mode7" 6 "Mode6" 5 "Mode5" 4 "Mode4 (Snow)" 3 "Mode3 (Eco)" 2 "Mode2 (Sport)" 1 "Mode1 (Standard)" 0 "No request";
VAL_ 1519 ClimAQSSensitivityRequest 7 "Reset request" 6 "OFF request" 5 "Level 5" 4 "Level 4" 3 "Level 3" 2 "Level 2" 1 "Level 1" 0 "No request";
VAL_ 1519 UserProfileResetRequest 7 "Not used" 6 "Reset Guest" 5 "Reset Profile 5" 4 "Reset Profile 4" 3 "Reset Profile 3" 2 "Reset Profile 2" 1 "Reset Profile 1" 0 "No Request";
VAL_ 1519 MC_ActivationRequest 3 "Not used" 2 "Magic Cockpit OFF request" 1 "Magic Cockpit ON request" 0 "No request";
VAL_ 1519 MC_PositionRecallRequest 15 "Reset Request" 14 "Recall MC position 14" 13 "Recall MC position 13" 12 "Recall MC position 12" 11 "Recall MC position 11" 10 "Recall MC position 10" 9 "Recall MC position 9" 8 "Recall MC position 8" 7 "Recall MC position 7" 6 "Recall MC position 6" 5 "Recall MC position 5" 4 "Recall MC position 4" 3 "Recall MC position 3" 2 "Recall MC position 2" 1 "Recall MC position 1" 0 "No request";
VAL_ 1519 VMCSettingRequest 15 "Reset request" 14 "Mode14" 13 "Mode13" 12 "Mode12" 11 "Mode11" 10 "Mode10" 9 "Mode9" 8 "Mode8" 7 "Mode7" 6 "Mode6" 5 "Mode5" 4 "Mode4" 3 "Mode3" 2 "Mode2" 1 "Mode1" 0 "No request";
VAL_ 1519 MC_PositionCalculate 15 "Calculate MC all positions" 14 "Calculate position 14" 13 "Calculate position 13" 12 "Calculate position 12" 11 "Calculate position 11" 10 "Calculate position 10" 9 "Calculate position 9" 8 "Calculate position 8" 7 "Calculate position 7" 6 "Calculate position 6" 5 "Calculate position 5" 4 "Calculate position 4" 3 "Calculate position 3" 2 "Calculate position 2" 1 "Calculate position 1" 0 "No Request (default value)";
VAL_ 1519 MC_PositionSaveRequest 15 "Unavailable" 14 "Save MC position 14" 13 "Save MC position 13" 12 "Save MC position 12" 11 "Save MC position 11" 10 "Save MC position 10" 9 "Save MC position 9" 8 "Save MC position 8" 7 "Save MC position 7" 6 "Save MC position 6" 5 "Save MC position 5" 4 "Save MC position 4" 3 "Save MC position 3" 2 "Save MC position 2" 1 "Save MC position 1" 0 "No request";
VAL_ 1523 HVchargeDisplayState 1 "Meter HMI during charge activated" 0 "Meter HMI during charge desactivated";
VAL_ 1529 HUD_AutoDimmingRequest2 3 "Reset request" 2 "AutoDimming Deactivation Request" 1 "AutoDimming Activation Request" 0 "No request";
VAL_ 1529 HUD_ActivationRequest2 3 "Reset request" 2 "Deployment Deactivation request" 1 "Deployment Activation request" 0 "No request";
VAL_ 1529 BSWson_ActivationRequest2 3 "Reset request" 2 "Deactivation request" 1 "Activation request" 0 "No request";
VAL_ 1529 BCI_ActivationRequest2 3 "Reset request" 2 "Deactivation" 1 "Activation" 0 "No request";
VAL_ 1529 ELKA_ActivationRequest2 3 "Reset request" 2 "Deactivation" 1 "Activation" 0 "No request";
VAL_ 1529 HUD_PositionRequest2 31 "Reset request" 30 "Not used" 29 "Not used" 28 "Not used" 27 "Not used" 26 "Not used" 25 "Not used" 24 "Not used" 23 "Not used" 22 "Not used" 21 "Step 21" 20 "Step 20" 19 "Step 19" 18 "Step 18" 17 "Step 17" 16 "Step 16" 15 "Step 15" 14 "Step 14" 13 "Step 13" 12 "Step 12" 11 "Step 11" 10 "Step 10" 9 "Step 9" 8 "Step 8" 7 "Step 7" 6 "Step 6" 5 "Step 5" 4 "Step 4" 3 "Step 3" 2 "Step 2" 1 "Step 1" 0 "No request";
VAL_ 1529 FCW_SensibilityRequest2 7 "Not used" 6 "Not used" 5 "Not used" 4 "ResetRequest" 3 "Late" 2 "Standard" 1 "Early" 0 "No Request";
VAL_ 1529 HUD_DayLuminosityRequest2 31 "Reset request" 30 "Not used" 29 "Not used" 28 "Not used" 27 "Not used" 26 "Not used" 25 "Not used" 24 "Not used" 23 "Not used" 22 "Not used" 21 "Step 21" 20 "Step 20" 19 "Step 19" 18 "Step 18" 17 "Step 17" 16 "Step 16" 15 "Step 15" 14 "Step 14" 13 "Step 13" 12 "Step 12" 11 "Step 11" 10 "Step 10" 9 "Step 9" 8 "Step 8" 7 "Step 7" 6 "Step 6" 5 "Step 5" 4 "Step 4" 3 "Step 3" 2 "Step 2" 1 "Step 1" 0 "No Request";
VAL_ 1529 HUD_NightLuminosityRequest2 31 "Reset request" 30 "Not used" 29 "Not used" 28 "Not used" 27 "Not used" 26 "Not used" 25 "Not used" 24 "Not used" 23 "Not used" 22 "Not used" 21 "Step 21" 20 "Step 20" 19 "Step 19" 18 "Step 18" 17 "Step 17" 16 "Step 16" 15 "Step 15" 14 "Step 14" 13 "Step 13" 12 "Step 12" 11 "Step 11" 10 "Step 10" 9 "Step 9" 8 "Step 8" 7 "Step 7" 6 "Step 6" 5 "Step 5" 4 "Step 4" 3 "Step 3" 2 "Step 2" 1 "Step 1" 0 "No Request";
VAL_ 1529 WAL_ActivationRequest2 3 "WAL factory setting reset request" 2 "WAL deactivation request" 1 "WAL activation request" 0 "No request";
VAL_ 1529 APPRUN_ActivationRequest2 3 "Approach Unlock Factory setting reset request" 2 "Approach Unlock Desactivation request" 1 "Approach Unlock Activation request" 0 "No Request";
VAL_ 1531 AutoFrontWiperActivationRequest2 3 "Automatic Front wiper Reset requested" 2 "Automatic Front wiper de-activation requested" 1 "Automatic Front wiper activation requested" 0 "No automatic front wiper activation deactivation request";
VAL_ 1531 AHL_ActivationRequest2 3 "Reset Request" 2 "Automatic High Low beam de-activation requested" 1 "Automatic High Low beam activation requested" 0 "No Request";
VAL_ 1531 ParkAssistVolumeRequest2 7 "Reset request" 6 "Level 5" 5 "Level 4" 4 "Level 3" 3 "Level 2" 2 "Level 1" 1 "Level 0 (off)" 0 "No request ";
VAL_ 1531 IKeyAccessActivationRequest2 3 "Reset Request" 2 "iKey Access Desactivation request" 1 "iKey Access Activation request" 0 "No Request";
VAL_ 1531 FrontRearWiperDropRequest2 3 "Drop wiper reset requested" 2 "Drop wiper de-activation requested" 1 "Drop wiper activation requested" 0 "No drop wiper activation de-activation request";
VAL_ 1531 FrontParkAssistActivationReq2 3 "Reset Request" 2 "Front parking assistance de-activation requested" 1 "Front parking assistance activation requested" 0 "No request";
VAL_ 1531 AutoRearWiperActivationRequest2 3 "Reset request" 2 "Automatic Rear wiper de-activation requested" 1 "Automatic Rear wiper activation requested" 0 "No automatic rear wiper activation de-activation request";
VAL_ 1531 WGSactivationRequest2 3 "Reset request" 2 "Deactivation" 1 "Activation" 0 "No request";
VAL_ 1531 SingleDoorOpeningActivationReq2 3 "Reset Request" 2 "Single door opening de-activation requested" 1 "Single door opening activation requested" 0 "No single door opening request";
VAL_ 1531 RearParkAssistActivationReq2 3 "Reset Request" 2 "Rear parking assistance de-activation requested" 1 "Rear parking assistance activation requested" 0 "No request";
VAL_ 1531 AutoLightSensitivityRequest2 7 "Reset request" 6 "Not used" 5 "Not used" 4 "Configuration 4" 3 "Configuration 3" 2 "Configuration 2" 1 "Configuration 1" 0 "No request";
VAL_ 1531 AutoReLockActivationReq2 3 "Reset Value Request" 2 "Auto ReLock OFF request" 1 "Auto ReLock ON request" 0 "No Request";
VAL_ 1531 MotorwayFlashersNumberRequest2 7 "Reset request" 6 "Not used" 5 "Not used" 4 "Not used" 3 "5 flash per CSW mode request" 2 "3 flash per CSW mode request" 1 "1 flash per CSW mode request" 0 "No request";
VAL_ 1531 AutoFMHactivationRequest2 3 "Reset request" 2 "Deactivation" 1 "Activation" 0 "No request";
VAL_ 1531 SilentModeActivationRequest2 3 "Reset Request" 2 "Silent Mode Deactivation Request " 1 "Silent mode Activation Request " 0 "No Request ";
VAL_ 1531 AutoLockActivationReq2 7 "Reset Request" 6 "Not used" 5 "Not used" 4 "Not used" 3 "No Auto Lock" 2 "Auto Lock with Park-out Activation request" 1 "Auto Lock with Speed Activation request" 0 "No request";
VAL_ 1531 AutoUnLockActivationReq2 7 "Reset Request" 6 "Not used" 5 "Not used" 4 "Not used" 3 "No Auto UnLock" 2 "Auto UnLock with Park request" 1 "Auto UnLock with IGN OFF request" 0 "No Request";
VAL_ 1531 WAC_APRUN_ActivationRequest2 3 "Reset Request" 2 "WAC and APRUN Deactivation Request" 1 "WAC and APRUN Activation Request " 0 "No Request ";
VAL_ 1531 ParkAssistSensitivityRequest2 7 "Reset Request" 6 "Not used" 5 "Not used " 4 "Not used" 3 "Near Range Detection" 2 "Middle Range Detection" 1 "Far Range Detection " 0 "No Request ";
VAL_ 1531 AutoFoldingActivationRequest2 7 "Reset request" 6 "Not used" 5 "Not used" 4 "Not used" 3 "Unlock + IGN Unfold" 2 "IGN Unfold" 1 "Disable" 0 "No request";
VAL_ 1531 PredictiveShiftActivationRequest2 3 "Reset request" 2 "Deactivation request" 1 "Activation request" 0 "No request";
VAL_ 1531 AirCondEcoActivationRequest2 3 "Reset request" 2 "Eco deactivation request" 1 "Eco activation request" 0 "No request";
VAL_ 1531 CruiseEcoActivationRequest2 3 "Reset request" 2 "De-activation (Normal) request" 1 "Activation (Eco) request" 0 "No request";
VAL_ 1531 AutoFMHdurationRequest2 15 "Reset request" 14 "Not used" 13 "Not used" 12 "Not used" 11 "Not used" 10 "Not used" 9 "Not used" 8 "Not used" 7 "180 sec" 6 "150 sec" 5 "120 sec" 4 "90 sec" 3 "60 sec" 2 "45 sec" 1 "30 sec" 0 "No request";
VAL_ 1531 AmbientLightingPatternRequest2 3 "Reset request" 2 "Deactivation" 1 "Activation" 0 "No request";
VAL_ 1531 ISS_EcoActivationRequest2 3 "Reset request" 2 "Eco deactivation request" 1 "Eco activation request" 0 "No request";
VAL_ 1537 ACC_TargetDistanceAlert 3 "ACC cancel warning" 2 "ACC collision warning" 1 "ACC approach warning" 0 "No ACC warning";
VAL_ 1537 LCA_ActivationState 1 "Deactivated" 0 "Activated";
VAL_ 1537 ADL3_DisclaimerAcknowledgement 1 "Acknowledgment" 0 "Not acknowledged";
VAL_ 1537 ContextSpeed_ActivationState 3 "Prompt mode activated" 2 "AutoMode ON" 1 "AutoMode OFF" 0 "Unavailable";
VAL_ 1537 ContextRoad_ActivationState 3 "Unavailable" 2 "Not Used" 1 "AutoMode ON" 0 "AutoMode OFF";
VAL_ 1538 BCI_FailureDisplay 3 "Not used" 2 "Permanent Failure Display" 1 "Temporary Failure Display" 0 "No display";
VAL_ 1538 LDW_AlertStatus 3 "Not used" 2 "Left alert" 1 "Right alert" 0 "No alert";
VAL_ 1538 EAP_AlertDisplay 1 "Alert display" 0 "No display";
VAL_ 1538 RAB_AlertStatus 3 "Not used" 2 "Alert 2" 1 "Alert 1" 0 "No alert";
VAL_ 1538 RAB_ActivationState 1 "Deactivated" 0 "Activated";
VAL_ 1538 WDA_ActivationState 1 "Deactivated" 0 "Activated";
VAL_ 1538 RAB_StatusDisplay 3 "Not used" 2 "Operational" 1 "Not operational" 0 "No display";
VAL_ 1538 RAB_FailureDisplay 3 "Not used" 2 "Permanent failure display" 1 "Temporary failure display" 0 "No display";
VAL_ 1540 SR_MemoryStorageStatus 1 "Memory card is full" 0 "Memory card not full";
VAL_ 1540 SDcardLockStatusDisplay 1 "SD card Locked" 0 "No display";
VAL_ 1540 RestrictionModeState 1 "Activated" 0 "Deactivated";
VAL_ 1540 ParkingModeState 1 "Activated" 0 "Deactivated";
VAL_ 1540 ContinuousModeState 1 "Activated" 0 "Deactivated";
VAL_ 1540 SR_UserEventPhotoStatusDisplay 3 "Impossible to make event photo during driving." 2 "Impossible to make event photo during event recording." 1 "User event photo" 0 "No display";
VAL_ 1540 SR_StoragePhotoStatusDisplay 1 "Memory card Photo is full" 0 "Memory card Photo not full";
VAL_ 1540 SR_ShockDetectedDisplay 1 "Shock Detected" 0 "No display";
VAL_ 1540 SR_RestrictionModeDisplay 1 "Restriction Mode Enabled" 0 "No display";
VAL_ 1540 SR_AutoRecExtendedStatusDisplay 1 "Automatic event recording extended" 0 "No display";
VAL_ 1543 SilentModeActivationState 1 "Silent mode is Activated" 0 "Silent mode is Desactivated";
VAL_ 1543 MirrorDownDisplayRequest 1 "Mirror down display request" 0 "No mirror down display request";
VAL_ 1543 MirrorUpDisplayRequest 1 "Mirror up display request" 0 "No mirror up display request";
VAL_ 1543 MirrorRightDisplayRequest 1 "Mirror right display request" 0 "No mirror right display request";
VAL_ 1543 MirrorLeftDisplayRequest 1 "Mirror left display request" 0 "No mirror left display request";
VAL_ 1543 MirrorSideSelectDisplayRequest 3 "Not Used" 2 "Right mirror selected" 1 "Left mirror selected" 0 "No mirror selected";
VAL_ 1543 AmbiLightColorStatus_v2 127 "Color 128" 126 "Color 127" 125 "Color 126" 124 "Color 125" 123 "Color 124" 122 "Color 123" 121 "Color 122" 120 "Color 121" 119 "Color 120" 118 "Color 119" 117 "Color 118" 116 "Color 117" 115 "Color 116" 114 "Color 115" 113 "Color 114" 112 "Color 113" 111 "Color 112" 110 "Color 111" 109 "Color 110" 108 "Color 109" 107 "Color 108" 106 "Color 107" 105 "Color 106" 104 "Color 105" 103 "Color 104" 102 "Color 103" 101 "Color 102" 100 "Color 101" 99 "Color 100" 98 "Color 99" 97 "Color 98" 96 "Color 97" 95 "Color 96" 94 "Color 95" 93 "Color 94" 92 "Color 93" 91 "Color 92" 90 "Color 91" 89 "Color 90" 88 "Color 89" 87 "Color 88" 86 "Color 87" 85 "Color 86" 84 "Color 85" 83 "Color 84" 82 "Color 83" 81 "Color 82" 80 "Color 81" 79 "Color 80" 78 "Color 79" 77 "Color 78" 76 "Color 77" 75 "Color 76" 74 "Color 75" 73 "Color 74" 72 "Color 73" 71 "Color 72" 70 "Color 71" 69 "Color 70" 68 "Color 69" 67 "Color 68" 66 "Color 67" 65 "Color 66" 64 "Color 65" 63 "Color 64" 62 "Color 63" 61 "Color 62" 60 "Color 61" 59 "Color 60" 58 "Color 59" 57 "Color 58" 56 "Color 57" 55 "Color 56" 54 "Color 55" 53 "Color 54" 52 "Color 53" 51 "Color 52" 50 "Color 51" 49 "Color 50" 48 "Color 49" 47 "Color 48" 46 "Color 47" 45 "Color 46" 44 "Color 45" 43 "Color 44" 42 "Color 43" 41 "Color 42" 40 "Color 41" 39 "Color 40" 38 "Color 39" 37 "Color 38" 36 "Color 37" 35 "Color 36" 34 "Color 35" 33 "Color 34" 32 "Color 33" 31 "Color 32" 30 "Color 31" 29 "Color 30" 28 "Color 29" 27 "Color 28" 26 "Color 27" 25 "Color 26" 24 "Color 25" 23 "Color 24" 22 "Color 23" 21 "Color 22" 20 "Color 21" 19 "Color 20" 18 "Color 19" 17 "Color 18" 16 "Color 17" 15 "Color 16" 14 "Color 15" 13 "Color 14" 12 "Color 13" 11 "Color 12" 10 "Color 11" 9 "Color 10" 8 "Color 9" 7 "Color 8" 6 "Color 7" 5 "Color 6" 4 "Color 5" 3 "Color 4" 2 "Color 3" 1 "Color 2" 0 "Color 1";
VAL_ 1543 VR_AuthCondition_RL 1 "Satisfied" 0 "Not satisfied";
VAL_ 1543 VR_AuthCondition_FR 1 "Satisfied" 0 "Not satisfied";
VAL_ 1543 VR_AuthCondition_FL 1 "Satisfied" 0 "Not satisfied";
VAL_ 1543 VR_AuthCondition_SSU 1 "Satisfied" 0 "Not satisfied";
VAL_ 1543 VR_AuthCondition_SRU 1 "Satisfied" 0 "Not satisfied";
VAL_ 1543 VR_AuthCondition_RR 1 "Satisfied" 0 "Not satisfied";
VAL_ 1549 DriverSwitchMassageRequest 1 "Massage Request" 0 "No massage request";
VAL_ 1549 MC_TutoControlsInhibitionReq 1 "Controls inhibition request" 0 "No request";
VAL_ 1549 MC_SeatAtSecureStopDisplayReq 7 "Not used" 6 "Not used" 5 "Not used" 4 "Not used" 3 "Seat at X secure stop Tuto will be reset to do it again" 2 "seat beyond secure stop Magic cockpit is now OFF" 1 "Seat at X secure stop" 0 "No display request";
VAL_ 1553 SecondRowCentralSeatStatus 7 "Ventilated High display" 6 "Ventilated Middle display" 5 "Ventilated Low display" 4 "Heater High display" 3 "Heater Middle display" 2 "Heater Low display" 1 "OFF display" 0 "Unavailable";
VAL_ 1553 ClimForcedFreshDisplayStatus 1 "Function available" 0 "Function not available";
VAL_ 1553 ClimForcedRecyDisplayStatus 1 "Function available" 0 "Function not available";
VAL_ 1553 ClimForcedFreshDisplay 3 "Not Used" 2 "Fresh OFF" 1 "Fresh ON" 0 "No display";
VAL_ 1553 ClimAQSSensitivityDisplay 7 "Not used" 6 "OFF" 5 "Level 5" 4 "Level 4" 3 "Level 3" 2 "Level 2" 1 "Level 1" 0 "No display";
VAL_ 1553 ClimExternalAirPollutionDisplay 7 "Not used" 6 "Not used" 5 "LEVEL 5" 4 "LEVEL 4" 3 "LEVEL 3" 2 "LEVEL 2" 1 "LEVEL 1" 0 "No display";
VAL_ 1553 ClimRearDefrostDisplayStatus 1 "Function available" 0 "Function not available";
VAL_ 1553 ClimExternAirPollutioDispStatus 1 "Function available" 0 "Function not available";
VAL_ 1553 ClimLinkPriorityFLSeatAutoDisp 7 "Not used" 6 "OFF" 5 "Level 5" 4 "Level 4" 3 "Level 3" 2 "Level 2" 1 "Level 1" 0 "No display";
VAL_ 1553 ClimLinkPriorityFRSeatAutoDisp 7 "Not used" 6 "OFF" 5 "Level 5" 4 "Level 4" 3 "Level 3" 2 "Level 2" 1 "Level 1" 0 "No display";
VAL_ 1553 FrontRightSeatDisplayStatus 1 "Function available" 0 "Function not available";
VAL_ 1553 FrontRightSeatStatus 7 "Ventilated High display" 6 "Ventilated Middle display" 5 "Ventilated Low display" 4 "Heater High display" 3 "Heater Middle display" 2 "Heater Low display" 1 "OFF display" 0 "Unavailable";
VAL_ 1553 FrontLeftSeatStatus 7 "Ventilated High display" 6 "Ventilated Middle display" 5 "Ventilated Low display" 4 "Heater High display" 3 "Heater Middle display" 2 "Heater Low display" 1 "OFF display" 0 "Unavailable";
VAL_ 1553 FrontLeftSeatDisplayStatus 1 "Function available" 0 "Function not available";
VAL_ 1553 SecondRowLeftSeatAutoDisplay 3 "Not used" 2 "Seat Auto OFF" 1 "Seat Auto ON" 0 "No display";
VAL_ 1553 SecondRowRightSeatAutoDisplay 3 "Not used" 2 "Seat Auto OFF" 1 "Seat Auto ON" 0 "No display";
VAL_ 1553 FrontLeftSeatAutoDisplay 3 "Not used" 2 "Seat Auto OFF" 1 "Seat Auto ON" 0 "No display";
VAL_ 1553 FrontRightSeatAutoDisplay 3 "Not used" 2 "Seat Auto OFF" 1 "Seat Auto ON" 0 "No display";
VAL_ 1553 ThirdRowLeftSeatAutoDisplay 3 "Not used" 2 "Seat Auto OFF" 1 "Seat Auto ON" 0 "No display";
VAL_ 1553 ThirdRowRightSeatDisplayStatus 1 "Function available" 0 "Function not available";
VAL_ 1553 ThirdRowLeftSeatDisplayStatus 1 "Function available" 0 "Function not available";
VAL_ 1553 ThirdRowRightSeatAutoDisplay 3 "Not used" 2 "Seat Auto OFF" 1 "Seat Auto ON" 0 "No display";
VAL_ 1553 SecondRowRightSeatDisplayStatus 1 "Function available" 0 "Function not available";
VAL_ 1553 SecondRowLeftSeatDisplayStatus 1 "Function available" 0 "Function not available";
VAL_ 1553 ClimCabinTempDisplayUnit 1 "display mode in °F" 0 "display mode in °C";
VAL_ 1553 ClimLastFuncModifiedByCustomer_v2 15 "Steering Wheel Heater " 14 "Sync" 13 "Front defrost" 12 "Auto Recycling" 11 "AC" 10 "Auto" 9 "Seat heating / ventilating" 8 "Blower Level" 7 "OFF Button" 6 "Forced Recycling" 5 "Flow Distribution" 4 "Clearness" 3 "Rear defrost" 2 "Not Used" 1 "Temperature" 0 "No last action";
VAL_ 1553 ClimACmaxDisplay 3 "Not Used" 2 "AC max OFF" 1 "AC max ON" 0 "No display";
VAL_ 1557 AWDSettingRequest2 7 "Reset Request" 6 "Mode 6" 5 "Mode 5" 4 "Mode 4" 3 "Mode 3" 2 "Mode 2" 1 "Mode 1" 0 "No request";
VAL_ 1557 APAStart_SwitchRequest 1 "Switch pushed" 0 "Switch released";
VAL_ 1557 AirConditioningRequest 3 "Unavailable" 2 "Mode HVAC 2 Eco" 1 "Mode HVAC 1 Normal" 0 "No request";
VAL_ 1557 LongSwitchRequest_AVM 1 "Long Switch press detected" 0 "Long Switch press not detected";
VAL_ 1558 SwitchRequest_Trailer 1 "Switch pushed" 0 "Switch released";
VAL_ 1558 FAP_ScreenPressedDetected_2 3 "Not Used" 2 "Invalid" 1 "Detected" 0 "Not detected";
VAL_ 1558 ClimateDriverSetting 3 "Not Used" 2 "No Climate AutoMode" 1 "Climate AutoMode" 0 "Defog priority";
VAL_ 1558 APA_SwitchRequest 1 "Switch pushed" 0 "Switch released";
VAL_ 1558 ADL3_DisclaimerResponse 3 "Not used" 2 "Dismissed" 1 "Accepted" 0 "No response";
VAL_ 1567 ESE_Soundtype_State 15 "Unavailable" 14 "Not used" 13 "Not used" 12 "Not used" 11 "Not used" 10 "Not used" 9 "Not used" 8 "RSound6" 7 "RSound5" 6 "RSound4" 5 "RSound3" 4 "RSound2" 3 "RSound1" 2 "Sound2" 1 "Sound1" 0 "Neutral";
VAL_ 1567 Sound3DActivationState 1 "Deactivated" 0 "Activated";
VAL_ 1567 AudioPilotActivationState 1 "Deactivated" 0 "Activated";
VAL_ 1567 ESE_Soundvolume_State 31 "Unavailable" 30 "Not used" 29 "Not used" 28 "Not used" 27 "Not used" 26 "Not used" 25 "Not used" 24 "Not used" 23 "Not used" 22 "Not used" 21 "Not used" 20 "Not used" 19 "Not used" 18 "Not used" 17 "Not used" 16 "14" 15 "13" 14 "12" 13 "11" 12 "10" 11 "9" 10 "8" 9 "7" 8 "6" 7 "5" 6 "4" 5 "3" 4 "2" 3 "1" 2 "High" 1 "Low" 0 "0";
VAL_ 1570 ModeEcoIncitationPrompt 1 "Ecomode incitation request" 0 "No Ecomode incitation request";
VAL_ 1570 ChargeProhibitionByRentalDisplay 1 "Charge is prohibited" 0 "Charge is not prohibited";
VAL_ 1570 ChargeTimeIndexReachibilityFbk 15 "Not used" 14 "Not used" 13 "Not used" 12 "Not used" 11 "Not used" 10 "Not used" 9 "Not used" 8 "Index Data 8" 7 "Index Data 7" 6 "Index Data 6" 5 "Index Data 5" 4 "Index Data 4" 3 "Index Data 3" 2 "Index Data 2" 1 "Index Data 1" 0 "No Index Data";
VAL_ 1570 ChargingAlert_v2 15 "Not used" 14 "Not used" 13 "Not used" 12 "Not used" 11 "Not used" 10 "Not used" 9 "Interruption due to Change profile renegotiation" 8 "Battery full" 7 "Prohibition battery rental" 6 "Charge failure" 5 "Start driving charge interruption" 4 "Out of Park Position charge interruption" 3 "Programmed charge interruption" 2 "Unplug charging cable (EV and/or Spot Side)" 1 "Plug Unlocking" 0 "No alert";
VAL_ 1570 ElectricalTractionAvailability 3 "Not used" 2 "EV traction not available" 1 "EV traction soon not available" 0 "EV traction available";
VAL_ 1570 ChargeAvailable 1 "Charge available" 0 "Charge not available ";
VAL_ 1578 DMC_ActivationState 3 "Unavailable" 2 "Not Used" 1 "Activated" 0 "Deactivated";
VAL_ 1578 Drowsy_AlertActivationState 3 "Not used" 2 "Deactivated" 1 "Activated" 0 "Unavailable";
VAL_ 1593 ITM_FrontRearDefrostTypeConfig 7 "FR DEF MAX + HFS" 6 "FR DEF MAX + RR DEF + HFS" 5 "FR DEF MAX + RR DEF" 4 "FR DEF MAX" 3 "FR DEF + HFS" 2 "FR DEF + RR DEF + HFS" 1 "FR DEF + RR DEF" 0 "FR DEF";
VAL_ 1593 ITM_ControlPanelTypeConfig 1 "exists" 0 "not exist";
VAL_ 1593 ITM_TempControlTypeConfig 3 "4zone" 2 "Tri-zone" 1 "dual" 0 "single";
VAL_ 1593 ITM_TempRangeMinMaxConfig 1 "MAX" 0 "MIN";
VAL_ 1593 ITM_VariableAirFlowConfig 1 "exists" 0 "not exist";
VAL_ 1593 ITM_DriverZoneConfig 1 "driver only" 0 "not exist";
VAL_ 1593 ITM_SyncModeTypeConfig 7 "not used" 6 "not used" 5 "not used" 4 "passenger and rear and rear passenger" 3 "rear" 2 "passenger and rear" 1 "passenger" 0 "no sync switch";
VAL_ 1593 ITM_FlowDistrTypeConfig 3 "4zone" 2 "Tri-zone" 1 "dual" 0 "single";
VAL_ 1593 ITM_BlowingZoneTypeConfig 3 "4zone" 2 "Tri-zone" 1 "dual" 0 "single";
VAL_ 1593 ITM_HumiditySensorConfig 1 "exists" 0 "not exist";
VAL_ 1593 ITM_ACControlTypeConfig 3 "Not used" 2 "Fr & Rr A/C SW" 1 "Fr A/C SW" 0 "no A/C SW";
VAL_ 1593 ITM_AutoControlTypeConfig 7 "not used" 6 "not used" 5 "not used" 4 "4 zone" 3 "tri zone" 2 "Dual" 1 "single" 0 "no AUTO";
VAL_ 1593 ITM_IdleStopHVACPriorityConfig 1 "exists" 0 "not exist";
VAL_ 1593 ITM_ForestConfig 1 "forest" 0 "not forest";
VAL_ 1593 ITM_AromaConfig 1 "exists" 0 "not exist";
VAL_ 1593 ITM_AQSMaxLevelConfig 7 "Not used" 6 "Not used" 5 "Level 5" 4 "Level 4" 3 "Level 3" 2 "Level 2" 1 "Level 1" 0 "No function";
VAL_ 1593 ITM_RecyclingTypeConfig 7 "NOT USED" 6 "NOT USED" 5 "REC & FRE & AUTO INTAKE" 4 "REC & AUTO INTAKE" 3 "REC & FRE & CLEAN" 2 "REC & CLEAN" 1 "REC & FRE" 0 "REC";
VAL_ 1593 ITM_TrimHeaterConfig 1 "exists" 0 "not exist";
VAL_ 1593 ITM_AirScarfConfig 1 "exists" 0 "not exist";
VAL_ 1593 ITM_FrontSeatHeatVentilConfig 3 "Not used" 2 "heater & ventilation" 1 "heater" 0 "no seat heater";
VAL_ 1593 ITM_SecondRowSeatHeatVentConfig 3 "not used" 2 "heater & ventilation" 1 "heater" 0 "no seat heater";
VAL_ 1593 ITM_ThirdRowSeatHeatVentConfig 3 "not used" 2 "heater & ventilation" 1 "heater" 0 "no seat heater";
VAL_ 1593 ITM_IRsensorConfig 1 "exists" 0 "not exist";
VAL_ 1593 ITM_AirQualitySensorConfig 1 "exists" 0 "not exist";
VAL_ 1594 ITM_EVHeaterControlConfig 1 "exists" 0 "not exist";
VAL_ 1594 ITM_HeatedSteeringWheelConfig 3 "not used" 2 "exists and AUTO function" 1 "exists" 0 "not exist";
VAL_ 1595 TrailerGuidelineActivationRequest 3 "Reset Request" 2 "Deactivation Request" 1 "Activation Request" 0 "No Request";
VAL_ 1595 AmbientLightingColor_v2 127 "Color 128" 126 "Color 127" 125 "Color 126" 124 "Color 125" 123 "Color 124" 122 "Color 123" 121 "Color 122" 120 "Color 121" 119 "Color 120" 118 "Color 119" 117 "Color 118" 116 "Color 117" 115 "Color 116" 114 "Color 115" 113 "Color 114" 112 "Color 113" 111 "Color 112" 110 "Color 111" 109 "Color 110" 108 "Color 109" 107 "Color 108" 106 "Color 107" 105 "Color 106" 104 "Color 105" 103 "Color 104" 102 "Color 103" 101 "Color 102" 100 "Color 101" 99 "Color 100" 98 "Color 99" 97 "Color 98" 96 "Color 97" 95 "Color 96" 94 "Color 95" 93 "Color 94" 92 "Color 93" 91 "Color 92" 90 "Color 91" 89 "Color 90" 88 "Color 89" 87 "Color 88" 86 "Color 87" 85 "Color 86" 84 "Color 85" 83 "Color 84" 82 "Color 83" 81 "Color 82" 80 "Color 81" 79 "Color 80" 78 "Color 79" 77 "Color 78" 76 "Color 77" 75 "Color 76" 74 "Color 75" 73 "Color 74" 72 "Color 73" 71 "Color 72" 70 "Color 71" 69 "Color 70" 68 "Color 69" 67 "Color 68" 66 "Color 67" 65 "Color 66" 64 "Color 65" 63 "Color 64" 62 "Color 63" 61 "Color 62" 60 "Color 61" 59 "Color 60" 58 "Color 59" 57 "Color 58" 56 "Color 57" 55 "Color 56" 54 "Color 55" 53 "Color 54" 52 "Color 53" 51 "Color 52" 50 "Color 51" 49 "Color 50" 48 "Color 49" 47 "Color 48" 46 "Color 47" 45 "Color 46" 44 "Color 45" 43 "Color 44" 42 "Color 43" 41 "Color 42" 40 "Color 41" 39 "Color 40" 38 "Color 39" 37 "Color 38" 36 "Color 37" 35 "Color 36" 34 "Color 35" 33 "Color 34" 32 "Color 33" 31 "Color 32" 30 "Color 31" 29 "Color 30" 28 "Color 29" 27 "Color 28" 26 "Color 27" 25 "Color 26" 24 "Color 25" 23 "Color 24" 22 "Color 23" 21 "Color 22" 20 "Color 21" 19 "Color 20" 18 "Color 19" 17 "Color 18" 16 "Color 17" 15 "Color 16" 14 "Color 15" 13 "Color 14" 12 "Color 13" 11 "Color 12" 10 "Color 11" 9 "Color 10" 8 "Color 9" 7 "Color 8" 6 "Color 7" 5 "Color 6" 4 "Color 5" 3 "Color 4" 2 "Color 3" 1 "Color 2" 0 "Color 1";
VAL_ 1595 HUD_RotationPositionRequest2 31 "Not Used" 30 "Not Used" 29 "Not Used" 28 "Not Used" 27 "Not Used" 26 "Not Used" 25 "Not Used" 24 "Not Used" 23 "Not Used" 22 "Reset Request" 21 "step 21" 20 "step 20" 19 "step 19" 18 "step 18" 17 "step 17" 16 "step 16" 15 "step 15" 14 "step 14" 13 "step 13" 12 "step 12" 11 "step 11" 10 "step 10" 9 "step 9" 8 "step 8" 7 "step 7" 6 "step 6" 5 "step 5" 4 "step 4" 3 "step 3" 2 "step 2" 1 "step 1" 0 "No Request";
VAL_ 1595 AVM_GuidelinesActivationRequest2 7 "Not Used" 6 "Not Used" 5 "Reset Request" 4 "Static and Dynamic Guideline Activation Request" 3 "Dynamic Guideline Activation Request" 2 "Static Guideline Activation Request" 1 "Static and Dynamic Guideline Deactivation Request" 0 "No Request";
VAL_ 1595 OffsetValue_Request2 31 "Not used" 30 "Not used" 29 "Not used" 28 "Not used" 27 "Not used" 26 "Not used" 25 "Not used" 24 "Not used" 23 "Not used" 22 "Reset Request" 21 "10" 20 "9" 19 "8" 18 "7" 17 "6" 16 "5" 15 "4" 14 "3" 13 "2" 12 "1" 11 "0" 10 "-1" 9 "-2" 8 "-3" 7 "-4" 6 "-5" 5 "-6" 4 "-7" 3 "-8" 2 "-9" 1 "-10" 0 "No Request";
VAL_ 1595 AmbientLightingAreaADReq 3 "Reset Request" 2 "AmbientLighting AD not requested" 1 "AmbientLighting AD requested" 0 "No Request";
VAL_ 1595 VolumAlarmActivationRequest2 7 "Reset Request" 6 "Not used" 5 "Not used" 4 "Deactivation Request" 3 "Deactivation Once Request" 2 "Ask On Exit Request" 1 "Activation Request" 0 "No Request";
VAL_ 1595 ContextSpeed_ActivationRequest2 7 "Not Used" 6 "Not Used" 5 "Not Used" 4 "Reset Request" 3 "Prompt mode activation Request" 2 "Auto mode activation Request" 1 "OFF" 0 "No Request";
VAL_ 1595 PreferedLaneAssist_Request2 3 "Reset Request" 2 "LKA" 1 "LDW" 0 "No request";
VAL_ 1595 OffsetActivation_Request2 3 "Reset request" 2 "Deactivation  request" 1 "Activation request" 0 "No request";
VAL_ 1595 FOTA_ProgRequest 3 "Not Used" 2 "Cancel Request" 1 "Timer Request" 0 "No Request";
VAL_ 1595 ContextRoad_ActivationRequest2 3 "Reset Request" 2 "ON" 1 "OFF" 0 "No request";
VAL_ 1595 Drowsy_AlertActivationRequest2 3 "Reset request" 2 "Drowsy alert deactivation" 1 "Drowsy alert activation" 0 "No request";
VAL_ 1595 RearViewRVC_CancelReason_RER 1 "Reemission request" 0 "No request";
VAL_ 1595 ZoomAutoActivationRequest2 3 "Reset Request" 2 "Zoom auto Activation Request" 1 "Zoom auto Deactivation Request" 0 "No Request";
VAL_ 1595 RearViewRVC_CancelReason 3 "Not Used" 2 "RearView Camera permanent failure" 1 "RearView Camera is blocked" 0 "No display";
VAL_ 1595 HVbatteryWarmingRequest 3 "Reset request" 2 "Battery warming ON request" 1 "Battery warming OFF request" 0 "No request";
VAL_ 1595 OSE_ActivationRequest2 3 "Reset request" 2 "Deactivation request" 1 "Activation request" 0 "No request";
VAL_ 1595 DMC_ActivationRequest2 3 "Reset request" 2 "DMC deactivation" 1 "DMC activation" 0 "No request";
VAL_ 1595 VirtualKeyActivationRequest 3 "Virtual Key Factory setting reset requested" 2 "Virtual Key DeActivation Requested" 1 "Virtual Key Activation Requested" 0 "No Request";
VAL_ 1596 NextTurnProximityDetected 1 "Navigation picture requested" 0 "No requested";
VAL_ 1596 CurrentAudioState 3 "Not used" 2 "Mute audio" 1 "Update list signal" 0 "Normal listening";
VAL_ 1596 CurrentRadioFavorite 1 "Favorite radio selected" 0 "No favorite radio selected";
VAL_ 1596 CurrentPhoneStatus 7 "Not used" 6 "Not used" 5 "Not used" 4 "Manual put on hold" 3 "Automatic put on hold" 2 "Call on going" 1 "Incoming call" 0 "No call on going";
VAL_ 1596 CurrentAudioSource_v2 15 "other sources" 14 "AndroidAuto" 13 "CarPlay" 12 "DTV" 11 "Blu-Ray" 10 "DVD" 9 "USB2" 8 "USB1" 7 "IPod" 6 "Aux" 5 "SD" 4 "BT" 3 "CD MP3" 2 "CD DA" 1 "Radio" 0 "All Off";
VAL_ 1596 CurrentRadioBand_v2 7 "Not used" 6 "Not used" 5 "Not used" 4 "HD Radio" 3 "SXM" 2 "Digital radio" 1 "AM" 0 "FM";
VAL_ 1596 AutoDimmingRequest 3 "Reset request" 2 "AutoDimming Activated" 1 "AutoDimming Not activated" 0 "No request";
VAL_ 1596 PnCactivationRequest_IVI 3 "Not Used" 2 "Desactivation request" 1 "Activation request" 0 "No request";
VAL_ 1596 TCS_DeactivationRequest2 3 "Not used" 2 "TCS activation request" 1 "TCS deactivation request" 0 "No request";
VAL_ 1596 HDC_ActivationRequest2 3 "Unavailable" 2 "Reset requested" 1 "HDC requested" 0 "HDC not requested";
VAL_ 1596 ClusterSkinRequest_v2 15 "Reset Request" 14 "not used" 13 "not used" 12 "not used" 11 "Skin11" 10 "Skin10" 9 "Skin9" 8 "Skin8" 7 "Skin7" 6 "Skin6" 5 "Skin5" 4 "Skin4" 3 "Skin3" 2 "Skin2" 1 "Skin1" 0 "No Request";
VAL_ 1596 SC_DepartureTimeWeekDay 7 "unavailable" 6 "Sunday" 5 "Saturday" 4 "Friday" 3 "Thursday" 2 "Wednesday" 1 "Tuesday" 0 "Monday";
VAL_ 1599 CTA_ActivationState 1 "Deactivated" 0 "Activated";
VAL_ 1616 APA_WarningDisplayRequest2 63 "Not used" 62 "message62" 61 "message61" 60 "message60" 59 "message59" 58 "message58" 57 "message57" 56 "message56" 55 "message55" 54 "message54" 53 "message53" 52 "message52" 51 "message51" 50 "message50" 49 "message49" 48 "message48" 47 "message47" 46 "message46" 45 "message45" 44 "message44" 43 "message43" 42 "message42" 41 "message41" 40 "message40" 39 "message39" 38 "message38" 37 "message37" 36 "message36" 35 "message35" 34 "message34" 33 "message33" 32 "message32" 31 "message31" 30 "message30" 29 "message29" 28 "message28" 27 "message27" 26 "message26" 25 "message25" 24 "message24" 23 "message23" 22 "message22" 21 "message21" 20 "message20" 19 "message19" 18 "message18" 17 "message17" 16 "message16" 15 "message15" 14 "message14" 13 "message13" 12 "message12" 11 "message11" 10 "message10" 9 "message9" 8 "message8" 7 "message7" 6 "message6" 5 "message5" 4 "message4" 3 "message3" 2 "message2" 1 "message1" 0 "no message";
VAL_ 1616 APA_ScanInfo2 7 "Not used" 6 "Not used" 5 "Not used" 4 "SlotLeftRight" 3 "SlotRight" 2 "SlotLeft" 1 "Scan" 0 "No display";
